VERSION ""

NS_ :

BS_:

BU_: CH DIPF DIPR ETH FC HVI HVS PARTY SDCV VEH VIRT

BO_ 568 UI_driverAssistMapData: 8 CH
 SG_ UI_mapDataChecksum : 56|8@1+ (1,0) [0|255] ""  das
 SG_ UI_mapDataCounter : 52|4@1+ (1,0) [0|15] ""  das
 SG_ UI_scaEnabled : 51|1@1+ (1,0) [0|1] ""  das
 SG_ UI_pmmEnabled : 50|1@1+ (1,0) [0|1] ""  das
 SG_ UI_autosteerRestricted : 49|1@1+ (1,0) [0|1] ""  das
 SG_ UI_acceptBottsDots : 48|1@1+ (1,0) [0|1] ""  das
 SG_ UI_rejectHandsOn : 47|1@1+ (1,0) [0|1] ""  das
 SG_ UI_rejectAutosteer : 46|1@1+ (1,0) [0|1] ""  das
 SG_ UI_rejectRightFreeSpace : 45|1@1+ (1,0) [0|1] ""  das
 SG_ UI_rejectLeftFreeSpace : 44|1@1+ (1,0) [0|1] ""  das
 SG_ UI_rejectNav : 43|1@1+ (1,0) [0|1] ""  das
 SG_ UI_rejectHPP : 42|1@1+ (1,0) [0|1] ""  das
 SG_ UI_rejectRightLane : 41|1@1+ (1,0) [0|1] ""  das
 SG_ UI_rejectLeftLane : 40|1@1+ (1,0) [0|1] ""  das
 SG_ UI_nextBranchRightOffRamp : 39|1@1+ (1,0) [0|1] ""  das
 SG_ UI_nextBranchLeftOffRamp : 38|1@1+ (1,0) [0|1] ""  das
 SG_ UI_controlledAccess : 37|1@1+ (1,0) [0|1] ""  das
 SG_ UI_nextBranchDist : 32|5@1+ (10,0) [0|300] "m"  das
 SG_ UI_perpendicularAutoparkEnabled : 31|1@1+ (1,0) [0|1] ""  das
 SG_ UI_parallelAutoparkEnabled : 30|1@1+ (1,0) [0|1] ""  das
 SG_ UI_navRouteActive : 29|1@1+ (1,0) [0|1] ""  das
 SG_ UI_gpsRoadMatch : 28|1@1+ (1,0) [0|1] ""  das
 SG_ UI_streetCount : 26|2@1+ (1,0) [0|3] ""  das
 SG_ UI_countryCode : 16|10@1+ (1,0) [0|1023] ""  das
 SG_ UI_mapSpeedLimitType : 13|3@1+ (1,0) [0|7] ""  das
 SG_ UI_mapSpeedLimit : 8|5@1+ (1,0) [0|31] ""  das
 SG_ UI_mapSpeedUnits : 7|1@1+ (1,0) [0|1] ""  das
 SG_ UI_inSuperchargerGeofence : 6|1@1+ (1,0) [0|1] ""  das
 SG_ UI_roadClass : 3|3@1+ (1,0) [0|6] ""  das
 SG_ UI_mapSpeedLimitDependency : 0|3@1+ (1,0) [0|7] ""  das

BO_ 945 DAS_telemetryFurniture: 8 CH
 SG_ DAS_TF_isTeslaMain m1 : 60|1@1+ (1,0) [0|1] ""  gtw
 SG_ DAS_TF_isMain m1 : 59|1@1+ (1,0) [0|1] ""  gtw
 SG_ DAS_TF_transmissionStatus m1 : 57|2@1+ (1,0) [0|3] ""  gtw
 SG_ DAS_TF_orientation m1 : 55|2@1+ (1,0) [0|3] ""  gtw
 SG_ DAS_TF_shape m1 : 52|3@1+ (1,0) [0|7] ""  gtw
 SG_ DAS_TF_color m1 : 49|3@1+ (1,0) [0|7] ""  gtw
 SG_ DAS_TF_furnitureType m0 : 42|3@1+ (1,0) [0|7] ""  gtw
 SG_ DAS_TF_ttc m2 : 39|7@1+ (0.1,0) [0|12.7] "s"  gtw
 SG_ DAS_TF_timeOfDay m0 : 39|3@1+ (1,0) [0|7] ""  gtw
 SG_ DAS_TF_height m1 : 37|12@1+ (0.05,0) [0|204.75] "m"  gtw
 SG_ DAS_TF_cipvDist m0 : 30|9@1+ (0.1,0) [0|51.1] "m"  gtw
 SG_ DAS_TF_stopLineDist m2 : 28|11@1+ (0.1,-10) [-10|194.7] "m"  gtw
 SG_ DAS_TF_rlType m0 : 27|3@1+ (1,0) [0|7] ""  gtw
 SG_ DAS_TF_lateralDist m1 : 25|12@1+ (0.1,-204.8) [-204.8|204.7] "m"  gtw
 SG_ DAS_TF_llType m0 : 24|3@1+ (1,0) [0|7] ""  gtw
 SG_ DAS_TF_juncDist m2 : 17|11@1+ (0.2,-20) [-20|389.4] "m"  gtw
 SG_ DAS_TF_juncStatus m2 : 13|4@1+ (1,0) [0|15] ""  gtw
 SG_ DAS_TF_longitudinalDist m1 : 13|12@1+ (0.1,0) [0|409.5] "m"  gtw
 SG_ DAS_TF_distTraveled m0 : 13|11@1+ (0.1,0) [0|204.7] "m"  gtw
 SG_ DAS_TF_furnitureIndex2 m2 : 5|8@1+ (1,0) [0|255] ""  gtw
 SG_ DAS_TF_furnitureIndex1 m1 : 5|8@1+ (1,0) [0|255] ""  gtw
 SG_ DAS_TF_furnitureIndex0 m0 : 5|8@1+ (1,0) [0|255] ""  gtw
 SG_ DAS_TF_multiplexer M : 0|5@1+ (1,0) [0|2] ""  gtw

BO_ 952 UI_tpmsRCPsetting: 8 CH
 SG_ UI_setRCPRear : 24|8@1+ (0.025,0) [0|6.375] "bar"  tpms
 SG_ UI_setRCPFront : 16|8@1+ (0.025,0) [0|6.375] "bar"  tpms

BO_ 1282 RADC_alertMatrix0: 8 CH
 SG_ RADC_a055_blockageInfo_Frame_2 : 55|1@1+ (1,0) [0|1] ""  gtw
 SG_ RADC_a054_blockageInfo_Frame_1 : 54|1@1+ (1,0) [0|1] ""  gtw
 SG_ RADC_a053_emError : 53|1@1+ (1,0) [0|1] ""  gtw
 SG_ RADC_a052_mismatcRadPos : 52|1@1+ (1,0) [0|1] ""  gtw
 SG_ RADC_a051_mismatchEPASType : 51|1@1+ (1,0) [0|1] ""  gtw
 SG_ RADC_a050_mismatchCountry : 50|1@1+ (1,0) [0|1] ""  gtw
 SG_ RADC_a049_mismatchFourWheelDrive : 49|1@1+ (1,0) [0|1] ""  gtw
 SG_ RADC_a048_mismatchAirSuspension : 48|1@1+ (1,0) [0|1] ""  gtw
 SG_ RADC_a047_mismatchChassisType : 47|1@1+ (1,0) [0|1] ""  gtw
 SG_ RADC_a046_wheelSpeedsErr : 46|1@1+ (1,0) [0|1] ""  gtw
 SG_ RADC_a045_vehicleStateErr : 45|1@1+ (1,0) [0|1] ""  gtw
 SG_ RADC_a044_steeringWheelAngleErr : 44|1@1+ (1,0) [0|1] ""  gtw
 SG_ RADC_a043_inertialSignalsErr : 43|1@1+ (1,0) [0|1] ""  gtw
 SG_ RADC_a042_carConfigErr : 42|1@1+ (1,0) [0|1] ""  gtw
 SG_ RADC_a041_vinErr : 41|1@1+ (1,0) [0|1] ""  gtw
 SG_ RADC_a040_wheelSpeedsMIA : 40|1@1+ (1,0) [0|1] ""  gtw
 SG_ RADC_a039_vehicleStateMIA : 39|1@1+ (1,0) [0|1] ""  gtw
 SG_ RADC_a038_steeringWheelAngleMIA : 38|1@1+ (1,0) [0|1] ""  gtw
 SG_ RADC_a037_inertialSignalsMIA : 37|1@1+ (1,0) [0|1] ""  gtw
 SG_ RADC_a036_carConfigMIA : 36|1@1+ (1,0) [0|1] ""  gtw
 SG_ RADC_a035_vinMIA : 35|1@1+ (1,0) [0|1] ""  gtw
 SG_ RADC_a034_vehDynamicsError : 34|1@1+ (1,0) [0|1] ""  gtw
 SG_ RADC_a033_sensorNeverAligned : 33|1@1+ (1,0) [0|1] ""  gtw
 SG_ RADC_a032_sensorBlocked : 32|1@1+ (1,0) [0|1] ""  gtw
 SG_ RADC_a031_sensorMisaligned : 31|1@1+ (1,0) [0|1] ""  gtw
 SG_ RADC_a030_rspError : 30|1@1+ (1,0) [0|1] ""  gtw
 SG_ RADC_a029_rhcError : 29|1@1+ (1,0) [0|1] ""  gtw
 SG_ RADC_a028_rfChipError : 28|1@1+ (1,0) [0|1] ""  gtw
 SG_ RADC_a027_nvmFailure : 27|1@1+ (1,0) [0|1] ""  gtw
 SG_ RADC_a026_underVoltage : 26|1@1+ (1,0) [0|1] ""  gtw
 SG_ RADC_a025_overVoltage : 25|1@1+ (1,0) [0|1] ""  gtw
 SG_ RADC_a024_underTempCrit : 24|1@1+ (1,0) [0|1] ""  gtw
 SG_ RADC_a023_underTemp : 23|1@1+ (1,0) [0|1] ""  gtw
 SG_ RADC_a022_tempImplausible : 22|1@1+ (1,0) [0|1] ""  gtw
 SG_ RADC_a021_overTempCrit : 21|1@1+ (1,0) [0|1] ""  gtw
 SG_ RADC_a020_overTemp : 20|1@1+ (1,0) [0|1] ""  gtw
 SG_ RADC_a019_internalSoftwareFault : 19|1@1+ (1,0) [0|1] ""  gtw
 SG_ RADC_a018_internalHardwareFault : 18|1@1+ (1,0) [0|1] ""  gtw
 SG_ RADC_a017_adcUnderVolt : 17|1@1+ (1,0) [0|1] ""  gtw
 SG_ RADC_a016_adcOverVolt : 16|1@1+ (1,0) [0|1] ""  gtw
 SG_ RADC_a015_fctSenInterference : 15|1@1+ (1,0) [0|1] ""  gtw
 SG_ RADC_a014_fctSelfTestNotDone : 14|1@1+ (1,0) [0|1] ""  gtw
 SG_ RADC_a013_ecuWdgError : 13|1@1+ (1,0) [0|1] ""  gtw
 SG_ RADC_a012_ecuSpiError : 12|1@1+ (1,0) [0|1] ""  gtw
 SG_ RADC_a011_ecuMcemError : 11|1@1+ (1,0) [0|1] ""  gtw
 SG_ RADC_a010_ecuIoHwAbError : 10|1@1+ (1,0) [0|1] ""  gtw
 SG_ RADC_a009_plantModeActive : 9|1@1+ (1,0) [0|1] ""  gtw
 SG_ RADC_a008_ecuHwSwInterlock : 8|1@1+ (1,0) [0|1] ""  gtw
 SG_ RADC_a007_ecuGptCheckError : 7|1@1+ (1,0) [0|1] ""  gtw
 SG_ RADC_a006_ecuFimError : 6|1@1+ (1,0) [0|1] ""  gtw
 SG_ RADC_a005_ecuEcuMError : 5|1@1+ (1,0) [0|1] ""  gtw
 SG_ RADC_a004_ecuCrcHwError : 4|1@1+ (1,0) [0|1] ""  gtw
 SG_ RADC_a003_ecuBistDisabled : 3|1@1+ (1,0) [0|1] ""  gtw
 SG_ RADC_a002_ecuAdcError : 2|1@1+ (1,0) [0|1] ""  gtw
 SG_ RADC_a001_can1BusOff : 1|1@1+ (1,0) [0|1] ""  gtw

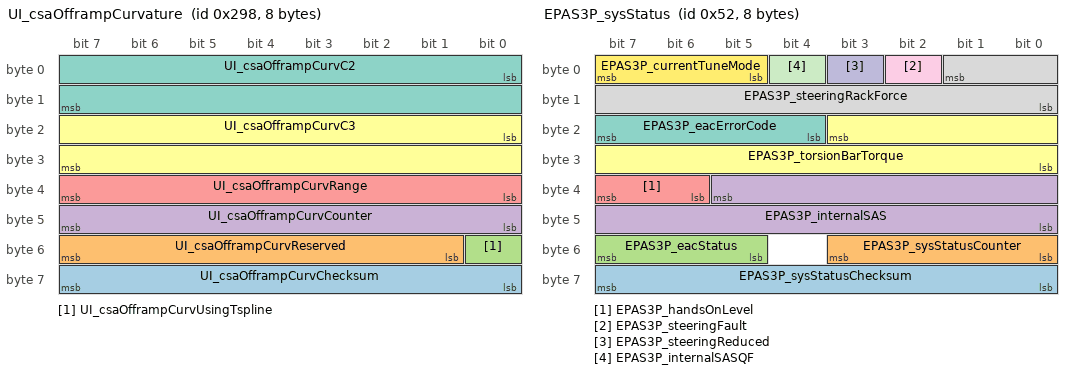
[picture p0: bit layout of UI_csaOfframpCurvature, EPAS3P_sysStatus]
BO_ 664 UI_csaOfframpCurvature: 8 CH
 SG_ UI_csaOfframpCurvChecksum : 56|8@1+ (1,0) [0|255] ""  X
 SG_ UI_csaOfframpCurvReserved : 49|7@1+ (1,0) [0|127] ""  X
 SG_ UI_csaOfframpCurvUsingTspline : 48|1@1+ (1,0) [0|1] ""  das
 SG_ UI_csaOfframpCurvCounter : 40|8@1+ (1,0) [0|255] ""  X
 SG_ UI_csaOfframpCurvRange : 32|8@1+ (2,0) [0|510] "m"  das
 SG_ UI_csaOfframpCurvC3 : 16|16@1- (4e-09,0.0) [-0.000131072|0.000131068] "1/m2"  das
 SG_ UI_csaOfframpCurvC2 : 0|16@1- (1e-06,0.0) [-0.032768|0.032767] "1/m"  das

BO_ 1535 TPMS_bootID: 8 CH
 SG_ TPMS_bootIdData : 0|64@1+ (1,0) [0|18446744073709551615] ""  gtwu

BO_ 1630 PARK_udsResponse: 8 CH
 SG_ PARK_udsResponseData : 0|64@1+ (1,0) [0|18446744073709551615] ""  gtw

BO_ 881 RCM_alertMatrix: 8 CH
 SG_ RCM_a059_buckle1stRowRight m0 : 63|1@1+ (1,0) [0|1] ""  gtw
 SG_ RCM_a058_buckle1stRowLeft m0 : 62|1@1+ (1,0) [0|1] ""  gtw
 SG_ RCM_a118_imuInPlaneAcceleration m1 : 62|1@1+ (1,0) [0|1] ""  gtw
 SG_ RCM_a057_driverOCS m0 : 61|1@1+ (1,0) [0|1] ""  gtw
 SG_ RCM_a117_imuVerticalAcceleration m1 : 61|1@1+ (1,0) [0|1] ""  gtw
 SG_ RCM_a116_imuLateralAcceleration m1 : 60|1@1+ (1,0) [0|1] ""  gtw
 SG_ RCM_a056_passengerFrontOCS m0 : 60|1@1+ (1,0) [0|1] ""  gtw
 SG_ RCM_a115_imuLinearAcceleration m1 : 59|1@1+ (1,0) [0|1] ""  gtw
 SG_ RCM_a055_inertialMeasurement m0 : 59|1@1+ (1,0) [0|1] ""  gtw
 SG_ RCM_a054_pressurePedProRight m0 : 58|1@1+ (1,0) [0|1] ""  gtw
 SG_ RCM_a114_imuRollRate m1 : 58|1@1+ (1,0) [0|1] ""  gtw
 SG_ RCM_a053_pressurePedProLeft m0 : 57|1@1+ (1,0) [0|1] ""  gtw
 SG_ RCM_a113_imuPitchRate m1 : 57|1@1+ (1,0) [0|1] ""  gtw
 SG_ RCM_a112_imuYawRate m1 : 56|1@1+ (1,0) [0|1] ""  gtw
 SG_ RCM_a052_pressureFrontRtDoor m0 : 56|1@1+ (1,0) [0|1] ""  gtw
 SG_ RCM_a111_diagnosticsEnabled m1 : 55|1@1+ (1,0) [0|1] ""  gtw
 SG_ RCM_a051_pressureFrontLftDoor m0 : 55|1@1+ (1,0) [0|1] ""  gtw
 SG_ RCM_a050_upFrontSensorCenter m0 : 54|1@1+ (1,0) [0|1] ""  gtw
 SG_ RCM_a110_factoryMode m1 : 54|1@1+ (1,0) [0|1] ""  gtw
 SG_ RCM_a109_abuseImmunity m1 : 53|1@1+ (1,0) [0|1] ""  gtw
 SG_ RCM_a049_sideAccelCPillarRight m0 : 53|1@1+ (1,0) [0|1] ""  gtw
 SG_ RCM_a108_crashAlgoWakeup m1 : 52|1@1+ (1,0) [0|1] ""  gtw
 SG_ RCM_a048_sideAccelCPillarLeft m0 : 52|1@1+ (1,0) [0|1] ""  gtw
 SG_ RCM_a047_sideAccelBPillarRight m0 : 51|1@1+ (1,0) [0|1] ""  gtw
 SG_ RCM_a107_imuVertAccOffstCompLim m1 : 51|1@1+ (1,0) [0|1] ""  gtw
 SG_ RCM_a106_imuLatAccOffstCompLim m1 : 50|1@1+ (1,0) [0|1] ""  gtw
 SG_ RCM_a046_sideAccelBPillarLeft m0 : 50|1@1+ (1,0) [0|1] ""  gtw
 SG_ RCM_a105_imuLongAccOffstCompLim m1 : 49|1@1+ (1,0) [0|1] ""  gtw
 SG_ RCM_a045_upFrontSensorRight m0 : 49|1@1+ (1,0) [0|1] ""  gtw
 SG_ RCM_a104_imuRollR8OffstCompLim m1 : 48|1@1+ (1,0) [0|1] ""  gtw
 SG_ RCM_a044_upFrontSensorLeft m0 : 48|1@1+ (1,0) [0|1] ""  gtw
 SG_ RCM_a043_ens2Line m0 : 47|1@1+ (1,0) [0|1] ""  gtw
 SG_ RCM_a103_imuPtchR8OffstCompLim m1 : 47|1@1+ (1,0) [0|1] ""  gtw
 SG_ RCM_a102_imuYawR8OffstCompLim m1 : 46|1@1+ (1,0) [0|1] ""  gtw
 SG_ RCM_a042_ens1Line m0 : 46|1@1+ (1,0) [0|1] ""  gtw
 SG_ RCM_a101_idfSystem m1 : 45|1@1+ (1,0) [0|1] ""  gtw
 SG_ RCM_a041_hoodActuatorLeft m0 : 45|1@1+ (1,0) [0|1] ""  gtw
 SG_ RCM_a040_hoodActuatorRight m0 : 44|1@1+ (1,0) [0|1] ""  gtw
 SG_ RCM_a100_comDIsystemStatus m1 : 44|1@1+ (1,0) [0|1] ""  gtw
 SG_ RCM_a099_comDItorque m1 : 43|1@1+ (1,0) [0|1] ""  gtw
 SG_ RCM_a039_unusedB m0 : 43|1@1+ (1,0) [0|1] ""  gtw
 SG_ RCM_a038_unusedA m0 : 42|1@1+ (1,0) [0|1] ""  gtw
 SG_ RCM_a098_comDIchassisControl m1 : 42|1@1+ (1,0) [0|1] ""  gtw
 SG_ RCM_a097_comDIspeed m1 : 41|1@1+ (1,0) [0|1] ""  gtw
 SG_ RCM_a037_curAB2ndRowRight m0 : 41|1@1+ (1,0) [0|1] ""  gtw
 SG_ RCM_a036_curAB2ndRowLeft m0 : 40|1@1+ (1,0) [0|1] ""  gtw
 SG_ RCM_a096_comESPwheelSpeeds m1 : 40|1@1+ (1,0) [0|1] ""  gtw
 SG_ RCM_a035_preten2ndRowRight m0 : 39|1@1+ (1,0) [0|1] ""  gtw
 SG_ RCM_a095_comESPstatus m1 : 39|1@1+ (1,0) [0|1] ""  gtw
 SG_ RCM_a034_preten2ndRowLeft m0 : 38|1@1+ (1,0) [0|1] ""  gtw
 SG_ RCM_a094_comVCRIGHTStatus m1 : 38|1@1+ (1,0) [0|1] ""  gtw
 SG_ RCM_a033_curtainABRight m0 : 37|1@1+ (1,0) [0|1] ""  gtw
 SG_ RCM_a093_comVCLEFTStatus m1 : 37|1@1+ (1,0) [0|1] ""  gtw
 SG_ RCM_a092_comDASISF m1 : 36|1@1+ (1,0) [0|1] ""  gtw
 SG_ RCM_a032_curtainABLeft m0 : 36|1@1+ (1,0) [0|1] ""  gtw
 SG_ RCM_a031_frontCenterAirbag m0 : 35|1@1+ (1,0) [0|1] ""  gtw
 SG_ RCM_a091_comEPAS3PsysStatus m1 : 35|1@1+ (1,0) [0|1] ""  gtw
 SG_ RCM_a030_farSideInboardAirbag m0 : 34|1@1+ (1,0) [0|1] ""  gtw
 SG_ RCM_a090_comPartyBusOff m1 : 34|1@1+ (1,0) [0|1] ""  gtw
 SG_ RCM_a029_driverABActiveVent m0 : 33|1@1+ (1,0) [0|1] ""  gtw
 SG_ RCM_a089_comCHCANPH3 m1 : 33|1@1+ (1,0) [0|1] ""  gtw
 SG_ RCM_a028_sideAB1stRowRight m0 : 32|1@1+ (1,0) [0|1] ""  gtw
 SG_ RCM_a088_comCHCANPH2 m1 : 32|1@1+ (1,0) [0|1] ""  gtw
 SG_ RCM_a027_sideAB1stRowLeft m0 : 31|1@1+ (1,0) [0|1] ""  gtw
 SG_ RCM_a087_comCANSilent m1 : 31|1@1+ (1,0) [0|1] ""  gtw
 SG_ RCM_a086_comVINMIA m1 : 30|1@1+ (1,0) [0|1] ""  gtw
 SG_ RCM_a026_kneeABFrontPassenger m0 : 30|1@1+ (1,0) [0|1] ""  gtw
 SG_ RCM_a025_kneeABDriver m0 : 29|1@1+ (1,0) [0|1] ""  gtw
 SG_ RCM_a085_comGTWCarConfig m1 : 29|1@1+ (1,0) [0|1] ""  gtw
 SG_ RCM_a024_loadLimiterRightSide m0 : 28|1@1+ (1,0) [0|1] ""  gtw
 SG_ RCM_a084_comTPMSStatus m1 : 28|1@1+ (1,0) [0|1] ""  gtw
 SG_ RCM_a023_loadLimiterLeftSide m0 : 27|1@1+ (1,0) [0|1] ""  gtw
 SG_ RCM_a083_comGTWCarState m1 : 27|1@1+ (1,0) [0|1] ""  gtw
 SG_ RCM_a022_pretenLapFrontRight m0 : 26|1@1+ (1,0) [0|1] ""  gtw
 SG_ RCM_a082_comUIodo m1 : 26|1@1+ (1,0) [0|1] ""  gtw
 SG_ RCM_a021_pretenLapFrontLeft m0 : 25|1@1+ (1,0) [0|1] ""  gtw
 SG_ RCM_a081_comVCFRONTLVPwr m1 : 25|1@1+ (1,0) [0|1] ""  gtw
 SG_ RCM_a080_comGTWACS m1 : 24|1@1+ (1,0) [0|1] ""  gtw
 SG_ RCM_a020_pretenShldFrontRight m0 : 24|1@1+ (1,0) [0|1] ""  gtw
 SG_ RCM_a019_pretenShldrFrontLeft m0 : 23|1@1+ (1,0) [0|1] ""  gtw
 SG_ RCM_a079_comOCS1DStatus m1 : 23|1@1+ (1,0) [0|1] ""  gtw
 SG_ RCM_a078_comOCS1PStatus m1 : 22|1@1+ (1,0) [0|1] ""  gtw
 SG_ RCM_a018_passengerActiveVent m0 : 22|1@1+ (1,0) [0|1] ""  gtw
 SG_ RCM_a077_comEPBRStatus m1 : 21|1@1+ (1,0) [0|1] ""  gtw
 SG_ RCM_a017_passABStage2 m0 : 21|1@1+ (1,0) [0|1] ""  gtw
 SG_ RCM_a016_passABStage1 m0 : 20|1@1+ (1,0) [0|1] ""  gtw
 SG_ RCM_a076_comEPBLStatus m1 : 20|1@1+ (1,0) [0|1] ""  gtw
 SG_ RCM_a075_comCHCANPH6 m1 : 19|1@1+ (1,0) [0|1] ""  gtw
 SG_ RCM_a015_driverABStage2 m0 : 19|1@1+ (1,0) [0|1] ""  gtw
 SG_ RCM_a014_driverABStage1 m0 : 18|1@1+ (1,0) [0|1] ""  gtw
 SG_ RCM_a074_comCHCANPH5 m1 : 18|1@1+ (1,0) [0|1] ""  gtw
 SG_ RCM_a073_comCHCANPH4 m1 : 17|1@1+ (1,0) [0|1] ""  gtw
 SG_ RCM_a013_driverOrientation m0 : 17|1@1+ (1,0) [0|1] ""  gtw
 SG_ RCM_a072_comUnused m1 : 16|1@1+ (1,0) [0|1] ""  gtw
 SG_ RCM_a012_vinStorage m0 : 16|1@1+ (1,0) [0|1] ""  gtw
 SG_ RCM_a011_eepromDataLocked m0 : 15|1@1+ (1,0) [0|1] ""  gtw
 SG_ RCM_a071_comCHCANPH9 m1 : 15|1@1+ (1,0) [0|1] ""  gtw
 SG_ RCM_a010_scmDisabled m0 : 14|1@1+ (1,0) [0|1] ""  gtw
 SG_ RCM_a070_comCHCANPH8 m1 : 14|1@1+ (1,0) [0|1] ""  gtw
 SG_ RCM_a069_comCHCANPH7 m1 : 13|1@1+ (1,0) [0|1] ""  gtw
 SG_ RCM_a009_reprogramLimit m0 : 13|1@1+ (1,0) [0|1] ""  gtw
 SG_ RCM_a068_comChassisBusOff m1 : 12|1@1+ (1,0) [0|1] ""  gtw
 SG_ RCM_a008_powerSupplyInternal m0 : 12|1@1+ (1,0) [0|1] ""  gtw
 SG_ RCM_a007_powerSupplyExternal m0 : 11|1@1+ (1,0) [0|1] ""  gtw
 SG_ RCM_a067_comCANInitFailure m1 : 11|1@1+ (1,0) [0|1] ""  gtw
 SG_ RCM_a006_batteryVoltageRange m0 : 10|1@1+ (1,0) [0|1] ""  gtw
 SG_ RCM_a066_seatBackSw2ndRowLeft m1 : 10|1@1+ (1,0) [0|1] ""  gtw
 SG_ RCM_a005_crcError m0 : 9|1@1+ (1,0) [0|1] ""  gtw
 SG_ RCM_a065_driverOrientConfigPin m1 : 9|1@1+ (1,0) [0|1] ""  gtw
 SG_ RCM_a064_hardwareCodingPin1 m1 : 8|1@1+ (1,0) [0|1] ""  gtw
 SG_ RCM_a004_internalFault m0 : 8|1@1+ (1,0) [0|1] ""  gtw
 SG_ RCM_a063_sbsw2ndRowRight m1 : 7|1@1+ (1,0) [0|1] ""  gtw
 SG_ RCM_a003_warningIndicator m0 : 7|1@1+ (1,0) [0|1] ""  gtw
 SG_ RCM_a002_airbagsNotArmed m0 : 6|1@1+ (1,0) [0|1] ""  gtw
 SG_ RCM_a062_alrSwitch m1 : 6|1@1+ (1,0) [0|1] ""  gtw
 SG_ RCM_a061_stpsRight m1 : 5|1@1+ (1,0) [0|1] ""  gtw
 SG_ RCM_a001_nearDeploy m0 : 5|1@1+ (1,0) [0|1] ""  gtw
 SG_ RCM_a000_crashDetected m0 : 4|1@1+ (1,0) [0|1] ""  gtw
 SG_ RCM_a060_stpsLeft m1 : 4|1@1+ (1,0) [0|1] ""  gtw
 SG_ RCM_matrixIndex M : 0|4@1+ (1,0) [0|15] ""  gtw

BO_ 82 EPAS3P_sysStatus: 8 CH
 SG_ EPAS3P_sysStatusChecksum : 63|8@0+ (1,0) [0|255] ""  park
 SG_ EPAS3P_sysStatusCounter : 51|4@0+ (1,0) [0|15] ""  park
 SG_ EPAS3P_eacStatus : 55|3@0+ (1,0) [0|7] ""  park
 SG_ EPAS3P_internalSAS : 37|14@0+ (0.1,-819.2) [-819.2|819] "deg"  park
 SG_ EPAS3P_handsOnLevel : 39|2@0+ (1,0) [0|3] ""  park
 SG_ EPAS3P_torsionBarTorque : 19|12@0+ (0.01,-20.5) [-20.5|20.45] "Nm"  park
 SG_ EPAS3P_eacErrorCode : 23|4@0+ (1,0) [0|15] ""  park
 SG_ EPAS3P_steeringRackForce : 1|10@0+ (50,-25575) [-25575|25575] "N"  park
 SG_ EPAS3P_steeringFault : 2|1@0+ (1,0) [0|1] ""  park
 SG_ EPAS3P_steeringReduced : 3|1@0+ (1,0) [0|1] ""  park
 SG_ EPAS3P_internalSASQF : 4|1@0+ (1,0) [0|1] ""  park
 SG_ EPAS3P_currentTuneMode : 7|3@0+ (1,0) [0|5] ""  park

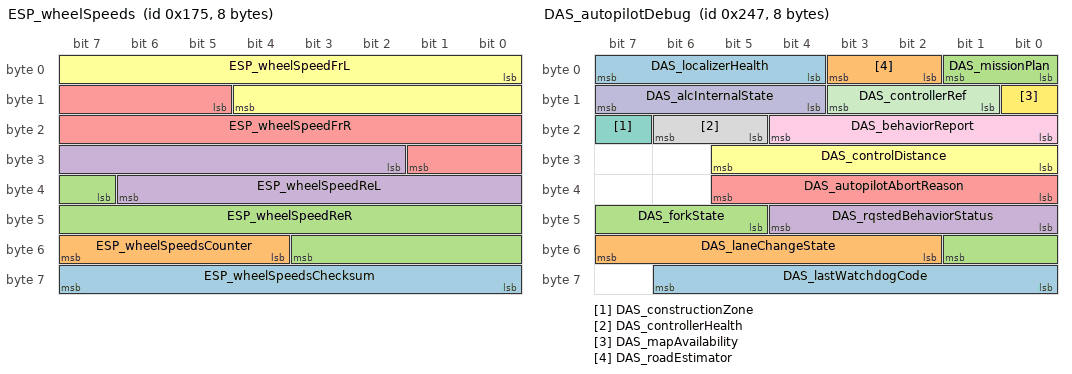
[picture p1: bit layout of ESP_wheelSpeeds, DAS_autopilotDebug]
BO_ 373 ESP_wheelSpeeds: 8 CH
 SG_ ESP_wheelSpeedsChecksum : 56|8@1+ (1,0) [0|255] ""  das
 SG_ ESP_wheelSpeedsCounter : 52|4@1+ (1,0) [0|15] ""  das
 SG_ ESP_wheelSpeedReR : 39|13@1+ (0.04,0) [0|327.64] "km/h"  das
 SG_ ESP_wheelSpeedReL : 26|13@1+ (0.04,0) [0|327.64] "km/h"  das
 SG_ ESP_wheelSpeedFrR : 13|13@1+ (0.04,0) [0|327.64] "km/h"  das
 SG_ ESP_wheelSpeedFrL : 0|13@1+ (0.04,0) [0|327.64] "km/h"  das

BO_ 873 APP_warningMatrix1: 8 CH
 SG_ APP_w106_torsionBarOffset : 41|1@1+ (1,0) [0|1] ""  gtw
 SG_ APP_w105_DEPRECATED : 40|1@1+ (1,0) [0|1] ""  gtw
 SG_ APP_w104_DEPRECATED : 39|1@1+ (1,0) [0|1] ""  gtw
 SG_ APP_w103_robExperimentalAEB : 38|1@1+ (1,0) [0|1] ""  gtw
 SG_ APP_w102_DEPRECATED : 37|1@1+ (1,0) [0|1] ""  gtw
 SG_ APP_w101_DEPRECATED : 36|1@1+ (1,0) [0|1] ""  gtw
 SG_ APP_w100_DEPRECATED : 35|1@1+ (1,0) [0|1] ""  gtw
 SG_ APP_w099_DEPRECATED : 34|1@1+ (1,0) [0|1] ""  gtw
 SG_ APP_w098_DEPRECATED : 33|1@1+ (1,0) [0|1] ""  gtw
 SG_ APP_w097_DEPRECATED : 32|1@1+ (1,0) [0|1] ""  gtw
 SG_ APP_w096_DEPRECATED : 31|1@1+ (1,0) [0|1] ""  gtw
 SG_ APP_w095_DEPRECATED : 30|1@1+ (1,0) [0|1] ""  gtw
 SG_ APP_w094_DEPRECATED : 29|1@1+ (1,0) [0|1] ""  gtw
 SG_ APP_w093_DEPRECATED : 28|1@1+ (1,0) [0|1] ""  gtw
 SG_ APP_w092_DEPRECATED : 27|1@1+ (1,0) [0|1] ""  gtw
 SG_ APP_w091_DEPRECATED : 26|1@1+ (1,0) [0|1] ""  gtw
 SG_ APP_w090_DEPRECATED : 25|1@1+ (1,0) [0|1] ""  gtw
 SG_ APP_w089_DEPRECATED : 24|1@1+ (1,0) [0|1] ""  gtw
 SG_ APP_w088_DEPRECATED : 23|1@1+ (1,0) [0|1] ""  gtw
 SG_ APP_w087_DEPRECATED : 22|1@1+ (1,0) [0|1] ""  gtw
 SG_ APP_w086_robCollision : 21|1@1+ (1,0) [0|1] ""  gtw
 SG_ APP_w085_pmmSteering : 20|1@1+ (1,0) [0|1] ""  gtw
 SG_ APP_w084_pmmIPSO : 19|1@1+ (1,0) [0|1] ""  gtw
 SG_ APP_w083_inPathRADObject : 18|1@1+ (1,0) [0|1] ""  gtw
 SG_ APP_w082_inPathFSviolation : 17|1@1+ (1,0) [0|1] ""  gtw
 SG_ APP_w081_pmmActiveBraking : 16|1@1+ (1,0) [0|1] ""  gtw
 SG_ APP_w080_accFailedActivation : 15|1@1+ (1,0) [0|1] ""  gtw
 SG_ APP_w079_edrAvailable : 14|1@1+ (1,0) [0|1] ""  gtw
 SG_ APP_w078_pmmActive2 : 13|1@1+ (1,0) [0|1] ""  gtw
 SG_ APP_w077_pmmActive : 12|1@1+ (1,0) [0|1] ""  gtw
 SG_ APP_w076_mobilEyeSetC : 11|1@1+ (1,0) [0|1] ""  gtw
 SG_ APP_w075_scMia : 10|1@1+ (1,0) [0|1] ""  gtw
 SG_ APP_w074_inPathStationaryObst : 9|1@1+ (1,0) [0|1] ""  gtw
 SG_ APP_w073_issueEscalatedLDW : 8|1@1+ (1,0) [0|1] ""  gtw
 SG_ APP_w072_selfparkComplete : 7|1@1+ (1,0) [0|1] ""  gtw
 SG_ APP_w071_selfparkStarted : 6|1@1+ (1,0) [0|1] ""  gtw
 SG_ APP_w070_apcIncompleteCal : 5|1@1+ (1,0) [0|1] ""  gtw
 SG_ APP_w069_apcSpaceMasked : 4|1@1+ (1,0) [0|1] ""  gtw
 SG_ APP_w068_vlInconsistency : 3|1@1+ (1,0) [0|1] ""  gtw
 SG_ APP_w067_steeringAlignment : 2|1@1+ (1,0) [0|1] ""  gtw
 SG_ APP_w066_deserializerLockLost : 1|1@1+ (1,0) [0|1] ""  gtw
 SG_ APP_w065_deserializerOvercurrent : 0|1@1+ (1,0) [0|1] ""  gtw

BO_ 744 EPBR_status: 8 CH
 SG_ EPBR_statusChecksum : 56|8@1+ (1,0) [0|255] ""  rcm
 SG_ EPBR_statusCounter : 52|4@1+ (1,0) [0|15] ""  rcm
 SG_ EPBR_blockDrive : 51|1@1+ (1,0) [0|1] ""  X
 SG_ EPBR_bothDisconnected : 50|1@1+ (1,0) [0|1] ""  X
 SG_ EPBR_winchModeAvailable : 49|1@1+ (1,0) [0|1] ""  X
 SG_ EPBR_hornRequest : 48|1@1+ (1,0) [0|1] ""  X
 SG_ EPBR_okToPark : 47|1@1+ (1,0) [0|1] ""  X
 SG_ EPBR_espPowerRequest : 46|1@1+ (1,0) [0|1] ""  X
 SG_ EPBR_winchModeTimer : 32|12@1+ (1,0) [0|4095] ""  X
 SG_ EPBR_brakeDiscWipeRequest : 30|2@1+ (1,0) [0|3] ""  X
 SG_ EPBR_cdpRequest : 27|1@1+ (1,0) [0|1] ""  X
 SG_ EPBR_updateMode : 24|1@1+ (1,0) [0|1] ""  X
 SG_ EPBR_winchModeActive : 23|1@1+ (1,0) [0|1] ""  X
 SG_ EPBR_requestUserConfirmation : 21|1@1+ (1,0) [0|1] ""  X
 SG_ EPBR_uiParkAvailable : 20|1@1+ (1,0) [0|1] ""  X
 SG_ EPBR_brakeHWConfigMismatch : 19|1@1+ (1,0) [0|1] ""  X
 SG_ EPBR_brakeLight : 18|1@1+ (1,0) [0|1] ""  X
 SG_ EPBR_summonEnabled : 17|1@1+ (1,0) [0|1] ""  X
 SG_ EPBR_telltale : 8|3@1+ (1,0) [0|7] ""  X
 SG_ EPBR_systemStatus : 0|4@1+ (1,0) [0|8] ""  park

BO_ 894 PARK_warningMatrix: 8 CH
 SG_ PARK_a060_s12_crossTalk m0 : 63|1@1+ (1,0) [0|1] ""  gtw
 SG_ PARK_a059_s12_blocked m0 : 62|1@1+ (1,0) [0|1] ""  gtw
 SG_ PARK_a058_s12_linCommError m0 : 61|1@1+ (1,0) [0|1] ""  gtw
 SG_ PARK_a057_s12_internalFail m0 : 60|1@1+ (1,0) [0|1] ""  gtw
 SG_ PARK_a056_s12_overTemp m0 : 59|1@1+ (1,0) [0|1] ""  gtw
 SG_ PARK_a055_s11_crossTalk m0 : 58|1@1+ (1,0) [0|1] ""  gtw
 SG_ PARK_a054_s11_blocked m0 : 57|1@1+ (1,0) [0|1] ""  gtw
 SG_ PARK_a053_s11_linCommError m0 : 56|1@1+ (1,0) [0|1] ""  gtw
 SG_ PARK_a052_s11_internalFail m0 : 55|1@1+ (1,0) [0|1] ""  gtw
 SG_ PARK_a051_s11_overTemp m0 : 54|1@1+ (1,0) [0|1] ""  gtw
 SG_ PARK_a050_s10_crossTalk m0 : 53|1@1+ (1,0) [0|1] ""  gtw
 SG_ PARK_a049_s10_blocked m0 : 52|1@1+ (1,0) [0|1] ""  gtw
 SG_ PARK_a048_s10_linCommError m0 : 51|1@1+ (1,0) [0|1] ""  gtw
 SG_ PARK_a047_s10_internalFail m0 : 50|1@1+ (1,0) [0|1] ""  gtw
 SG_ PARK_a046_s10_overTemp m0 : 49|1@1+ (1,0) [0|1] ""  gtw
 SG_ PARK_a045_s9_crossTalk m0 : 48|1@1+ (1,0) [0|1] ""  gtw
 SG_ PARK_a044_s9_blocked m0 : 47|1@1+ (1,0) [0|1] ""  gtw
 SG_ PARK_a043_s9_linCommError m0 : 46|1@1+ (1,0) [0|1] ""  gtw
 SG_ PARK_a042_s9_internalFail m0 : 45|1@1+ (1,0) [0|1] ""  gtw
 SG_ PARK_a041_s9_overTemp m0 : 44|1@1+ (1,0) [0|1] ""  gtw
 SG_ PARK_a040_s8_crossTalk m0 : 43|1@1+ (1,0) [0|1] ""  gtw
 SG_ PARK_a039_s8_blocked m0 : 42|1@1+ (1,0) [0|1] ""  gtw
 SG_ PARK_a038_s8_linCommError m0 : 41|1@1+ (1,0) [0|1] ""  gtw
 SG_ PARK_a037_s8_internalFail m0 : 40|1@1+ (1,0) [0|1] ""  gtw
 SG_ PARK_a036_s8_overTemp m0 : 39|1@1+ (1,0) [0|1] ""  gtw
 SG_ PARK_a035_s7_crossTalk m0 : 38|1@1+ (1,0) [0|1] ""  gtw
 SG_ PARK_a034_s7_blocked m0 : 37|1@1+ (1,0) [0|1] ""  gtw
 SG_ PARK_a033_s7_linCommError m0 : 36|1@1+ (1,0) [0|1] ""  gtw
 SG_ PARK_a032_s7_internalFail m0 : 35|1@1+ (1,0) [0|1] ""  gtw
 SG_ PARK_a031_s7_overTemp m0 : 34|1@1+ (1,0) [0|1] ""  gtw
 SG_ PARK_a030_s6_crossTalk m0 : 33|1@1+ (1,0) [0|1] ""  gtw
 SG_ PARK_a029_s6_blocked m0 : 32|1@1+ (1,0) [0|1] ""  gtw
 SG_ PARK_a028_s6_linCommError m0 : 31|1@1+ (1,0) [0|1] ""  gtw
 SG_ PARK_a027_s6_internalFail m0 : 30|1@1+ (1,0) [0|1] ""  gtw
 SG_ PARK_a086_nvmFault m1 : 29|1@1+ (1,0) [0|1] ""  gtw
 SG_ PARK_a026_s6_overTemp m0 : 29|1@1+ (1,0) [0|1] ""  gtw
 SG_ PARK_a025_s5_crossTalk m0 : 28|1@1+ (1,0) [0|1] ""  gtw
 SG_ PARK_a085_watchdogReset m1 : 28|1@1+ (1,0) [0|1] ""  gtw
 SG_ PARK_a024_s5_blocked m0 : 27|1@1+ (1,0) [0|1] ""  gtw
 SG_ PARK_a084_sccmError m1 : 27|1@1+ (1,0) [0|1] ""  gtw
 SG_ PARK_a023_s5_linCommError m0 : 26|1@1+ (1,0) [0|1] ""  gtw
 SG_ PARK_a083_vcFrontError m1 : 26|1@1+ (1,0) [0|1] ""  gtw
 SG_ PARK_a022_s5_internalFail m0 : 25|1@1+ (1,0) [0|1] ""  gtw
 SG_ PARK_a082_rcmError m1 : 25|1@1+ (1,0) [0|1] ""  gtw
 SG_ PARK_a021_s5_overTemp m0 : 24|1@1+ (1,0) [0|1] ""  gtw
 SG_ PARK_a081_espError m1 : 24|1@1+ (1,0) [0|1] ""  gtw
 SG_ PARK_a080_epbError m1 : 23|1@1+ (1,0) [0|1] ""  gtw
 SG_ PARK_a020_s4_crossTalk m0 : 23|1@1+ (1,0) [0|1] ""  gtw
 SG_ PARK_a019_s4_blocked m0 : 22|1@1+ (1,0) [0|1] ""  gtw
 SG_ PARK_a079_epasError m1 : 22|1@1+ (1,0) [0|1] ""  gtw
 SG_ PARK_a078_diError m1 : 21|1@1+ (1,0) [0|1] ""  gtw
 SG_ PARK_a018_s4_linCommError m0 : 21|1@1+ (1,0) [0|1] ""  gtw
 SG_ PARK_a017_s4_internalFail m0 : 20|1@1+ (1,0) [0|1] ""  gtw
 SG_ PARK_a077_dasError m1 : 20|1@1+ (1,0) [0|1] ""  gtw
 SG_ PARK_a016_s4_overTemp m0 : 19|1@1+ (1,0) [0|1] ""  gtw
 SG_ PARK_a076_vcFrontMia m1 : 19|1@1+ (1,0) [0|1] ""  gtw
 SG_ PARK_a015_s3_crossTalk m0 : 18|1@1+ (1,0) [0|1] ""  gtw
 SG_ PARK_a075_rcmMia m1 : 18|1@1+ (1,0) [0|1] ""  gtw
 SG_ PARK_a014_s3_blocked m0 : 17|1@1+ (1,0) [0|1] ""  gtw
 SG_ PARK_a074_espMia m1 : 17|1@1+ (1,0) [0|1] ""  gtw
 SG_ PARK_a013_s3_linCommError m0 : 16|1@1+ (1,0) [0|1] ""  gtw
 SG_ PARK_a073_epbMia m1 : 16|1@1+ (1,0) [0|1] ""  gtw
 SG_ PARK_a072_epasMia m1 : 15|1@1+ (1,0) [0|1] ""  gtw
 SG_ PARK_a012_s3_internalFail m0 : 15|1@1+ (1,0) [0|1] ""  gtw
 SG_ PARK_a071_diMia m1 : 14|1@1+ (1,0) [0|1] ""  gtw
 SG_ PARK_a011_s3_overTemp m0 : 14|1@1+ (1,0) [0|1] ""  gtw
 SG_ PARK_a070_sccmMia m1 : 13|1@1+ (1,0) [0|1] ""  gtw
 SG_ PARK_a010_s2_crossTalk m0 : 13|1@1+ (1,0) [0|1] ""  gtw
 SG_ PARK_a009_s2_blocked m0 : 12|1@1+ (1,0) [0|1] ""  gtw
 SG_ PARK_a069_dasMia m1 : 12|1@1+ (1,0) [0|1] ""  gtw
 SG_ PARK_a008_s2_linCommError m0 : 11|1@1+ (1,0) [0|1] ""  gtw
 SG_ PARK_a068_hardwareWatchDog m1 : 11|1@1+ (1,0) [0|1] ""  gtw
 SG_ PARK_a007_s2_internalFail m0 : 10|1@1+ (1,0) [0|1] ""  gtw
 SG_ PARK_a067_privateCANBusOff m1 : 10|1@1+ (1,0) [0|1] ""  gtw
 SG_ PARK_a006_s2_overTemp m0 : 9|1@1+ (1,0) [0|1] ""  gtw
 SG_ PARK_a066_calibrationMissing m1 : 9|1@1+ (1,0) [0|1] ""  gtw
 SG_ PARK_a005_s1_crossTalk m0 : 8|1@1+ (1,0) [0|1] ""  gtw
 SG_ PARK_a065_crcFault m1 : 8|1@1+ (1,0) [0|1] ""  gtw
 SG_ PARK_a064_ecuFault m1 : 7|1@1+ (1,0) [0|1] ""  gtw
 SG_ PARK_a004_s1_blocked m0 : 7|1@1+ (1,0) [0|1] ""  gtw
 SG_ PARK_a003_s1_linCommError m0 : 6|1@1+ (1,0) [0|1] ""  gtw
 SG_ PARK_a063_sensorVoltage m1 : 6|1@1+ (1,0) [0|1] ""  gtw
 SG_ PARK_a002_s1_internalFail m0 : 5|1@1+ (1,0) [0|1] ""  gtw
 SG_ PARK_a062_ecuOverVoltage m1 : 5|1@1+ (1,0) [0|1] ""  gtw
 SG_ PARK_a061_ecuUnderVoltage m1 : 4|1@1+ (1,0) [0|1] ""  gtw
 SG_ PARK_a001_s1_overTemp m0 : 4|1@1+ (1,0) [0|1] ""  gtw
 SG_ PARK_matrixIndex M : 0|4@1+ (1,0) [0|15] ""  gtw

BO_ 606 PARK_pscEnvSlot: 8 CH
 SG_ PARK_pscLeftParallelObj2Alpha m0 : 57|7@1+ (2,-128) [-128|127] "deg"  gtw
 SG_ PARK_pscRightParallelObj2Alpha m2 : 57|7@1+ (2,-128) [-128|127] "deg"  gtw
 SG_ PARK_pscLeftCrossObj2Alpha m1 : 57|7@1+ (2,-128) [-128|127] "deg"  gtw
 SG_ PARK_pscRightCrossObj2Alpha m3 : 57|7@1+ (2,-128) [-128|127] "deg"  gtw
 SG_ PARK_pscRightParallelObj2X m2 : 46|11@1+ (2,-2048) [-2048|2046] "cm"  gtw
 SG_ PARK_pscLeftParallelObj2X m0 : 46|11@1+ (2,-2048) [-2048|2046] "cm"  gtw
 SG_ PARK_pscLeftCrossObj2X m1 : 46|11@1+ (2,-2048) [-2048|2046] "cm"  gtw
 SG_ PARK_pscRightCrossObj2X m3 : 46|11@1+ (2,-2048) [-2048|2046] "cm"  gtw
 SG_ PARK_pscLeftCrossObj2Y m1 : 35|11@1+ (2,-2048) [-2048|2046] "cm"  gtw
 SG_ PARK_pscRightParallelObj2Y m2 : 35|11@1+ (2,-2048) [-2048|2046] "cm"  gtw
 SG_ PARK_pscLeftParallelObj2Y m0 : 35|11@1+ (2,-2048) [-2048|2046] "cm"  gtw
 SG_ PARK_pscRightCrossObj2Y m3 : 35|11@1+ (2,-2048) [-2048|2046] "cm"  gtw
 SG_ PARK_pscRightParallelObj1Alpha m2 : 25|7@1+ (2,-128) [-128|127] "deg"  gtw
 SG_ PARK_pscRightCrossObj1Alpha m3 : 25|7@1+ (2,-128) [-128|127] "deg"  gtw
 SG_ PARK_pscLeftCrossObj1Alpha m1 : 25|7@1+ (2,-128) [-128|127] "deg"  gtw
 SG_ PARK_pscLeftParallelObj1Alpha m0 : 25|7@1+ (2,-128) [-128|127] "deg"  gtw
 SG_ PARK_pscRightCrossObj1Y m3 : 14|11@1+ (2,-2048) [-2048|2046] "cm"  gtw
 SG_ PARK_pscRightParallelObj1Y m2 : 14|11@1+ (2,-2048) [-2048|2046] "cm"  gtw
 SG_ PARK_pscLeftParallelObj1Y m0 : 14|11@1+ (2,-2048) [-2048|2046] "cm"  gtw
 SG_ PARK_pscLeftCrossObj1Y m1 : 14|11@1+ (2,-2048) [-2048|2046] "cm"  gtw
 SG_ PARK_pscRightParallelObj1X m2 : 3|11@1+ (2,-2048) [-2048|2046] "cm"  gtw
 SG_ PARK_pscLeftParallelObj1X m0 : 3|11@1+ (2,-2048) [-2048|2046] "cm"  gtw
 SG_ PARK_pscRightCrossObj1X m3 : 3|11@1+ (2,-2048) [-2048|2046] "cm"  gtw
 SG_ PARK_pscLeftCrossObj1X m1 : 3|11@1+ (2,-2048) [-2048|2046] "cm"  gtw
 SG_ PARK_pscEnvSlotType M : 0|2@1+ (1,0) [0|3] ""  gtw

BO_ 1805 DBG_pcsControl: 8 CH
 SG_ DBG_pcs_PHB_pfcOvrEnable m23 : 63|1@1+ (1,0) [0|1] ""  X
 SG_ DBG_pcs_PHA_pfcOvrEnable m13 : 63|1@1+ (1,0) [0|1] ""  X
 SG_ DBG_pcs_PHC_pfcOvrEnable m33 : 63|1@1+ (1,0) [0|1] ""  X
 SG_ DBG_pcs_PHA_pfcEnable m13 : 62|1@1+ (1,0) [0|1] ""  X
 SG_ DBG_pcs_PHC_pfcEnable m33 : 62|1@1+ (1,0) [0|1] ""  X
 SG_ DBG_pcs_PHB_pfcEnable m23 : 62|1@1+ (1,0) [0|1] ""  X
 SG_ DBG_DCDC_fullShortEnable m103 : 56|1@1+ (1,0) [0|1] ""  X
 SG_ DBG_DCDC_Drv_FED_ns m102 : 54|10@1+ (1,0) [10|1024] "ns"  X
 SG_ DBG_pcs_PHC_scr_B_LO m33 : 51|1@1+ (1,0) [0|1] ""  X
 SG_ DBG_pcs_PHB_scr_B_LO m23 : 51|1@1+ (1,0) [0|1] ""  X
 SG_ DBG_pcs_PHA_scr_B_LO m13 : 51|1@1+ (1,0) [0|1] ""  X
 SG_ DBG_pcs_PHA_scr_B_HI m13 : 50|1@1+ (1,0) [0|1] ""  X
 SG_ DBG_pcs_PHB_llcOvrEnable m24 : 50|1@1+ (1,0) [0|1] ""  X
 SG_ DBG_pcs_PHC_scr_B_HI m33 : 50|1@1+ (1,0) [0|1] ""  X
 SG_ DBG_pcs_PHA_llcOvrEnable m14 : 50|1@1+ (1,0) [0|1] ""  X
 SG_ DBG_pcs_PHB_scr_B_HI m23 : 50|1@1+ (1,0) [0|1] ""  X
 SG_ DBG_pcs_PHC_llcOvrEnable m34 : 50|1@1+ (1,0) [0|1] ""  X
 SG_ DBG_pcs_PHB_llcEnable m24 : 49|1@1+ (1,0) [0|1] ""  X
 SG_ DBG_pcs_PHA_llcEnable m14 : 49|1@1+ (1,0) [0|1] ""  X
 SG_ DBG_pcs_PHA_scr_A_LO m13 : 49|1@1+ (1,0) [0|1] ""  X
 SG_ DBG_pcs_PHB_scr_A_LO m23 : 49|1@1+ (1,0) [0|1] ""  X
 SG_ DBG_pcs_PHC_scr_A_LO m33 : 49|1@1+ (1,0) [0|1] ""  X
 SG_ DBG_pcs_PHC_llcEnable m34 : 49|1@1+ (1,0) [0|1] ""  X
 SG_ DBG_pcs_PHB_scr_A_HI m23 : 48|1@1+ (1,0) [0|1] ""  X
 SG_ DBG_pcs_PHA_llcLimitMaxTime m14 : 48|1@1+ (1,0) [0|1] ""  X
 SG_ DBG_pcs_PHC_scr_A_HI m33 : 48|1@1+ (1,0) [0|1] ""  X
 SG_ DBG_pcs_PHB_llcLimitMaxTime m24 : 48|1@1+ (1,0) [0|1] ""  X
 SG_ DBG_pcs_PHA_scr_A_HI m13 : 48|1@1+ (1,0) [0|1] ""  X
 SG_ DBG_pcs_PHC_llcLimitMaxTime m34 : 48|1@1+ (1,0) [0|1] ""  X
 SG_ DBG_pcs_PH_gain_A m6 : 44|10@1+ (0.001,0) [0|0] "-"  X
 SG_ DBG_DCDC_Short_Time_ns m103 : 44|12@1+ (3.90625,0) [0|16000] "ns"  X
 SG_ DBG_DCDC_Drv_RED_ns m102 : 44|10@1+ (1,0) [10|1023] "ns"  X
 SG_ DBG_pcs_PHA_pfcDeadTime m13 : 40|8@1+ (10,0) [0|0] "ns"  X
 SG_ DBG_pcs_PHA_llcMaxTime m14 : 40|8@1+ (1,0) [0|255] "mS"  X
 SG_ DBG_DCDC_tCommTargetOverride m108 : 40|1@1+ (1,0) [0|1] ""  X
 SG_ DBG_pcs_PHC_pfcDeadTime m33 : 40|8@1+ (10,0) [0|0] "ns"  X
 SG_ DBG_pcs_PHB_llcMaxTime m24 : 40|8@1+ (1,0) [0|255] "mS"  X
 SG_ DBG_pcs_PHB_pfcDeadTime m23 : 40|8@1+ (10,0) [0|0] "ns"  X
 SG_ DBG_DCDC_fastCANDebugEn m100 : 40|2@1+ (1,0) [0|3] ""  X
 SG_ DBG_pcs_PHC_llcMaxTime m34 : 40|8@1+ (1,0) [0|255] "mS"  X
 SG_ DBG_DCDC_debugFloat2 m106 : 36|28@1+ (3.725290312e-09,0) [0|1] "-"  X
 SG_ DBG_DCDC_numCyclesToRun m100 : 32|8@1- (1,0) [-1|127] "-"  X
 SG_ DBG_DCDC_Rise_Comp_Thresh_Amps m101 : 32|16@1- (0.0003814697226,0) [-25|0] "A"  X
 SG_ DBG_DCDC_Short_DelayTime_ns m103 : 32|12@1+ (1,0) [0|4095] "ns"  X
 SG_ DBG_DCDC_Zero_Time_ns m102 : 32|12@1+ (3.90625,0) [0|16000] "ns"  X
 SG_ DBG_DCDC_vLoopKi m105 : 28|20@1+ (9.5367431640625e-07,0) [0|1] "A"  X
 SG_ DBG_pcs_PHC_llcForceBridgeBOff m38 : 26|1@1+ (1,0) [0|1] ""  X
 SG_ DBG_pcs_PHA_llcForceBridgeBOff m36 : 26|1@1+ (1,0) [0|1] ""  X
 SG_ DBG_pcs_PHB_llcForceBridgeBOff m37 : 26|1@1+ (1,0) [0|1] ""  X
 SG_ DBG_pcs_phCOvrPhMan m32 : 25|1@1+ (1,0) [0|1] ""  X
 SG_ DBG_pcs_phBOvrPhMan m22 : 25|1@1+ (1,0) [0|1] ""  X
 SG_ DBG_pcs_PHC_llcForceBridgeAOff m38 : 25|1@1+ (1,0) [0|1] ""  X
 SG_ DBG_pcs_phAOvrPhMan m12 : 25|1@1+ (1,0) [0|1] ""  X
 SG_ DBG_pcs_PHB_llcForceBridgeAOff m37 : 25|1@1+ (1,0) [0|1] ""  X
 SG_ DBG_pcs_PHA_llcForceBridgeAOff m36 : 25|1@1+ (1,0) [0|1] ""  X
 SG_ DBG_pcs_PHA_llcPhase m14 : 24|16@1+ (0.002,0) [0|0] "%"  X
 SG_ DBG_DCDC_dumpVloopDataLog m100 : 24|8@1+ (1,0) [0|255] ""  X
 SG_ DBG_pcs_PHB_llcPhase m24 : 24|16@1+ (0.002,0) [0|0] "%"  X
 SG_ DBG_pcs_PH_debugFloat2 m7 : 24|16@1+ (1e-05,0) [0|0.65535] "1"  X
 SG_ DBG_pcs_PHC_llcSysOvrEnable m38 : 24|1@1+ (1,0) [0|1] ""  X
 SG_ DBG_DCDC_tCommTarget_ns m108 : 24|16@1+ (0.15625,0) [0|10240] "ns"  X
 SG_ DBG_pcs_PHC_closedLoopEnable m32 : 24|1@1+ (1,0) [0|1] ""  X
 SG_ DBG_pcs_DCDC_slowDischargeSlewRa m114 : 24|16@1+ (0.1,0) [0|10000] "V/s"  X
 SG_ DBG_pcs_DCDC_prechargeVTarget m111 : 24|16@1- (0.1,0) [-550|550] "V"  X
 SG_ DBG_pcs_PHB_llcSysOvrEnable m37 : 24|1@1+ (1,0) [0|1] ""  X
 SG_ DBG_pcs_PHC_llcPhase m34 : 24|16@1+ (0.002,0) [0|0] "%"  X
 SG_ DBG_pcs_DCDC_pchgResOvrValue m113 : 24|12@1+ (0.1,0) [0|409.5] "kOhm"  X
 SG_ DBG_pcs_PHA_pfcDuty m13 : 24|16@1+ (0.002,0) [0|0] "%"  X
 SG_ DBG_pcs_PHB_closedLoopEnable m22 : 24|1@1+ (1,0) [0|1] ""  X
 SG_ DBG_pcs_PHA_closedLoopEnable m12 : 24|1@1+ (1,0) [0|1] ""  X
 SG_ DBG_pcs_PHB_pfcDuty m23 : 24|16@1+ (0.002,0) [0|0] "%"  X
 SG_ DBG_pcs_PH_gain_B m6 : 24|20@1+ (1e-06,0) [0|0] "-"  X
 SG_ DBG_pcs_PHA_llcSysOvrEnable m36 : 24|1@1+ (1,0) [0|1] ""  X
 SG_ DBG_pcs_PHC_pfcDuty m33 : 24|16@1+ (0.002,0) [0|0] "%"  X
 SG_ DBG_pcs_mfgEolPwmEnTest m111 : 21|1@1+ (1,0) [0|1] ""  X
 SG_ DBG_DCDC_Short_FED_ns m103 : 20|12@1+ (1,0) [10|4095] "ns"  X
 SG_ DBG_pcs_PH_useControlParams m6 : 20|1@1+ (1,0) [0|1] ""  X
 SG_ DBG_DCDC_Drv_DelayTime_ns m102 : 20|12@1+ (1,0) [0|4095] "ns"  X
 SG_ DBG_pcs_chgDebugAuthentication m5 : 17|6@1+ (1,0) [0|60] ""  X
 SG_ DBG_DCDC_subStateFaultTrigger m112 : 16|1@1+ (1,0) [0|1] ""  X
 SG_ DBG_pcs_chgGridConfigOvrEnable m5 : 16|1@1+ (1,0) [0|1] ""  X
 SG_ DBG_DCDC_dumpCLADataLog m100 : 16|8@1+ (1,0) [0|255] ""  X
 SG_ DBG_pcs_PHC_outputCurrentLimit m32 : 16|8@1+ (0.1,0) [0|0] "A"  X
 SG_ DBG_pcs_PH_daccSelect m6 : 16|4@1+ (1,0) [0|10] ""  X
 SG_ DBG_DCDC_uTarget m109 : 16|32@1+ (2.328306437e-10,0) [0|1] "-"  X
 SG_ DBG_pcs_dcdcLvGtDrvOvrEnable m41 : 16|1@1+ (1,0) [0|1] ""  X
 SG_ DBG_pcs_PHC_scrPosOn m8 : 16|1@1+ (1,0) [0|1] ""  X
 SG_ DBG_pcs_PHB_outputCurrentLimit m22 : 16|8@1+ (0.1,0) [0|0] "A"  X
 SG_ DBG_DCDC_Fall_Comp_Thresh_Amps m101 : 16|16@1+ (0.0003814697226,0) [0|25] "A"  X
 SG_ DBG_pcs_PHA_outputCurrentLimit m12 : 16|8@1+ (0.1,0) [0|0] "A"  X
 SG_ DBG_DCDC_subStateFaultRepeat m112 : 15|1@1+ (1,0) [0|1] ""  X
 SG_ DBG_pcs_dcdcLvGtDrvEnable m41 : 15|1@1+ (1,0) [0|1] ""  X
 SG_ DBG_pcs_PHC_scrNegOn m8 : 15|1@1+ (1,0) [0|1] ""  X
 SG_ DBG_pcs_PHB_scrPosOn m8 : 14|1@1+ (1,0) [0|1] ""  X
 SG_ DBG_pcs_scrRefEpwmEnable m41 : 14|1@1+ (1,0) [0|1] ""  X
 SG_ DBG_pcs_PHB_scrNegOn m8 : 13|1@1+ (1,0) [0|1] ""  X
 SG_ DBG_DCDC_subStateFaultType m112 : 13|2@1+ (1,0) [0|3] ""  X
 SG_ DBG_pcs_scrRefEpwmOvrEnable m41 : 13|1@1+ (1,0) [0|1] ""  X
 SG_ DBG_pcs_PH_dacaSelect m6 : 12|4@1+ (1,0) [0|10] ""  X
 SG_ DBG_pcs_PHB_tempSysOvrValue m37 : 12|12@1- (0.1,0) [-204.8|204.7] "C"  X
 SG_ DBG_pcs_5VL1Enable m41 : 12|1@1+ (1,0) [0|1] ""  X
 SG_ DBG_pcs_analogMuxInhibitInv m150 : 12|1@1+ (1,0) [0|1] ""  X
 SG_ DBG_pcs_PHC_tempSysOvrValue m38 : 12|12@1- (0.1,0) [-204.8|204.7] "C"  X
 SG_ DBG_pcs_PHA_scrPosOn m8 : 12|1@1+ (1,0) [0|1] ""  X
 SG_ DBG_pcs_PHA_tempSysOvrValue m36 : 12|12@1- (0.1,0) [-204.8|204.7] "C"  X
 SG_ DBG_pcs_chgGridConfigToOvr m5 : 12|4@1+ (1,0) [0|8] ""  X
 SG_ DBG_pcs_PHB_tempSysOvrEnable m37 : 11|1@1+ (1,0) [0|1] ""  X
 SG_ DBG_pcs_DCDC_12VSupportVTarget m111 : 11|10@1+ (0.01,9) [9|16] "V"  X
 SG_ DBG_pcs_chgDlogDumpRequest m5 : 11|1@1+ (1,0) [0|1] ""  X
 SG_ DBG_pcs_PHA_scrNegOn m8 : 11|1@1+ (1,0) [0|1] ""  X
 SG_ DBG_pcs_PHA_tempSysOvrEnable m36 : 11|1@1+ (1,0) [0|1] ""  X
 SG_ DBG_pcs_analogMuxSelC m150 : 11|1@1+ (1,0) [0|1] ""  X
 SG_ DBG_pcs_phCLogicPwrEnable m41 : 11|1@1+ (1,0) [0|1] ""  X
 SG_ DBG_pcs_PHC_tempSysOvrEnable m38 : 11|1@1+ (1,0) [0|1] ""  X
 SG_ DBG_pcs_analogMuxSelB m150 : 10|1@1+ (1,0) [0|1] ""  X
 SG_ DBG_pcs_PHC_clearFaults m5 : 10|1@1+ (1,0) [0|1] ""  X
 SG_ DBG_pcs_PH_daccPhaseSelect m6 : 10|2@1+ (1,0) [0|3] ""  X
 SG_ DBG_pcs_phBLogicPwrEnable m41 : 10|1@1+ (1,0) [0|1] ""  X
 SG_ DBG_pcs_PHC_pfcForceLowOff m38 : 10|1@1+ (1,0) [0|1] ""  X
 SG_ DBG_pcs_PHB_pfcForceLowOff m37 : 10|1@1+ (1,0) [0|1] ""  X
 SG_ DBG_pcs_PHA_pfcForceLowOff m36 : 10|1@1+ (1,0) [0|1] ""  X
 SG_ DBG_pcs_PHC_dcCirculationEnable m8 : 10|1@1+ (1,0) [0|1] ""  X
 SG_ DBG_pcs_DCDC_pchgCapOvrValue m113 : 9|12@1+ (0.1,0) [0|409.5] "uF"  X
 SG_ DBG_pcs_phALogicPwrEnable m41 : 9|1@1+ (1,0) [0|1] ""  X
 SG_ DBG_pcs_PHB_clearFaults m5 : 9|1@1+ (1,0) [0|1] ""  X
 SG_ DBG_pcs_PHA_pfcForceHighOff m36 : 9|1@1+ (1,0) [0|1] ""  X
 SG_ DBG_pcs_DCDC_tempSysOvrValue m110 : 9|12@1- (0.1,0) [-204.8|204.7] "C"  X
 SG_ DBG_pcs_envOverrideValue m39 : 9|3@1+ (1,0) [0|5] ""  X
 SG_ DBG_pcs_analogMuxSelA m150 : 9|1@1+ (1,0) [0|1] ""  X
 SG_ DBG_pcs_DCDC_dcdcMode m111 : 9|2@1+ (1,0) [0|3] ""  X
 SG_ DBG_pcs_PHB_pfcForceHighOff m37 : 9|1@1+ (1,0) [0|1] ""  X
 SG_ DBG_pcs_PHB_dcCirculationEnable m8 : 9|1@1+ (1,0) [0|1] ""  X
 SG_ DBG_pcs_PH_intBusV m9 : 9|9@1+ (1,0) [0|511] "V"  X
 SG_ DBG_pcs_PHC_pfcForceHighOff m38 : 9|1@1+ (1,0) [0|1] ""  X
 SG_ DBG_DCDC_debugFloat1 m106 : 8|28@1+ (3.725290312e-09,0) [0|1] "-"  X
 SG_ DBG_pcs_PHB_pfcFreq m23 : 8|16@1+ (0.005,0) [0|0] "kHz"  X
 SG_ DBG_DCDC_subStateFaultTarget m112 : 8|5@1+ (1,0) [0|17] ""  X
 SG_ DBG_DCDC_uTargetOverride m109 : 8|1@1+ (1,0) [0|1] ""  X
 SG_ DBG_pcs_PH_debugFloat1 m7 : 8|16@1+ (1e-05,0) [0|0.65535] "1"  X
 SG_ DBG_pcs_DCDC_slowDischargeTarget m114 : 8|16@1+ (0.1,0) [0|500] "V"  X
 SG_ DBG_pcs_PH_dacaPhaseSelect m6 : 8|2@1+ (1,0) [0|3] ""  X
 SG_ DBG_pcs_PHB_inputCurrentLimit m22 : 8|8@1+ (0.1,0) [0|0] "A"  X
 SG_ DBG_pcs_PHC_pfcSysOvrEnable m38 : 8|1@1+ (1,0) [0|1] ""  X
 SG_ DBG_pcs_DCDC_systemCmdOvrEnable m111 : 8|1@1+ (1,0) [0|1] ""  X
 SG_ DBG_pcs_PHC_pfcFreq m33 : 8|16@1+ (0.005,0) [0|0] "kHz"  X
 SG_ DBG_DCDC_Short_RED_ns m103 : 8|12@1+ (1,0) [10|4095] "ns"  X
 SG_ DBG_pcs_PH_intBusVOvrEnable m9 : 8|1@1+ (1,0) [0|1] ""  X
 SG_ DBG_pcs_PHA_inputCurrentLimit m12 : 8|8@1+ (0.1,0) [0|0] "A"  X
 SG_ DBG_pcs_PHB_pfcSysOvrEnable m37 : 8|1@1+ (1,0) [0|1] ""  X
 SG_ DBG_pcs_PHB_llcFreq m24 : 8|16@1+ (0.005,0) [0|0] "kHz"  X
 SG_ DBG_pcs_envOverrideEnable m39 : 8|1@1+ (1,0) [0|1] ""  X
 SG_ DBG_pcs_DCDC_tempSysOvrEnable m110 : 8|1@1+ (1,0) [0|1] ""  X
 SG_ DBG_pcs_analogMuxOvrEnable m150 : 8|1@1+ (1,0) [0|1] ""  X
 SG_ DBG_DCDC_debugEnable m100 : 8|1@1+ (1,0) [0|1] ""  X
 SG_ DBG_DCDC_Drv_Time_ns m102 : 8|12@1+ (3.90625,0) [0|16000] "ns"  X
 SG_ DBG_pcs_PHA_pfcSysOvrEnable m36 : 8|1@1+ (1,0) [0|1] ""  X
 SG_ DBG_pcs_PHA_dcCirculationEnable m8 : 8|1@1+ (1,0) [0|1] ""  X
 SG_ DBG_DCDC_vTankTarget m108 : 8|16@1+ (0.015625,0) [0|1024] "V"  X
 SG_ DBG_pcs_PHC_llcFreq m34 : 8|16@1+ (0.005,0) [0|0] "kHz"  X
 SG_ DBG_DCDC_vLoopKp m105 : 8|20@1+ (9.5367431640625e-07,0) [0|1] "A"  X
 SG_ DBG_pcs_PHA_pfcFreq m13 : 8|16@1+ (0.005,0) [0|0] "kHz"  X
 SG_ DBG_DCDC_debugCompThreshEn m101 : 8|1@1+ (1,0) [0|1] ""  X
 SG_ DBG_DCDC_debugUint32 m107 : 8|32@1+ (1,0) [0|4294967295] "-"  X
 SG_ DBG_pcs_PHA_clearFaults m5 : 8|1@1+ (1,0) [0|1] ""  X
 SG_ DBG_pcs_PHC_inputCurrentLimit m32 : 8|8@1+ (0.1,0) [0|0] "A"  X
 SG_ DBG_pcs_chgLogicPwrOvrEnable m41 : 8|1@1+ (1,0) [0|1] ""  X
 SG_ DBG_DCDC_Snubber_Pulse_ns m104 : 8|12@1+ (3.90625,0) [0|16000] "ns"  X
 SG_ DBG_pcs_PHA_llcFreq m14 : 8|16@1+ (0.005,0) [0|0] "kHz"  X
 SG_ DBG_pcs_DCDC_pchgImpOvrEnable m113 : 8|1@1+ (1,0) [0|1] ""  X
 SG_ DBG_pcsControlSel M : 0|8@1+ (1,0) [5|150] ""  X

BO_ 1365 RADC_alertLog: 8 CH
 SG_ RADC_a032_block_ucTimeoutBlkConf m32 : 56|8@1+ (1,0) [0|255] ""  gtw
 SG_ RADC_a029_rhcFdcErrType m29 : 56|8@1+ (1,0) [0|2] ""  gtw
 SG_ RADC_a043_msgId m43 : 52|12@1+ (1,0) [0|4095] ""  gtw
 SG_ RADC_a046_msgId m46 : 52|12@1+ (1,0) [0|4095] ""  gtw
 SG_ RADC_a041_msgId m41 : 52|12@1+ (1,0) [0|4095] ""  gtw
 SG_ RADC_a044_msgId m44 : 52|12@1+ (1,0) [0|4095] ""  gtw
 SG_ RADC_a045_msgId m45 : 52|12@1+ (1,0) [0|4095] ""  gtw
 SG_ RADC_a042_msgId m42 : 52|12@1+ (1,0) [0|4095] ""  gtw
 SG_ RADC_a029_rhcSp1ErrType m29 : 48|8@1+ (1,0) [0|0] ""  gtw
 SG_ RADC_a055_block_usFullBlkTimer m55 : 48|16@1+ (1,0) [0|65535] "s"  gtw
 SG_ RADC_a054_block_RoadbeamTimeCnt m54 : 48|16@1+ (1,0) [0|65535] "s"  gtw
 SG_ RADC_a032_block_ucEstiRangeProb m32 : 48|8@1+ (1,0) [0|255] ""  gtw
 SG_ RADC_a055_bblock_ucTimeoutBlkPro m55 : 40|8@1+ (1,0) [0|255] ""  gtw
 SG_ RADC_a054_block_ucOverallConf m54 : 40|8@1+ (1,0) [0|255] ""  gtw
 SG_ RADC_a029_rhcVcoPowerErrType m29 : 40|8@1+ (1,0) [0|1] ""  gtw
 SG_ RADC_a032_block_ucEstiRangeConf m32 : 40|8@1+ (1,0) [0|255] ""  gtw
 SG_ RADC_a042_carConfigErrRx m42 : 36|16@1+ (1,0) [0|65535] ""  gtw
 SG_ RADC_a044_stwAngleErrRx m44 : 36|16@1+ (1,0) [0|65535] ""  gtw
 SG_ RADC_a043_inertialSignalsErrRx m43 : 36|16@1+ (1,0) [0|65535] ""  gtw
 SG_ RADC_a041_vinErrRx m41 : 36|16@1+ (1,0) [0|65535] ""  gtw
 SG_ RADC_a046_wheelSpeedsErrRx m46 : 36|16@1+ (1,0) [0|65535] ""  gtw
 SG_ RADC_a045_vehicleStateErrRx m45 : 36|16@1+ (1,0) [0|65535] ""  gtw
 SG_ RADC_a029_rhcRxErrType m29 : 32|8@1+ (1,0) [0|7] ""  gtw
 SG_ RADC_a050_countryRx m50 : 32|16@1+ (1,0) [0|65535] ""  gtw
 SG_ RADC_a032_block_ucEstiRange m32 : 32|8@1+ (1,0) [0|255] "m"  gtw
 SG_ RADC_a053_emError_RSPClusterList m53 : 32|1@1+ (1,0) [0|1] ""  gtw
 SG_ RADC_a055_block_ucTimeoutTimeCnt m55 : 32|8@1+ (1,0) [0|255] "s"  gtw
 SG_ RADC_a054_block_ucOverallProb m54 : 32|8@1+ (1,0) [0|255] ""  gtw
 SG_ RADC_a053_emError_PreClusterList m53 : 31|1@1+ (1,0) [0|1] ""  gtw
 SG_ RADC_a032_block_SPMSelfTestState m32 : 30|2@1+ (1,0) [0|3] ""  gtw
 SG_ RADC_a053_emError_AxisLoadDistr m53 : 30|1@1+ (1,0) [0|1] ""  gtw
 SG_ RADC_a053_emError_CentGravHeight m53 : 29|1@1+ (1,0) [0|1] ""  gtw
 SG_ RADC_a053_emError_VehicleWeight m53 : 28|1@1+ (1,0) [0|1] ""  gtw
 SG_ RADC_a032_block_dummy m32 : 27|3@1+ (1,0) [0|7] ""  gtw
 SG_ RADC_a053_emError_TrackWidthRe m53 : 27|1@1+ (1,0) [0|1] ""  gtw
 SG_ RADC_a053_emError_TrackWidthFr m53 : 26|1@1+ (1,0) [0|1] ""  gtw
 SG_ RADC_a053_emError_WheelbaseStat m53 : 25|1@1+ (1,0) [0|1] ""  gtw
 SG_ RADC_a053_emError_LongPosToCoG m53 : 24|1@1+ (1,0) [0|1] ""  gtw
 SG_ RADC_a019_internalSWFaultCoreID m19 : 24|4@1+ (1,0) [0|2] ""  gtw
 SG_ RADC_a054_block_ucObjLossConf m54 : 24|8@1+ (1,0) [0|255] ""  gtw
 SG_ RADC_a047_chassisTypeRx m47 : 24|8@1+ (1,0) [0|7] ""  gtw
 SG_ RADC_a051_epasTypeRx m51 : 24|8@1+ (1,0) [0|7] ""  gtw
 SG_ RADC_a032_block_SPMBlockageState m32 : 24|3@1+ (1,0) [0|4] ""  gtw
 SG_ RADC_a031_vertMisalignAngle m31 : 24|12@1+ (0.0001220703125,-0.25) [-0.25|0.24988] "rad"  gtw
 SG_ RADC_a016_adcVoltage m16 : 24|6@1+ (0.1,0) [0|6.3] "v"  gtw
 SG_ RADC_a049_fourWheelDriveRx m49 : 24|8@1+ (1,0) [0|3] ""  gtw
 SG_ RADC_a052_radarPositionRx m52 : 24|8@1+ (1,0) [0|7] ""  gtw
 SG_ RADC_a017_adcVoltage m17 : 24|6@1+ (0.1,0) [0|6.3] "v"  gtw
 SG_ RADC_a048_airSuspensionRx m48 : 24|8@1+ (1,0) [0|7] ""  gtw
 SG_ RADC_a029_rhcRxLongTermErrType m29 : 24|8@1+ (1,0) [0|6] ""  gtw
 SG_ RADC_a053_emError_MountLongPos m53 : 23|1@1+ (1,0) [0|1] ""  gtw
 SG_ RADC_a053_emError_MountVertPos m53 : 22|1@1+ (1,0) [0|1] ""  gtw
 SG_ RADC_a053_emError_EGOSpeedCorrSt m53 : 21|1@1+ (1,0) [0|1] ""  gtw
 SG_ RADC_a041_vinErrExp m41 : 20|16@1+ (1,0) [0|65535] ""  gtw
 SG_ RADC_a053_emError_EGOSpeedState m53 : 20|1@1+ (1,0) [0|1] ""  gtw
 SG_ RADC_a046_wheelSpeedsErrExp m46 : 20|16@1+ (1,0) [0|65535] ""  gtw
 SG_ RADC_a043_inertialSignalsErrExp m43 : 20|16@1+ (1,0) [0|65535] ""  gtw
 SG_ RADC_a042_carConfigErrExp m42 : 20|16@1+ (1,0) [0|65535] ""  gtw
 SG_ RADC_a045_vehicleStateErrExp m45 : 20|16@1+ (1,0) [0|65535] ""  gtw
 SG_ RADC_a044_stwAngleErrExp m44 : 20|16@1+ (1,0) [0|65535] ""  gtw
 SG_ RADC_a053_emError_EGOCurveState m53 : 19|1@1+ (1,0) [0|1] ""  gtw
 SG_ RADC_a053_emError_EGOMotionState m53 : 18|1@1+ (1,0) [0|1] ""  gtw
 SG_ RADC_a053_emError_EGOAccelState m53 : 17|1@1+ (1,0) [0|1] ""  gtw
 SG_ RADC_a029_rhcChirpMonErrType m29 : 16|8@1+ (1,0) [0|2] ""  gtw
 SG_ RADC_a032_blockageType m32 : 16|8@1+ (1,0) [0|4] ""  gtw
 SG_ RADC_a047_chassisTypeExp m47 : 16|8@1+ (1,0) [0|7] ""  gtw
 SG_ RADC_a051_epasTypeExp m51 : 16|8@1+ (1,0) [0|7] ""  gtw
 SG_ RADC_a025_ecuVoltage m25 : 16|8@1+ (0.1,0) [0|25.5] "v"  gtw
 SG_ RADC_a039_msgId m39 : 16|12@1+ (1,0) [0|4095] ""  gtw
 SG_ RADC_a026_ecuVoltage m26 : 16|8@1+ (0.1,0) [0|25.5] "v"  gtw
 SG_ RADC_a020_ecuTemp m20 : 16|16@1+ (0.1,-44) [-44|6509.5] "deg"  gtw
 SG_ RADC_a040_msgId m40 : 16|12@1+ (1,0) [0|4095] ""  gtw
 SG_ RADC_a050_countryExp m50 : 16|16@1+ (1,0) [0|65535] ""  gtw
 SG_ RADC_a046_wheelSpeedsErrType m46 : 16|4@1+ (1,0) [0|5] ""  gtw
 SG_ RADC_a038_msgId m38 : 16|12@1+ (1,0) [0|4095] ""  gtw
 SG_ RADC_a052_radarPositionExp m52 : 16|8@1+ (1,0) [0|7] ""  gtw
 SG_ RADC_a030_rspErrType m30 : 16|8@1+ (1,0) [0|1] ""  gtw
 SG_ RADC_a031_horizMisalignAngle m31 : 16|8@1+ (0.001953125,-0.25) [-0.25|0.24805] "rad"  gtw
 SG_ RADC_a008_interLockErrType m8 : 16|8@1+ (1,0) [0|1] ""  gtw
 SG_ RADC_a035_msgId m35 : 16|12@1+ (1,0) [0|4095] ""  gtw
 SG_ RADC_a034_vehDynamicsErrorType m34 : 16|8@1+ (1,0) [0|7] ""  gtw
 SG_ RADC_a054_block_ucObjLossProb m54 : 16|8@1+ (1,0) [0|255] ""  gtw
 SG_ RADC_a049_fourWheelDriveExp m49 : 16|8@1+ (1,0) [0|3] ""  gtw
 SG_ RADC_a042_carConfigErrType m42 : 16|4@1+ (1,0) [0|5] ""  gtw
 SG_ RADC_a044_stwAngleErrType m44 : 16|4@1+ (1,0) [0|5] ""  gtw
 SG_ RADC_a045_vehicleStateErrType m45 : 16|4@1+ (1,0) [0|5] ""  gtw
 SG_ RADC_a028_rfComRegCheckFail m28 : 16|8@1+ (1,0) [0|4] ""  gtw
 SG_ RADC_a048_airSuspensionExp m48 : 16|8@1+ (1,0) [0|7] ""  gtw
 SG_ RADC_a016_adcOverVoltType m16 : 16|8@1+ (1,0) [0|7] ""  gtw
 SG_ RADC_a023_ecuTemp m23 : 16|16@1+ (0.1,-44) [-44|6509.5] "deg"  gtw
 SG_ RADC_a055_block_usTimeoutWayCnt m55 : 16|16@1+ (1,0) [0|65535] "m"  gtw
 SG_ RADC_a053_emError_LatYawRate m53 : 16|1@1+ (1,0) [0|1] ""  gtw
 SG_ RADC_a027_nvmFailureType m27 : 16|8@1+ (1,0) [0|2] ""  gtw
 SG_ RADC_a037_msgId m37 : 16|12@1+ (1,0) [0|4095] ""  gtw
 SG_ RADC_a011_ecuMcemErrType m11 : 16|8@1+ (1,0) [0|10] ""  gtw
 SG_ RADC_a013_ecuWdgErrType m13 : 16|8@1+ (1,0) [0|3] ""  gtw
 SG_ RADC_a043_inertialSignalsErrType m43 : 16|4@1+ (1,0) [0|5] ""  gtw
 SG_ RADC_a002_ecuAdcErrType m2 : 16|8@1+ (1,0) [0|1] ""  gtw
 SG_ RADC_a019_internalSWFaultType m19 : 16|8@1+ (1,0) [0|110] ""  gtw
 SG_ RADC_a041_vinErrType m41 : 16|4@1+ (1,0) [0|5] ""  gtw
 SG_ RADC_a017_adcUnderVoltType m17 : 16|8@1+ (1,0) [0|7] ""  gtw
 SG_ RADC_a036_msgId m36 : 16|12@1+ (1,0) [0|4095] ""  gtw
 SG_ RADC_alertState : 15|1@1+ (1,0) [0|1] ""  gtw
 SG_ RADC_alertID M : 0|6@1+ (1,0) [0|55] ""  gtw

BO_ 583 DAS_autopilotDebug: 8 CH
 SG_ DAS_lastWatchdogCode : 56|7@1+ (1,0) [0|72] ""  gtw
 SG_ DAS_laneChangeState : 50|6@1+ (1,0) [0|63] ""  gtw
 SG_ DAS_forkState : 45|5@1+ (1,0) [0|24] ""  gtw
 SG_ DAS_rqstedBehaviorStatus : 40|5@1+ (1,0) [0|22] ""  gtw
 SG_ DAS_autopilotAbortReason : 32|6@1+ (1,0) [0|63] ""  gtw
 SG_ DAS_controlDistance : 24|6@1+ (2,0) [0|126] "m"  gtw
 SG_ DAS_constructionZone : 23|1@1+ (1,0) [0|1] ""  gtw
 SG_ DAS_controllerHealth : 21|2@1+ (1,0) [0|3] ""  gtw
 SG_ DAS_behaviorReport : 16|5@1+ (1,0) [1|29] ""  gtw
 SG_ DAS_alcInternalState : 12|4@1+ (1,0) [0|11] ""  gtw
 SG_ DAS_controllerRef : 9|3@1+ (1,0) [0|6] ""  gtw
 SG_ DAS_mapAvailability : 8|1@1+ (1,0) [0|1] ""  gtw
 SG_ DAS_localizerHealth : 4|4@1+ (1,0) [0|8] ""  gtw
 SG_ DAS_roadEstimator : 2|2@1+ (1,0) [0|3] ""  gtw
 SG_ DAS_missionPlan : 0|2@1+ (1,0) [0|3] ""  gtw

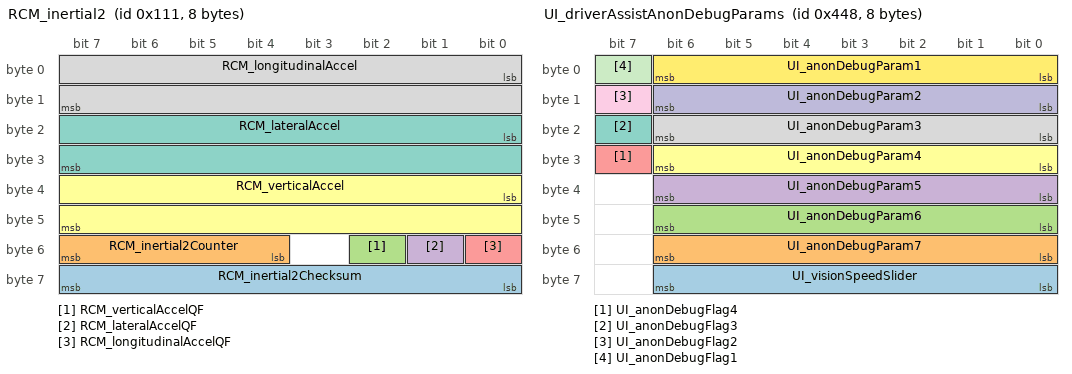
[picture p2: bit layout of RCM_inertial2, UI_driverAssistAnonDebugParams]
BO_ 273 RCM_inertial2: 8 CH
 SG_ RCM_inertial2Checksum : 56|8@1+ (1,0) [0|255] ""  epas3s
 SG_ RCM_inertial2Counter : 52|4@1+ (1,0) [0|15] ""  epas3s
 SG_ RCM_verticalAccelQF : 50|1@1+ (1,0) [0|1] ""  gtw
 SG_ RCM_lateralAccelQF : 49|1@1+ (1,0) [0|1] ""  epas3s
 SG_ RCM_longitudinalAccelQF : 48|1@1+ (1,0) [0|1] ""  epas3s
 SG_ RCM_verticalAccel : 32|16@1- (0.00125,0.0) [-40.9575|40.9575] "m/s^2"  gtw
 SG_ RCM_lateralAccel : 16|16@1- (0.00125,0.0) [-40.9575|40.9575] "m/s^2"  das
 SG_ RCM_longitudinalAccel : 0|16@1- (0.00125,0.0) [-40.9575|40.9575] "m/s^2"  das

BO_ 1096 UI_driverAssistAnonDebugParams: 8 CH
 SG_ UI_visionSpeedSlider : 56|7@1+ (1,0) [0|127] ""  das
 SG_ UI_anonDebugParam7 : 48|7@1+ (1,0) [0|127] ""  das
 SG_ UI_anonDebugParam6 : 40|7@1+ (1,0) [0|127] ""  das
 SG_ UI_anonDebugParam5 : 32|7@1+ (1,0) [0|127] ""  das
 SG_ UI_anonDebugFlag4 : 31|1@1+ (1,0) [0|1] ""  das
 SG_ UI_anonDebugParam4 : 24|7@1+ (1,0) [0|127] ""  das
 SG_ UI_anonDebugFlag3 : 23|1@1+ (1,0) [0|1] ""  das
 SG_ UI_anonDebugParam3 : 16|7@1+ (1,0) [0|127] ""  das
 SG_ UI_anonDebugFlag2 : 15|1@1+ (1,0) [0|1] ""  das
 SG_ UI_anonDebugParam2 : 8|7@1+ (1,0) [0|127] ""  das
 SG_ UI_anonDebugFlag1 : 7|1@1+ (1,0) [0|1] ""  das
 SG_ UI_anonDebugParam1 : 0|7@1+ (1,0) [0|127] ""  das

BO_ 1297 RCM_alertLog: 8 CH
 SG_ RCM_a011_eventAccelPedalPos m11 : 56|8@1+ (0.4,0) [0|100] "%"  gtw
 SG_ RCM_a077_eventAccelPedalPos m77 : 56|8@1+ (0.4,0) [0|100] "%"  gtw
 SG_ RCM_a008_eventAccelPedalPos m8 : 56|8@1+ (0.4,0) [0|100] "%"  gtw
 SG_ RCM_a109_eventAccelPedalPos m109 : 56|8@1+ (0.4,0) [0|100] "%"  gtw
 SG_ RCM_a033_eventAccelPedalPos m33 : 56|8@1+ (0.4,0) [0|100] "%"  gtw
 SG_ RCM_a080_eventAccelPedalPos m80 : 56|8@1+ (0.4,0) [0|100] "%"  gtw
 SG_ RCM_a099_eventAccelPedalPos m99 : 56|8@1+ (0.4,0) [0|100] "%"  gtw
 SG_ RCM_a055_eventAccelPedalPos m55 : 56|8@1+ (0.4,0) [0|100] "%"  gtw
 SG_ RCM_a110_eventAccelPedalPos m110 : 56|8@1+ (0.4,0) [0|100] "%"  gtw
 SG_ RCM_a070_eventAccelPedalPos m70 : 56|8@1+ (0.4,0) [0|100] "%"  gtw
 SG_ RCM_a034_eventAccelPedalPos m34 : 56|8@1+ (0.4,0) [0|100] "%"  gtw
 SG_ RCM_a117_eventAccelPedalPos m117 : 56|8@1+ (0.4,0) [0|100] "%"  gtw
 SG_ RCM_a052_eventAccelPedalPos m52 : 56|8@1+ (0.4,0) [0|100] "%"  gtw
 SG_ RCM_a087_eventAccelPedalPos m87 : 56|8@1+ (0.4,0) [0|100] "%"  gtw
 SG_ RCM_a069_eventAccelPedalPos m69 : 56|8@1+ (0.4,0) [0|100] "%"  gtw
 SG_ RCM_a016_eventAccelPedalPos m16 : 56|8@1+ (0.4,0) [0|100] "%"  gtw
 SG_ RCM_a020_eventAccelPedalPos m20 : 56|8@1+ (0.4,0) [0|100] "%"  gtw
 SG_ RCM_a103_eventAccelPedalPos m103 : 56|8@1+ (0.4,0) [0|100] "%"  gtw
 SG_ RCM_a093_eventAccelPedalPos m93 : 56|8@1+ (0.4,0) [0|100] "%"  gtw
 SG_ RCM_a002_eventAccelPedalPos m2 : 56|8@1+ (0.4,0) [0|100] "%"  gtw
 SG_ RCM_a039_eventAccelPedalPos m39 : 56|8@1+ (0.4,0) [0|100] "%"  gtw
 SG_ RCM_a046_eventAccelPedalPos m46 : 56|8@1+ (0.4,0) [0|100] "%"  gtw
 SG_ RCM_a064_eventAccelPedalPos m64 : 56|8@1+ (0.4,0) [0|100] "%"  gtw
 SG_ RCM_a018_eventAccelPedalPos m18 : 56|8@1+ (0.4,0) [0|100] "%"  gtw
 SG_ RCM_a100_eventAccelPedalPos m100 : 56|8@1+ (0.4,0) [0|100] "%"  gtw
 SG_ RCM_a023_eventAccelPedalPos m23 : 56|8@1+ (0.4,0) [0|100] "%"  gtw
 SG_ RCM_a045_eventAccelPedalPos m45 : 56|8@1+ (0.4,0) [0|100] "%"  gtw
 SG_ RCM_a001_eventAccelPedalPos m1 : 56|8@1+ (0.4,0) [0|100] "%"  gtw
 SG_ RCM_a090_eventAccelPedalPos m90 : 56|8@1+ (0.4,0) [0|100] "%"  gtw
 SG_ RCM_a067_eventAccelPedalPos m67 : 56|8@1+ (0.4,0) [0|100] "%"  gtw
 SG_ RCM_a089_eventAccelPedalPos m89 : 56|8@1+ (0.4,0) [0|100] "%"  gtw
 SG_ RCM_a105_eventAccelPedalPos m105 : 56|8@1+ (0.4,0) [0|100] "%"  gtw
 SG_ RCM_a026_eventAccelPedalPos m26 : 56|8@1+ (0.4,0) [0|100] "%"  gtw
 SG_ RCM_a059_eventAccelPedalPos m59 : 56|8@1+ (0.4,0) [0|100] "%"  gtw
 SG_ RCM_a004_eventAccelPedalPos m4 : 56|8@1+ (0.4,0) [0|100] "%"  gtw
 SG_ RCM_a062_eventAccelPedalPos m62 : 56|8@1+ (0.4,0) [0|100] "%"  gtw
 SG_ RCM_a040_eventAccelPedalPos m40 : 56|8@1+ (0.4,0) [0|100] "%"  gtw
 SG_ RCM_a095_eventAccelPedalPos m95 : 56|8@1+ (0.4,0) [0|100] "%"  gtw
 SG_ RCM_a012_eventAccelPedalPos m12 : 56|8@1+ (0.4,0) [0|100] "%"  gtw
 SG_ RCM_a074_eventAccelPedalPos m74 : 56|8@1+ (0.4,0) [0|100] "%"  gtw
 SG_ RCM_a029_eventAccelPedalPos m29 : 56|8@1+ (0.4,0) [0|100] "%"  gtw
 SG_ RCM_a083_eventAccelPedalPos m83 : 56|8@1+ (0.4,0) [0|100] "%"  gtw
 SG_ RCM_a030_eventAccelPedalPos m30 : 56|8@1+ (0.4,0) [0|100] "%"  gtw
 SG_ RCM_a113_eventAccelPedalPos m113 : 56|8@1+ (0.4,0) [0|100] "%"  gtw
 SG_ RCM_a056_eventAccelPedalPos m56 : 56|8@1+ (0.4,0) [0|100] "%"  gtw
 SG_ RCM_a116_eventAccelPedalPos m116 : 56|8@1+ (0.4,0) [0|100] "%"  gtw
 SG_ RCM_a053_eventAccelPedalPos m53 : 56|8@1+ (0.4,0) [0|100] "%"  gtw
 SG_ RCM_a071_eventAccelPedalPos m71 : 56|8@1+ (0.4,0) [0|100] "%"  gtw
 SG_ RCM_a035_eventAccelPedalPos m35 : 56|8@1+ (0.4,0) [0|100] "%"  gtw
 SG_ RCM_a068_eventAccelPedalPos m68 : 56|8@1+ (0.4,0) [0|100] "%"  gtw
 SG_ RCM_a086_eventAccelPedalPos m86 : 56|8@1+ (0.4,0) [0|100] "%"  gtw
 SG_ RCM_a017_eventAccelPedalPos m17 : 56|8@1+ (0.4,0) [0|100] "%"  gtw
 SG_ RCM_a085_eventAccelPedalPos m85 : 56|8@1+ (0.4,0) [0|100] "%"  gtw
 SG_ RCM_a014_eventAccelPedalPos m14 : 56|8@1+ (0.4,0) [0|100] "%"  gtw
 SG_ RCM_a036_eventAccelPedalPos m36 : 56|8@1+ (0.4,0) [0|100] "%"  gtw
 SG_ RCM_a049_eventAccelPedalPos m49 : 56|8@1+ (0.4,0) [0|100] "%"  gtw
 SG_ RCM_a050_eventAccelPedalPos m50 : 56|8@1+ (0.4,0) [0|100] "%"  gtw
 SG_ RCM_a115_eventAccelPedalPos m115 : 56|8@1+ (0.4,0) [0|100] "%"  gtw
 SG_ RCM_a072_eventAccelPedalPos m72 : 56|8@1+ (0.4,0) [0|100] "%"  gtw
 SG_ RCM_a066_eventAccelPedalPos m66 : 56|8@1+ (0.4,0) [0|100] "%"  gtw
 SG_ RCM_a088_eventAccelPedalPos m88 : 56|8@1+ (0.4,0) [0|100] "%"  gtw
 SG_ RCM_a022_eventAccelPedalPos m22 : 56|8@1+ (0.4,0) [0|100] "%"  gtw
 SG_ RCM_a101_eventAccelPedalPos m101 : 56|8@1+ (0.4,0) [0|100] "%"  gtw
 SG_ RCM_a044_eventAccelPedalPos m44 : 56|8@1+ (0.4,0) [0|100] "%"  gtw
 SG_ RCM_a118_eventAccelPedalPos m118 : 56|8@1+ (0.4,0) [0|100] "%"  gtw
 SG_ RCM_a000_eventAccelPedalPos m0 : 56|8@1+ (0.4,0) [0|100] "%"  gtw
 SG_ RCM_a019_eventAccelPedalPos m19 : 56|8@1+ (0.4,0) [0|100] "%"  gtw
 SG_ RCM_a091_eventAccelPedalPos m91 : 56|8@1+ (0.4,0) [0|100] "%"  gtw
 SG_ RCM_a061_eventAccelPedalPos m61 : 56|8@1+ (0.4,0) [0|100] "%"  gtw
 SG_ RCM_a007_eventAccelPedalPos m7 : 56|8@1+ (0.4,0) [0|100] "%"  gtw
 SG_ RCM_a078_eventAccelPedalPos m78 : 56|8@1+ (0.4,0) [0|100] "%"  gtw
 SG_ RCM_a043_eventAccelPedalPos m43 : 56|8@1+ (0.4,0) [0|100] "%"  gtw
 SG_ RCM_a106_eventAccelPedalPos m106 : 56|8@1+ (0.4,0) [0|100] "%"  gtw
 SG_ RCM_a025_eventAccelPedalPos m25 : 56|8@1+ (0.4,0) [0|100] "%"  gtw
 SG_ RCM_a096_eventAccelPedalPos m96 : 56|8@1+ (0.4,0) [0|100] "%"  gtw
 SG_ RCM_a075_eventAccelPedalPos m75 : 56|8@1+ (0.4,0) [0|100] "%"  gtw
 SG_ RCM_a082_eventAccelPedalPos m82 : 56|8@1+ (0.4,0) [0|100] "%"  gtw
 SG_ RCM_a112_eventAccelPedalPos m112 : 56|8@1+ (0.4,0) [0|100] "%"  gtw
 SG_ RCM_a057_eventAccelPedalPos m57 : 56|8@1+ (0.4,0) [0|100] "%"  gtw
 SG_ RCM_a013_eventAccelPedalPos m13 : 56|8@1+ (0.4,0) [0|100] "%"  gtw
 SG_ RCM_a031_eventAccelPedalPos m31 : 56|8@1+ (0.4,0) [0|100] "%"  gtw
 SG_ RCM_a028_eventAccelPedalPos m28 : 56|8@1+ (0.4,0) [0|100] "%"  gtw
 SG_ RCM_a098_eventAccelPedalPos m98 : 56|8@1+ (0.4,0) [0|100] "%"  gtw
 SG_ RCM_a111_eventAccelPedalPos m111 : 56|8@1+ (0.4,0) [0|100] "%"  gtw
 SG_ RCM_a054_eventAccelPedalPos m54 : 56|8@1+ (0.4,0) [0|100] "%"  gtw
 SG_ RCM_a076_eventAccelPedalPos m76 : 56|8@1+ (0.4,0) [0|100] "%"  gtw
 SG_ RCM_a009_eventAccelPedalPos m9 : 56|8@1+ (0.4,0) [0|100] "%"  gtw
 SG_ RCM_a010_eventAccelPedalPos m10 : 56|8@1+ (0.4,0) [0|100] "%"  gtw
 SG_ RCM_a032_eventAccelPedalPos m32 : 56|8@1+ (0.4,0) [0|100] "%"  gtw
 SG_ RCM_a081_eventAccelPedalPos m81 : 56|8@1+ (0.4,0) [0|100] "%"  gtw
 SG_ RCM_a108_eventAccelPedalPos m108 : 56|8@1+ (0.4,0) [0|100] "%"  gtw
 SG_ RCM_a037_eventAccelPedalPos m37 : 56|8@1+ (0.4,0) [0|100] "%"  gtw
 SG_ RCM_a051_eventAccelPedalPos m51 : 56|8@1+ (0.4,0) [0|100] "%"  gtw
 SG_ RCM_a114_eventAccelPedalPos m114 : 56|8@1+ (0.4,0) [0|100] "%"  gtw
 SG_ RCM_a048_eventAccelPedalPos m48 : 56|8@1+ (0.4,0) [0|100] "%"  gtw
 SG_ RCM_a073_eventAccelPedalPos m73 : 56|8@1+ (0.4,0) [0|100] "%"  gtw
 SG_ RCM_a084_eventAccelPedalPos m84 : 56|8@1+ (0.4,0) [0|100] "%"  gtw
 SG_ RCM_a015_eventAccelPedalPos m15 : 56|8@1+ (0.4,0) [0|100] "%"  gtw
 SG_ RCM_a047_eventAccelPedalPos m47 : 56|8@1+ (0.4,0) [0|100] "%"  gtw
 SG_ RCM_a065_eventAccelPedalPos m65 : 56|8@1+ (0.4,0) [0|100] "%"  gtw
 SG_ RCM_a003_eventAccelPedalPos m3 : 56|8@1+ (0.4,0) [0|100] "%"  gtw
 SG_ RCM_a021_eventAccelPedalPos m21 : 56|8@1+ (0.4,0) [0|100] "%"  gtw
 SG_ RCM_a102_eventAccelPedalPos m102 : 56|8@1+ (0.4,0) [0|100] "%"  gtw
 SG_ RCM_a092_eventAccelPedalPos m92 : 56|8@1+ (0.4,0) [0|100] "%"  gtw
 SG_ RCM_a038_eventAccelPedalPos m38 : 56|8@1+ (0.4,0) [0|100] "%"  gtw
 SG_ RCM_a042_eventAccelPedalPos m42 : 56|8@1+ (0.4,0) [0|100] "%"  gtw
 SG_ RCM_a060_eventAccelPedalPos m60 : 56|8@1+ (0.4,0) [0|100] "%"  gtw
 SG_ RCM_a079_eventAccelPedalPos m79 : 56|8@1+ (0.4,0) [0|100] "%"  gtw
 SG_ RCM_a006_eventAccelPedalPos m6 : 56|8@1+ (0.4,0) [0|100] "%"  gtw
 SG_ RCM_a097_eventAccelPedalPos m97 : 56|8@1+ (0.4,0) [0|100] "%"  gtw
 SG_ RCM_a024_eventAccelPedalPos m24 : 56|8@1+ (0.4,0) [0|100] "%"  gtw
 SG_ RCM_a107_eventAccelPedalPos m107 : 56|8@1+ (0.4,0) [0|100] "%"  gtw
 SG_ RCM_a094_eventAccelPedalPos m94 : 56|8@1+ (0.4,0) [0|100] "%"  gtw
 SG_ RCM_a063_eventAccelPedalPos m63 : 56|8@1+ (0.4,0) [0|100] "%"  gtw
 SG_ RCM_a027_eventAccelPedalPos m27 : 56|8@1+ (0.4,0) [0|100] "%"  gtw
 SG_ RCM_a104_eventAccelPedalPos m104 : 56|8@1+ (0.4,0) [0|100] "%"  gtw
 SG_ RCM_a005_eventAccelPedalPos m5 : 56|8@1+ (0.4,0) [0|100] "%"  gtw
 SG_ RCM_a041_eventAccelPedalPos m41 : 56|8@1+ (0.4,0) [0|100] "%"  gtw
 SG_ RCM_a058_eventAccelPedalPos m58 : 56|8@1+ (0.4,0) [0|100] "%"  gtw
 SG_ RCM_a094_eventDriverBrakeApply m94 : 46|2@1+ (1,0) [0|3] ""  gtw
 SG_ RCM_a058_eventDriverBrakeApply m58 : 46|2@1+ (1,0) [0|3] ""  gtw
 SG_ RCM_a104_eventDriverBrakeApply m104 : 46|2@1+ (1,0) [0|3] ""  gtw
 SG_ RCM_a027_eventDriverBrakeApply m27 : 46|2@1+ (1,0) [0|3] ""  gtw
 SG_ RCM_a041_eventDriverBrakeApply m41 : 46|2@1+ (1,0) [0|3] ""  gtw
 SG_ RCM_a005_eventDriverBrakeApply m5 : 46|2@1+ (1,0) [0|3] ""  gtw
 SG_ RCM_a063_eventDriverBrakeApply m63 : 46|2@1+ (1,0) [0|3] ""  gtw
 SG_ RCM_a013_eventDriverBrakeApply m13 : 46|2@1+ (1,0) [0|3] ""  gtw
 SG_ RCM_a031_eventDriverBrakeApply m31 : 46|2@1+ (1,0) [0|3] ""  gtw
 SG_ RCM_a057_eventDriverBrakeApply m57 : 46|2@1+ (1,0) [0|3] ""  gtw
 SG_ RCM_a112_eventDriverBrakeApply m112 : 46|2@1+ (1,0) [0|3] ""  gtw
 SG_ RCM_a082_eventDriverBrakeApply m82 : 46|2@1+ (1,0) [0|3] ""  gtw
 SG_ RCM_a028_eventDriverBrakeApply m28 : 46|2@1+ (1,0) [0|3] ""  gtw
 SG_ RCM_a075_eventDriverBrakeApply m75 : 46|2@1+ (1,0) [0|3] ""  gtw
 SG_ RCM_a117_eventDriverBrakeApply m117 : 46|2@1+ (1,0) [0|3] ""  gtw
 SG_ RCM_a052_eventDriverBrakeApply m52 : 46|2@1+ (1,0) [0|3] ""  gtw
 SG_ RCM_a087_eventDriverBrakeApply m87 : 46|2@1+ (1,0) [0|3] ""  gtw
 SG_ RCM_a034_eventDriverBrakeApply m34 : 46|2@1+ (1,0) [0|3] ""  gtw
 SG_ RCM_a070_eventDriverBrakeApply m70 : 46|2@1+ (1,0) [0|3] ""  gtw
 SG_ RCM_a069_eventDriverBrakeApply m69 : 46|2@1+ (1,0) [0|3] ""  gtw
 SG_ RCM_a016_eventDriverBrakeApply m16 : 46|2@1+ (1,0) [0|3] ""  gtw
 SG_ RCM_a040_eventDriverBrakeApply m40 : 46|2@1+ (1,0) [0|3] ""  gtw
 SG_ RCM_a105_eventDriverBrakeApply m105 : 46|2@1+ (1,0) [0|3] ""  gtw
 SG_ RCM_a026_eventDriverBrakeApply m26 : 46|2@1+ (1,0) [0|3] ""  gtw
 SG_ RCM_a062_eventDriverBrakeApply m62 : 46|2@1+ (1,0) [0|3] ""  gtw
 SG_ RCM_a004_eventDriverBrakeApply m4 : 46|2@1+ (1,0) [0|3] ""  gtw
 SG_ RCM_a059_eventDriverBrakeApply m59 : 46|2@1+ (1,0) [0|3] ""  gtw
 SG_ RCM_a095_eventDriverBrakeApply m95 : 46|2@1+ (1,0) [0|3] ""  gtw
 SG_ RCM_a081_eventDriverBrakeApply m81 : 46|2@1+ (1,0) [0|3] ""  gtw
 SG_ RCM_a032_eventDriverBrakeApply m32 : 46|2@1+ (1,0) [0|3] ""  gtw
 SG_ RCM_a054_eventDriverBrakeApply m54 : 46|2@1+ (1,0) [0|3] ""  gtw
 SG_ RCM_a111_eventDriverBrakeApply m111 : 46|2@1+ (1,0) [0|3] ""  gtw
 SG_ RCM_a076_eventDriverBrakeApply m76 : 46|2@1+ (1,0) [0|3] ""  gtw
 SG_ RCM_a009_eventDriverBrakeApply m9 : 46|2@1+ (1,0) [0|3] ""  gtw
 SG_ RCM_a108_eventDriverBrakeApply m108 : 46|2@1+ (1,0) [0|3] ""  gtw
 SG_ RCM_a010_eventDriverBrakeApply m10 : 46|2@1+ (1,0) [0|3] ""  gtw
 SG_ RCM_a098_eventDriverBrakeApply m98 : 46|2@1+ (1,0) [0|3] ""  gtw
 SG_ RCM_a035_eventDriverBrakeApply m35 : 46|2@1+ (1,0) [0|3] ""  gtw
 SG_ RCM_a068_eventDriverBrakeApply m68 : 46|2@1+ (1,0) [0|3] ""  gtw
 SG_ RCM_a071_eventDriverBrakeApply m71 : 46|2@1+ (1,0) [0|3] ""  gtw
 SG_ RCM_a017_eventDriverBrakeApply m17 : 46|2@1+ (1,0) [0|3] ""  gtw
 SG_ RCM_a116_eventDriverBrakeApply m116 : 46|2@1+ (1,0) [0|3] ""  gtw
 SG_ RCM_a053_eventDriverBrakeApply m53 : 46|2@1+ (1,0) [0|3] ""  gtw
 SG_ RCM_a086_eventDriverBrakeApply m86 : 46|2@1+ (1,0) [0|3] ""  gtw
 SG_ RCM_a102_eventDriverBrakeApply m102 : 46|2@1+ (1,0) [0|3] ""  gtw
 SG_ RCM_a021_eventDriverBrakeApply m21 : 46|2@1+ (1,0) [0|3] ""  gtw
 SG_ RCM_a092_eventDriverBrakeApply m92 : 46|2@1+ (1,0) [0|3] ""  gtw
 SG_ RCM_a003_eventDriverBrakeApply m3 : 46|2@1+ (1,0) [0|3] ""  gtw
 SG_ RCM_a047_eventDriverBrakeApply m47 : 46|2@1+ (1,0) [0|3] ""  gtw
 SG_ RCM_a038_eventDriverBrakeApply m38 : 46|2@1+ (1,0) [0|3] ""  gtw
 SG_ RCM_a065_eventDriverBrakeApply m65 : 46|2@1+ (1,0) [0|3] ""  gtw
 SG_ RCM_a110_eventDriverBrakeApply m110 : 46|2@1+ (1,0) [0|3] ""  gtw
 SG_ RCM_a055_eventDriverBrakeApply m55 : 46|2@1+ (1,0) [0|3] ""  gtw
 SG_ RCM_a077_eventDriverBrakeApply m77 : 46|2@1+ (1,0) [0|3] ""  gtw
 SG_ RCM_a008_eventDriverBrakeApply m8 : 46|2@1+ (1,0) [0|3] ""  gtw
 SG_ RCM_a033_eventDriverBrakeApply m33 : 46|2@1+ (1,0) [0|3] ""  gtw
 SG_ RCM_a109_eventDriverBrakeApply m109 : 46|2@1+ (1,0) [0|3] ""  gtw
 SG_ RCM_a080_eventDriverBrakeApply m80 : 46|2@1+ (1,0) [0|3] ""  gtw
 SG_ RCM_a011_eventDriverBrakeApply m11 : 46|2@1+ (1,0) [0|3] ""  gtw
 SG_ RCM_a099_eventDriverBrakeApply m99 : 46|2@1+ (1,0) [0|3] ""  gtw
 SG_ RCM_a085_eventDriverBrakeApply m85 : 46|2@1+ (1,0) [0|3] ""  gtw
 SG_ RCM_a072_eventDriverBrakeApply m72 : 46|2@1+ (1,0) [0|3] ""  gtw
 SG_ RCM_a049_eventDriverBrakeApply m49 : 46|2@1+ (1,0) [0|3] ""  gtw
 SG_ RCM_a014_eventDriverBrakeApply m14 : 46|2@1+ (1,0) [0|3] ""  gtw
 SG_ RCM_a036_eventDriverBrakeApply m36 : 46|2@1+ (1,0) [0|3] ""  gtw
 SG_ RCM_a115_eventDriverBrakeApply m115 : 46|2@1+ (1,0) [0|3] ""  gtw
 SG_ RCM_a050_eventDriverBrakeApply m50 : 46|2@1+ (1,0) [0|3] ""  gtw
 SG_ RCM_a064_eventDriverBrakeApply m64 : 46|2@1+ (1,0) [0|3] ""  gtw
 SG_ RCM_a093_eventDriverBrakeApply m93 : 46|2@1+ (1,0) [0|3] ""  gtw
 SG_ RCM_a002_eventDriverBrakeApply m2 : 46|2@1+ (1,0) [0|3] ""  gtw
 SG_ RCM_a046_eventDriverBrakeApply m46 : 46|2@1+ (1,0) [0|3] ""  gtw
 SG_ RCM_a039_eventDriverBrakeApply m39 : 46|2@1+ (1,0) [0|3] ""  gtw
 SG_ RCM_a103_eventDriverBrakeApply m103 : 46|2@1+ (1,0) [0|3] ""  gtw
 SG_ RCM_a020_eventDriverBrakeApply m20 : 46|2@1+ (1,0) [0|3] ""  gtw
 SG_ RCM_a043_eventDriverBrakeApply m43 : 46|2@1+ (1,0) [0|3] ""  gtw
 SG_ RCM_a106_eventDriverBrakeApply m106 : 46|2@1+ (1,0) [0|3] ""  gtw
 SG_ RCM_a025_eventDriverBrakeApply m25 : 46|2@1+ (1,0) [0|3] ""  gtw
 SG_ RCM_a061_eventDriverBrakeApply m61 : 46|2@1+ (1,0) [0|3] ""  gtw
 SG_ RCM_a007_eventDriverBrakeApply m7 : 46|2@1+ (1,0) [0|3] ""  gtw
 SG_ RCM_a078_eventDriverBrakeApply m78 : 46|2@1+ (1,0) [0|3] ""  gtw
 SG_ RCM_a096_eventDriverBrakeApply m96 : 46|2@1+ (1,0) [0|3] ""  gtw
 SG_ RCM_a015_eventDriverBrakeApply m15 : 46|2@1+ (1,0) [0|3] ""  gtw
 SG_ RCM_a048_eventDriverBrakeApply m48 : 46|2@1+ (1,0) [0|3] ""  gtw
 SG_ RCM_a084_eventDriverBrakeApply m84 : 46|2@1+ (1,0) [0|3] ""  gtw
 SG_ RCM_a037_eventDriverBrakeApply m37 : 46|2@1+ (1,0) [0|3] ""  gtw
 SG_ RCM_a114_eventDriverBrakeApply m114 : 46|2@1+ (1,0) [0|3] ""  gtw
 SG_ RCM_a051_eventDriverBrakeApply m51 : 46|2@1+ (1,0) [0|3] ""  gtw
 SG_ RCM_a073_eventDriverBrakeApply m73 : 46|2@1+ (1,0) [0|3] ""  gtw
 SG_ RCM_a001_eventDriverBrakeApply m1 : 46|2@1+ (1,0) [0|3] ""  gtw
 SG_ RCM_a100_eventDriverBrakeApply m100 : 46|2@1+ (1,0) [0|3] ""  gtw
 SG_ RCM_a023_eventDriverBrakeApply m23 : 46|2@1+ (1,0) [0|3] ""  gtw
 SG_ RCM_a045_eventDriverBrakeApply m45 : 46|2@1+ (1,0) [0|3] ""  gtw
 SG_ RCM_a067_eventDriverBrakeApply m67 : 46|2@1+ (1,0) [0|3] ""  gtw
 SG_ RCM_a018_eventDriverBrakeApply m18 : 46|2@1+ (1,0) [0|3] ""  gtw
 SG_ RCM_a089_eventDriverBrakeApply m89 : 46|2@1+ (1,0) [0|3] ""  gtw
 SG_ RCM_a090_eventDriverBrakeApply m90 : 46|2@1+ (1,0) [0|3] ""  gtw
 SG_ RCM_a107_eventDriverBrakeApply m107 : 46|2@1+ (1,0) [0|3] ""  gtw
 SG_ RCM_a024_eventDriverBrakeApply m24 : 46|2@1+ (1,0) [0|3] ""  gtw
 SG_ RCM_a042_eventDriverBrakeApply m42 : 46|2@1+ (1,0) [0|3] ""  gtw
 SG_ RCM_a006_eventDriverBrakeApply m6 : 46|2@1+ (1,0) [0|3] ""  gtw
 SG_ RCM_a079_eventDriverBrakeApply m79 : 46|2@1+ (1,0) [0|3] ""  gtw
 SG_ RCM_a060_eventDriverBrakeApply m60 : 46|2@1+ (1,0) [0|3] ""  gtw
 SG_ RCM_a097_eventDriverBrakeApply m97 : 46|2@1+ (1,0) [0|3] ""  gtw
 SG_ RCM_a074_eventDriverBrakeApply m74 : 46|2@1+ (1,0) [0|3] ""  gtw
 SG_ RCM_a012_eventDriverBrakeApply m12 : 46|2@1+ (1,0) [0|3] ""  gtw
 SG_ RCM_a030_eventDriverBrakeApply m30 : 46|2@1+ (1,0) [0|3] ""  gtw
 SG_ RCM_a056_eventDriverBrakeApply m56 : 46|2@1+ (1,0) [0|3] ""  gtw
 SG_ RCM_a113_eventDriverBrakeApply m113 : 46|2@1+ (1,0) [0|3] ""  gtw
 SG_ RCM_a083_eventDriverBrakeApply m83 : 46|2@1+ (1,0) [0|3] ""  gtw
 SG_ RCM_a029_eventDriverBrakeApply m29 : 46|2@1+ (1,0) [0|3] ""  gtw
 SG_ RCM_a101_eventDriverBrakeApply m101 : 46|2@1+ (1,0) [0|3] ""  gtw
 SG_ RCM_a022_eventDriverBrakeApply m22 : 46|2@1+ (1,0) [0|3] ""  gtw
 SG_ RCM_a019_eventDriverBrakeApply m19 : 46|2@1+ (1,0) [0|3] ""  gtw
 SG_ RCM_a088_eventDriverBrakeApply m88 : 46|2@1+ (1,0) [0|3] ""  gtw
 SG_ RCM_a091_eventDriverBrakeApply m91 : 46|2@1+ (1,0) [0|3] ""  gtw
 SG_ RCM_a066_eventDriverBrakeApply m66 : 46|2@1+ (1,0) [0|3] ""  gtw
 SG_ RCM_a000_eventDriverBrakeApply m0 : 46|2@1+ (1,0) [0|3] ""  gtw
 SG_ RCM_a044_eventDriverBrakeApply m44 : 46|2@1+ (1,0) [0|3] ""  gtw
 SG_ RCM_a118_eventDriverBrakeApply m118 : 46|2@1+ (1,0) [0|3] ""  gtw
 SG_ RCM_a059_eventSteeringAngle m59 : 45|14@0+ (0.1,-819.2) [-819.2|819] "deg"  gtw
 SG_ RCM_a026_eventSteeringAngle m26 : 45|14@0+ (0.1,-819.2) [-819.2|819] "deg"  gtw
 SG_ RCM_a105_eventSteeringAngle m105 : 45|14@0+ (0.1,-819.2) [-819.2|819] "deg"  gtw
 SG_ RCM_a040_eventSteeringAngle m40 : 45|14@0+ (0.1,-819.2) [-819.2|819] "deg"  gtw
 SG_ RCM_a062_eventSteeringAngle m62 : 45|14@0+ (0.1,-819.2) [-819.2|819] "deg"  gtw
 SG_ RCM_a095_eventSteeringAngle m95 : 45|14@0+ (0.1,-819.2) [-819.2|819] "deg"  gtw
 SG_ RCM_a004_eventSteeringAngle m4 : 45|14@0+ (0.1,-819.2) [-819.2|819] "deg"  gtw
 SG_ RCM_a047_eventSteeringAngle m47 : 45|14@0+ (0.1,-819.2) [-819.2|819] "deg"  gtw
 SG_ RCM_a092_eventSteeringAngle m92 : 45|14@0+ (0.1,-819.2) [-819.2|819] "deg"  gtw
 SG_ RCM_a065_eventSteeringAngle m65 : 45|14@0+ (0.1,-819.2) [-819.2|819] "deg"  gtw
 SG_ RCM_a003_eventSteeringAngle m3 : 45|14@0+ (0.1,-819.2) [-819.2|819] "deg"  gtw
 SG_ RCM_a102_eventSteeringAngle m102 : 45|14@0+ (0.1,-819.2) [-819.2|819] "deg"  gtw
 SG_ RCM_a021_eventSteeringAngle m21 : 45|14@0+ (0.1,-819.2) [-819.2|819] "deg"  gtw
 SG_ RCM_a038_eventSteeringAngle m38 : 45|14@0+ (0.1,-819.2) [-819.2|819] "deg"  gtw
 SG_ RCM_a017_eventSteeringAngle m17 : 45|14@0+ (0.1,-819.2) [-819.2|819] "deg"  gtw
 SG_ RCM_a086_eventSteeringAngle m86 : 45|14@0+ (0.1,-819.2) [-819.2|819] "deg"  gtw
 SG_ RCM_a116_eventSteeringAngle m116 : 45|14@0+ (0.1,-819.2) [-819.2|819] "deg"  gtw
 SG_ RCM_a053_eventSteeringAngle m53 : 45|14@0+ (0.1,-819.2) [-819.2|819] "deg"  gtw
 SG_ RCM_a035_eventSteeringAngle m35 : 45|14@0+ (0.1,-819.2) [-819.2|819] "deg"  gtw
 SG_ RCM_a068_eventSteeringAngle m68 : 45|14@0+ (0.1,-819.2) [-819.2|819] "deg"  gtw
 SG_ RCM_a071_eventSteeringAngle m71 : 45|14@0+ (0.1,-819.2) [-819.2|819] "deg"  gtw
 SG_ RCM_a050_eventSteeringAngle m50 : 45|14@0+ (0.1,-819.2) [-819.2|819] "deg"  gtw
 SG_ RCM_a115_eventSteeringAngle m115 : 45|14@0+ (0.1,-819.2) [-819.2|819] "deg"  gtw
 SG_ RCM_a036_eventSteeringAngle m36 : 45|14@0+ (0.1,-819.2) [-819.2|819] "deg"  gtw
 SG_ RCM_a072_eventSteeringAngle m72 : 45|14@0+ (0.1,-819.2) [-819.2|819] "deg"  gtw
 SG_ RCM_a014_eventSteeringAngle m14 : 45|14@0+ (0.1,-819.2) [-819.2|819] "deg"  gtw
 SG_ RCM_a049_eventSteeringAngle m49 : 45|14@0+ (0.1,-819.2) [-819.2|819] "deg"  gtw
 SG_ RCM_a085_eventSteeringAngle m85 : 45|14@0+ (0.1,-819.2) [-819.2|819] "deg"  gtw
 SG_ RCM_a080_eventSteeringAngle m80 : 45|14@0+ (0.1,-819.2) [-819.2|819] "deg"  gtw
 SG_ RCM_a011_eventSteeringAngle m11 : 45|14@0+ (0.1,-819.2) [-819.2|819] "deg"  gtw
 SG_ RCM_a033_eventSteeringAngle m33 : 45|14@0+ (0.1,-819.2) [-819.2|819] "deg"  gtw
 SG_ RCM_a109_eventSteeringAngle m109 : 45|14@0+ (0.1,-819.2) [-819.2|819] "deg"  gtw
 SG_ RCM_a099_eventSteeringAngle m99 : 45|14@0+ (0.1,-819.2) [-819.2|819] "deg"  gtw
 SG_ RCM_a055_eventSteeringAngle m55 : 45|14@0+ (0.1,-819.2) [-819.2|819] "deg"  gtw
 SG_ RCM_a110_eventSteeringAngle m110 : 45|14@0+ (0.1,-819.2) [-819.2|819] "deg"  gtw
 SG_ RCM_a008_eventSteeringAngle m8 : 45|14@0+ (0.1,-819.2) [-819.2|819] "deg"  gtw
 SG_ RCM_a077_eventSteeringAngle m77 : 45|14@0+ (0.1,-819.2) [-819.2|819] "deg"  gtw
 SG_ RCM_a061_eventSteeringAngle m61 : 45|14@0+ (0.1,-819.2) [-819.2|819] "deg"  gtw
 SG_ RCM_a078_eventSteeringAngle m78 : 45|14@0+ (0.1,-819.2) [-819.2|819] "deg"  gtw
 SG_ RCM_a007_eventSteeringAngle m7 : 45|14@0+ (0.1,-819.2) [-819.2|819] "deg"  gtw
 SG_ RCM_a043_eventSteeringAngle m43 : 45|14@0+ (0.1,-819.2) [-819.2|819] "deg"  gtw
 SG_ RCM_a096_eventSteeringAngle m96 : 45|14@0+ (0.1,-819.2) [-819.2|819] "deg"  gtw
 SG_ RCM_a025_eventSteeringAngle m25 : 45|14@0+ (0.1,-819.2) [-819.2|819] "deg"  gtw
 SG_ RCM_a106_eventSteeringAngle m106 : 45|14@0+ (0.1,-819.2) [-819.2|819] "deg"  gtw
 SG_ RCM_a020_eventSteeringAngle m20 : 45|14@0+ (0.1,-819.2) [-819.2|819] "deg"  gtw
 SG_ RCM_a103_eventSteeringAngle m103 : 45|14@0+ (0.1,-819.2) [-819.2|819] "deg"  gtw
 SG_ RCM_a039_eventSteeringAngle m39 : 45|14@0+ (0.1,-819.2) [-819.2|819] "deg"  gtw
 SG_ RCM_a046_eventSteeringAngle m46 : 45|14@0+ (0.1,-819.2) [-819.2|819] "deg"  gtw
 SG_ RCM_a093_eventSteeringAngle m93 : 45|14@0+ (0.1,-819.2) [-819.2|819] "deg"  gtw
 SG_ RCM_a064_eventSteeringAngle m64 : 45|14@0+ (0.1,-819.2) [-819.2|819] "deg"  gtw
 SG_ RCM_a002_eventSteeringAngle m2 : 45|14@0+ (0.1,-819.2) [-819.2|819] "deg"  gtw
 SG_ RCM_a067_eventSteeringAngle m67 : 45|14@0+ (0.1,-819.2) [-819.2|819] "deg"  gtw
 SG_ RCM_a018_eventSteeringAngle m18 : 45|14@0+ (0.1,-819.2) [-819.2|819] "deg"  gtw
 SG_ RCM_a001_eventSteeringAngle m1 : 45|14@0+ (0.1,-819.2) [-819.2|819] "deg"  gtw
 SG_ RCM_a100_eventSteeringAngle m100 : 45|14@0+ (0.1,-819.2) [-819.2|819] "deg"  gtw
 SG_ RCM_a023_eventSteeringAngle m23 : 45|14@0+ (0.1,-819.2) [-819.2|819] "deg"  gtw
 SG_ RCM_a045_eventSteeringAngle m45 : 45|14@0+ (0.1,-819.2) [-819.2|819] "deg"  gtw
 SG_ RCM_a089_eventSteeringAngle m89 : 45|14@0+ (0.1,-819.2) [-819.2|819] "deg"  gtw
 SG_ RCM_a090_eventSteeringAngle m90 : 45|14@0+ (0.1,-819.2) [-819.2|819] "deg"  gtw
 SG_ RCM_a015_eventSteeringAngle m15 : 45|14@0+ (0.1,-819.2) [-819.2|819] "deg"  gtw
 SG_ RCM_a037_eventSteeringAngle m37 : 45|14@0+ (0.1,-819.2) [-819.2|819] "deg"  gtw
 SG_ RCM_a051_eventSteeringAngle m51 : 45|14@0+ (0.1,-819.2) [-819.2|819] "deg"  gtw
 SG_ RCM_a114_eventSteeringAngle m114 : 45|14@0+ (0.1,-819.2) [-819.2|819] "deg"  gtw
 SG_ RCM_a073_eventSteeringAngle m73 : 45|14@0+ (0.1,-819.2) [-819.2|819] "deg"  gtw
 SG_ RCM_a048_eventSteeringAngle m48 : 45|14@0+ (0.1,-819.2) [-819.2|819] "deg"  gtw
 SG_ RCM_a084_eventSteeringAngle m84 : 45|14@0+ (0.1,-819.2) [-819.2|819] "deg"  gtw
 SG_ RCM_a083_eventSteeringAngle m83 : 45|14@0+ (0.1,-819.2) [-819.2|819] "deg"  gtw
 SG_ RCM_a012_eventSteeringAngle m12 : 45|14@0+ (0.1,-819.2) [-819.2|819] "deg"  gtw
 SG_ RCM_a056_eventSteeringAngle m56 : 45|14@0+ (0.1,-819.2) [-819.2|819] "deg"  gtw
 SG_ RCM_a113_eventSteeringAngle m113 : 45|14@0+ (0.1,-819.2) [-819.2|819] "deg"  gtw
 SG_ RCM_a029_eventSteeringAngle m29 : 45|14@0+ (0.1,-819.2) [-819.2|819] "deg"  gtw
 SG_ RCM_a030_eventSteeringAngle m30 : 45|14@0+ (0.1,-819.2) [-819.2|819] "deg"  gtw
 SG_ RCM_a074_eventSteeringAngle m74 : 45|14@0+ (0.1,-819.2) [-819.2|819] "deg"  gtw
 SG_ RCM_a107_eventSteeringAngle m107 : 45|14@0+ (0.1,-819.2) [-819.2|819] "deg"  gtw
 SG_ RCM_a024_eventSteeringAngle m24 : 45|14@0+ (0.1,-819.2) [-819.2|819] "deg"  gtw
 SG_ RCM_a060_eventSteeringAngle m60 : 45|14@0+ (0.1,-819.2) [-819.2|819] "deg"  gtw
 SG_ RCM_a079_eventSteeringAngle m79 : 45|14@0+ (0.1,-819.2) [-819.2|819] "deg"  gtw
 SG_ RCM_a006_eventSteeringAngle m6 : 45|14@0+ (0.1,-819.2) [-819.2|819] "deg"  gtw
 SG_ RCM_a042_eventSteeringAngle m42 : 45|14@0+ (0.1,-819.2) [-819.2|819] "deg"  gtw
 SG_ RCM_a097_eventSteeringAngle m97 : 45|14@0+ (0.1,-819.2) [-819.2|819] "deg"  gtw
 SG_ RCM_a041_eventSteeringAngle m41 : 45|14@0+ (0.1,-819.2) [-819.2|819] "deg"  gtw
 SG_ RCM_a094_eventSteeringAngle m94 : 45|14@0+ (0.1,-819.2) [-819.2|819] "deg"  gtw
 SG_ RCM_a058_eventSteeringAngle m58 : 45|14@0+ (0.1,-819.2) [-819.2|819] "deg"  gtw
 SG_ RCM_a005_eventSteeringAngle m5 : 45|14@0+ (0.1,-819.2) [-819.2|819] "deg"  gtw
 SG_ RCM_a027_eventSteeringAngle m27 : 45|14@0+ (0.1,-819.2) [-819.2|819] "deg"  gtw
 SG_ RCM_a104_eventSteeringAngle m104 : 45|14@0+ (0.1,-819.2) [-819.2|819] "deg"  gtw
 SG_ RCM_a063_eventSteeringAngle m63 : 45|14@0+ (0.1,-819.2) [-819.2|819] "deg"  gtw
 SG_ RCM_a022_eventSteeringAngle m22 : 45|14@0+ (0.1,-819.2) [-819.2|819] "deg"  gtw
 SG_ RCM_a101_eventSteeringAngle m101 : 45|14@0+ (0.1,-819.2) [-819.2|819] "deg"  gtw
 SG_ RCM_a118_eventSteeringAngle m118 : 45|14@0+ (0.1,-819.2) [-819.2|819] "deg"  gtw
 SG_ RCM_a000_eventSteeringAngle m0 : 45|14@0+ (0.1,-819.2) [-819.2|819] "deg"  gtw
 SG_ RCM_a044_eventSteeringAngle m44 : 45|14@0+ (0.1,-819.2) [-819.2|819] "deg"  gtw
 SG_ RCM_a066_eventSteeringAngle m66 : 45|14@0+ (0.1,-819.2) [-819.2|819] "deg"  gtw
 SG_ RCM_a088_eventSteeringAngle m88 : 45|14@0+ (0.1,-819.2) [-819.2|819] "deg"  gtw
 SG_ RCM_a019_eventSteeringAngle m19 : 45|14@0+ (0.1,-819.2) [-819.2|819] "deg"  gtw
 SG_ RCM_a091_eventSteeringAngle m91 : 45|14@0+ (0.1,-819.2) [-819.2|819] "deg"  gtw
 SG_ RCM_a087_eventSteeringAngle m87 : 45|14@0+ (0.1,-819.2) [-819.2|819] "deg"  gtw
 SG_ RCM_a034_eventSteeringAngle m34 : 45|14@0+ (0.1,-819.2) [-819.2|819] "deg"  gtw
 SG_ RCM_a052_eventSteeringAngle m52 : 45|14@0+ (0.1,-819.2) [-819.2|819] "deg"  gtw
 SG_ RCM_a117_eventSteeringAngle m117 : 45|14@0+ (0.1,-819.2) [-819.2|819] "deg"  gtw
 SG_ RCM_a069_eventSteeringAngle m69 : 45|14@0+ (0.1,-819.2) [-819.2|819] "deg"  gtw
 SG_ RCM_a016_eventSteeringAngle m16 : 45|14@0+ (0.1,-819.2) [-819.2|819] "deg"  gtw
 SG_ RCM_a070_eventSteeringAngle m70 : 45|14@0+ (0.1,-819.2) [-819.2|819] "deg"  gtw
 SG_ RCM_a075_eventSteeringAngle m75 : 45|14@0+ (0.1,-819.2) [-819.2|819] "deg"  gtw
 SG_ RCM_a013_eventSteeringAngle m13 : 45|14@0+ (0.1,-819.2) [-819.2|819] "deg"  gtw
 SG_ RCM_a112_eventSteeringAngle m112 : 45|14@0+ (0.1,-819.2) [-819.2|819] "deg"  gtw
 SG_ RCM_a057_eventSteeringAngle m57 : 45|14@0+ (0.1,-819.2) [-819.2|819] "deg"  gtw
 SG_ RCM_a082_eventSteeringAngle m82 : 45|14@0+ (0.1,-819.2) [-819.2|819] "deg"  gtw
 SG_ RCM_a028_eventSteeringAngle m28 : 45|14@0+ (0.1,-819.2) [-819.2|819] "deg"  gtw
 SG_ RCM_a031_eventSteeringAngle m31 : 45|14@0+ (0.1,-819.2) [-819.2|819] "deg"  gtw
 SG_ RCM_a010_eventSteeringAngle m10 : 45|14@0+ (0.1,-819.2) [-819.2|819] "deg"  gtw
 SG_ RCM_a054_eventSteeringAngle m54 : 45|14@0+ (0.1,-819.2) [-819.2|819] "deg"  gtw
 SG_ RCM_a111_eventSteeringAngle m111 : 45|14@0+ (0.1,-819.2) [-819.2|819] "deg"  gtw
 SG_ RCM_a081_eventSteeringAngle m81 : 45|14@0+ (0.1,-819.2) [-819.2|819] "deg"  gtw
 SG_ RCM_a108_eventSteeringAngle m108 : 45|14@0+ (0.1,-819.2) [-819.2|819] "deg"  gtw
 SG_ RCM_a032_eventSteeringAngle m32 : 45|14@0+ (0.1,-819.2) [-819.2|819] "deg"  gtw
 SG_ RCM_a098_eventSteeringAngle m98 : 45|14@0+ (0.1,-819.2) [-819.2|819] "deg"  gtw
 SG_ RCM_a076_eventSteeringAngle m76 : 45|14@0+ (0.1,-819.2) [-819.2|819] "deg"  gtw
 SG_ RCM_a009_eventSteeringAngle m9 : 45|14@0+ (0.1,-819.2) [-819.2|819] "deg"  gtw
 SG_ RCM_a007_eventVehicleSpeed m7 : 28|12@1+ (0.08,-40) [-40|285] "kph"  gtw
 SG_ RCM_a078_eventVehicleSpeed m78 : 28|12@1+ (0.08,-40) [-40|285] "kph"  gtw
 SG_ RCM_a061_eventVehicleSpeed m61 : 28|12@1+ (0.08,-40) [-40|285] "kph"  gtw
 SG_ RCM_a106_eventVehicleSpeed m106 : 28|12@1+ (0.08,-40) [-40|285] "kph"  gtw
 SG_ RCM_a025_eventVehicleSpeed m25 : 28|12@1+ (0.08,-40) [-40|285] "kph"  gtw
 SG_ RCM_a096_eventVehicleSpeed m96 : 28|12@1+ (0.08,-40) [-40|285] "kph"  gtw
 SG_ RCM_a043_eventVehicleSpeed m43 : 28|12@1+ (0.08,-40) [-40|285] "kph"  gtw
 SG_ RCM_a033_eventVehicleSpeed m33 : 28|12@1+ (0.08,-40) [-40|285] "kph"  gtw
 SG_ RCM_a080_eventVehicleSpeed m80 : 28|12@1+ (0.08,-40) [-40|285] "kph"  gtw
 SG_ RCM_a077_eventVehicleSpeed m77 : 28|12@1+ (0.08,-40) [-40|285] "kph"  gtw
 SG_ RCM_a008_eventVehicleSpeed m8 : 28|12@1+ (0.08,-40) [-40|285] "kph"  gtw
 SG_ RCM_a109_eventVehicleSpeed m109 : 28|12@1+ (0.08,-40) [-40|285] "kph"  gtw
 SG_ RCM_a099_eventVehicleSpeed m99 : 28|12@1+ (0.08,-40) [-40|285] "kph"  gtw
 SG_ RCM_a055_eventVehicleSpeed m55 : 28|12@1+ (0.08,-40) [-40|285] "kph"  gtw
 SG_ RCM_a110_eventVehicleSpeed m110 : 28|12@1+ (0.08,-40) [-40|285] "kph"  gtw
 SG_ RCM_a011_eventVehicleSpeed m11 : 28|12@1+ (0.08,-40) [-40|285] "kph"  gtw
 SG_ RCM_a036_eventVehicleSpeed m36 : 28|12@1+ (0.08,-40) [-40|285] "kph"  gtw
 SG_ RCM_a115_eventVehicleSpeed m115 : 28|12@1+ (0.08,-40) [-40|285] "kph"  gtw
 SG_ RCM_a050_eventVehicleSpeed m50 : 28|12@1+ (0.08,-40) [-40|285] "kph"  gtw
 SG_ RCM_a085_eventVehicleSpeed m85 : 28|12@1+ (0.08,-40) [-40|285] "kph"  gtw
 SG_ RCM_a014_eventVehicleSpeed m14 : 28|12@1+ (0.08,-40) [-40|285] "kph"  gtw
 SG_ RCM_a049_eventVehicleSpeed m49 : 28|12@1+ (0.08,-40) [-40|285] "kph"  gtw
 SG_ RCM_a072_eventVehicleSpeed m72 : 28|12@1+ (0.08,-40) [-40|285] "kph"  gtw
 SG_ RCM_a107_eventVehicleSpeed m107 : 28|12@1+ (0.08,-40) [-40|285] "kph"  gtw
 SG_ RCM_a024_eventVehicleSpeed m24 : 28|12@1+ (0.08,-40) [-40|285] "kph"  gtw
 SG_ RCM_a060_eventVehicleSpeed m60 : 28|12@1+ (0.08,-40) [-40|285] "kph"  gtw
 SG_ RCM_a079_eventVehicleSpeed m79 : 28|12@1+ (0.08,-40) [-40|285] "kph"  gtw
 SG_ RCM_a006_eventVehicleSpeed m6 : 28|12@1+ (0.08,-40) [-40|285] "kph"  gtw
 SG_ RCM_a097_eventVehicleSpeed m97 : 28|12@1+ (0.08,-40) [-40|285] "kph"  gtw
 SG_ RCM_a042_eventVehicleSpeed m42 : 28|12@1+ (0.08,-40) [-40|285] "kph"  gtw
 SG_ RCM_a074_eventVehicleSpeed m74 : 28|12@1+ (0.08,-40) [-40|285] "kph"  gtw
 SG_ RCM_a012_eventVehicleSpeed m12 : 28|12@1+ (0.08,-40) [-40|285] "kph"  gtw
 SG_ RCM_a030_eventVehicleSpeed m30 : 28|12@1+ (0.08,-40) [-40|285] "kph"  gtw
 SG_ RCM_a113_eventVehicleSpeed m113 : 28|12@1+ (0.08,-40) [-40|285] "kph"  gtw
 SG_ RCM_a056_eventVehicleSpeed m56 : 28|12@1+ (0.08,-40) [-40|285] "kph"  gtw
 SG_ RCM_a083_eventVehicleSpeed m83 : 28|12@1+ (0.08,-40) [-40|285] "kph"  gtw
 SG_ RCM_a029_eventVehicleSpeed m29 : 28|12@1+ (0.08,-40) [-40|285] "kph"  gtw
 SG_ RCM_a084_eventVehicleSpeed m84 : 28|12@1+ (0.08,-40) [-40|285] "kph"  gtw
 SG_ RCM_a073_eventVehicleSpeed m73 : 28|12@1+ (0.08,-40) [-40|285] "kph"  gtw
 SG_ RCM_a114_eventVehicleSpeed m114 : 28|12@1+ (0.08,-40) [-40|285] "kph"  gtw
 SG_ RCM_a051_eventVehicleSpeed m51 : 28|12@1+ (0.08,-40) [-40|285] "kph"  gtw
 SG_ RCM_a015_eventVehicleSpeed m15 : 28|12@1+ (0.08,-40) [-40|285] "kph"  gtw
 SG_ RCM_a048_eventVehicleSpeed m48 : 28|12@1+ (0.08,-40) [-40|285] "kph"  gtw
 SG_ RCM_a037_eventVehicleSpeed m37 : 28|12@1+ (0.08,-40) [-40|285] "kph"  gtw
 SG_ RCM_a090_eventVehicleSpeed m90 : 28|12@1+ (0.08,-40) [-40|285] "kph"  gtw
 SG_ RCM_a089_eventVehicleSpeed m89 : 28|12@1+ (0.08,-40) [-40|285] "kph"  gtw
 SG_ RCM_a018_eventVehicleSpeed m18 : 28|12@1+ (0.08,-40) [-40|285] "kph"  gtw
 SG_ RCM_a045_eventVehicleSpeed m45 : 28|12@1+ (0.08,-40) [-40|285] "kph"  gtw
 SG_ RCM_a001_eventVehicleSpeed m1 : 28|12@1+ (0.08,-40) [-40|285] "kph"  gtw
 SG_ RCM_a067_eventVehicleSpeed m67 : 28|12@1+ (0.08,-40) [-40|285] "kph"  gtw
 SG_ RCM_a023_eventVehicleSpeed m23 : 28|12@1+ (0.08,-40) [-40|285] "kph"  gtw
 SG_ RCM_a100_eventVehicleSpeed m100 : 28|12@1+ (0.08,-40) [-40|285] "kph"  gtw
 SG_ RCM_a112_eventVehicleSpeed m112 : 28|12@1+ (0.08,-40) [-40|285] "kph"  gtw
 SG_ RCM_a057_eventVehicleSpeed m57 : 28|12@1+ (0.08,-40) [-40|285] "kph"  gtw
 SG_ RCM_a082_eventVehicleSpeed m82 : 28|12@1+ (0.08,-40) [-40|285] "kph"  gtw
 SG_ RCM_a028_eventVehicleSpeed m28 : 28|12@1+ (0.08,-40) [-40|285] "kph"  gtw
 SG_ RCM_a075_eventVehicleSpeed m75 : 28|12@1+ (0.08,-40) [-40|285] "kph"  gtw
 SG_ RCM_a013_eventVehicleSpeed m13 : 28|12@1+ (0.08,-40) [-40|285] "kph"  gtw
 SG_ RCM_a031_eventVehicleSpeed m31 : 28|12@1+ (0.08,-40) [-40|285] "kph"  gtw
 SG_ RCM_a016_eventVehicleSpeed m16 : 28|12@1+ (0.08,-40) [-40|285] "kph"  gtw
 SG_ RCM_a069_eventVehicleSpeed m69 : 28|12@1+ (0.08,-40) [-40|285] "kph"  gtw
 SG_ RCM_a087_eventVehicleSpeed m87 : 28|12@1+ (0.08,-40) [-40|285] "kph"  gtw
 SG_ RCM_a052_eventVehicleSpeed m52 : 28|12@1+ (0.08,-40) [-40|285] "kph"  gtw
 SG_ RCM_a117_eventVehicleSpeed m117 : 28|12@1+ (0.08,-40) [-40|285] "kph"  gtw
 SG_ RCM_a070_eventVehicleSpeed m70 : 28|12@1+ (0.08,-40) [-40|285] "kph"  gtw
 SG_ RCM_a034_eventVehicleSpeed m34 : 28|12@1+ (0.08,-40) [-40|285] "kph"  gtw
 SG_ RCM_a019_eventVehicleSpeed m19 : 28|12@1+ (0.08,-40) [-40|285] "kph"  gtw
 SG_ RCM_a091_eventVehicleSpeed m91 : 28|12@1+ (0.08,-40) [-40|285] "kph"  gtw
 SG_ RCM_a066_eventVehicleSpeed m66 : 28|12@1+ (0.08,-40) [-40|285] "kph"  gtw
 SG_ RCM_a088_eventVehicleSpeed m88 : 28|12@1+ (0.08,-40) [-40|285] "kph"  gtw
 SG_ RCM_a101_eventVehicleSpeed m101 : 28|12@1+ (0.08,-40) [-40|285] "kph"  gtw
 SG_ RCM_a022_eventVehicleSpeed m22 : 28|12@1+ (0.08,-40) [-40|285] "kph"  gtw
 SG_ RCM_a044_eventVehicleSpeed m44 : 28|12@1+ (0.08,-40) [-40|285] "kph"  gtw
 SG_ RCM_a118_eventVehicleSpeed m118 : 28|12@1+ (0.08,-40) [-40|285] "kph"  gtw
 SG_ RCM_a000_eventVehicleSpeed m0 : 28|12@1+ (0.08,-40) [-40|285] "kph"  gtw
 SG_ RCM_a094_eventVehicleSpeed m94 : 28|12@1+ (0.08,-40) [-40|285] "kph"  gtw
 SG_ RCM_a041_eventVehicleSpeed m41 : 28|12@1+ (0.08,-40) [-40|285] "kph"  gtw
 SG_ RCM_a063_eventVehicleSpeed m63 : 28|12@1+ (0.08,-40) [-40|285] "kph"  gtw
 SG_ RCM_a005_eventVehicleSpeed m5 : 28|12@1+ (0.08,-40) [-40|285] "kph"  gtw
 SG_ RCM_a104_eventVehicleSpeed m104 : 28|12@1+ (0.08,-40) [-40|285] "kph"  gtw
 SG_ RCM_a027_eventVehicleSpeed m27 : 28|12@1+ (0.08,-40) [-40|285] "kph"  gtw
 SG_ RCM_a058_eventVehicleSpeed m58 : 28|12@1+ (0.08,-40) [-40|285] "kph"  gtw
 SG_ RCM_a086_eventVehicleSpeed m86 : 28|12@1+ (0.08,-40) [-40|285] "kph"  gtw
 SG_ RCM_a071_eventVehicleSpeed m71 : 28|12@1+ (0.08,-40) [-40|285] "kph"  gtw
 SG_ RCM_a017_eventVehicleSpeed m17 : 28|12@1+ (0.08,-40) [-40|285] "kph"  gtw
 SG_ RCM_a035_eventVehicleSpeed m35 : 28|12@1+ (0.08,-40) [-40|285] "kph"  gtw
 SG_ RCM_a068_eventVehicleSpeed m68 : 28|12@1+ (0.08,-40) [-40|285] "kph"  gtw
 SG_ RCM_a116_eventVehicleSpeed m116 : 28|12@1+ (0.08,-40) [-40|285] "kph"  gtw
 SG_ RCM_a053_eventVehicleSpeed m53 : 28|12@1+ (0.08,-40) [-40|285] "kph"  gtw
 SG_ RCM_a102_eventVehicleSpeed m102 : 28|12@1+ (0.08,-40) [-40|285] "kph"  gtw
 SG_ RCM_a021_eventVehicleSpeed m21 : 28|12@1+ (0.08,-40) [-40|285] "kph"  gtw
 SG_ RCM_a047_eventVehicleSpeed m47 : 28|12@1+ (0.08,-40) [-40|285] "kph"  gtw
 SG_ RCM_a003_eventVehicleSpeed m3 : 28|12@1+ (0.08,-40) [-40|285] "kph"  gtw
 SG_ RCM_a038_eventVehicleSpeed m38 : 28|12@1+ (0.08,-40) [-40|285] "kph"  gtw
 SG_ RCM_a092_eventVehicleSpeed m92 : 28|12@1+ (0.08,-40) [-40|285] "kph"  gtw
 SG_ RCM_a065_eventVehicleSpeed m65 : 28|12@1+ (0.08,-40) [-40|285] "kph"  gtw
 SG_ RCM_a095_eventVehicleSpeed m95 : 28|12@1+ (0.08,-40) [-40|285] "kph"  gtw
 SG_ RCM_a062_eventVehicleSpeed m62 : 28|12@1+ (0.08,-40) [-40|285] "kph"  gtw
 SG_ RCM_a105_eventVehicleSpeed m105 : 28|12@1+ (0.08,-40) [-40|285] "kph"  gtw
 SG_ RCM_a026_eventVehicleSpeed m26 : 28|12@1+ (0.08,-40) [-40|285] "kph"  gtw
 SG_ RCM_a040_eventVehicleSpeed m40 : 28|12@1+ (0.08,-40) [-40|285] "kph"  gtw
 SG_ RCM_a059_eventVehicleSpeed m59 : 28|12@1+ (0.08,-40) [-40|285] "kph"  gtw
 SG_ RCM_a004_eventVehicleSpeed m4 : 28|12@1+ (0.08,-40) [-40|285] "kph"  gtw
 SG_ RCM_a098_eventVehicleSpeed m98 : 28|12@1+ (0.08,-40) [-40|285] "kph"  gtw
 SG_ RCM_a111_eventVehicleSpeed m111 : 28|12@1+ (0.08,-40) [-40|285] "kph"  gtw
 SG_ RCM_a054_eventVehicleSpeed m54 : 28|12@1+ (0.08,-40) [-40|285] "kph"  gtw
 SG_ RCM_a081_eventVehicleSpeed m81 : 28|12@1+ (0.08,-40) [-40|285] "kph"  gtw
 SG_ RCM_a009_eventVehicleSpeed m9 : 28|12@1+ (0.08,-40) [-40|285] "kph"  gtw
 SG_ RCM_a076_eventVehicleSpeed m76 : 28|12@1+ (0.08,-40) [-40|285] "kph"  gtw
 SG_ RCM_a108_eventVehicleSpeed m108 : 28|12@1+ (0.08,-40) [-40|285] "kph"  gtw
 SG_ RCM_a032_eventVehicleSpeed m32 : 28|12@1+ (0.08,-40) [-40|285] "kph"  gtw
 SG_ RCM_a010_eventVehicleSpeed m10 : 28|12@1+ (0.08,-40) [-40|285] "kph"  gtw
 SG_ RCM_a046_eventVehicleSpeed m46 : 28|12@1+ (0.08,-40) [-40|285] "kph"  gtw
 SG_ RCM_a103_eventVehicleSpeed m103 : 28|12@1+ (0.08,-40) [-40|285] "kph"  gtw
 SG_ RCM_a020_eventVehicleSpeed m20 : 28|12@1+ (0.08,-40) [-40|285] "kph"  gtw
 SG_ RCM_a039_eventVehicleSpeed m39 : 28|12@1+ (0.08,-40) [-40|285] "kph"  gtw
 SG_ RCM_a064_eventVehicleSpeed m64 : 28|12@1+ (0.08,-40) [-40|285] "kph"  gtw
 SG_ RCM_a002_eventVehicleSpeed m2 : 28|12@1+ (0.08,-40) [-40|285] "kph"  gtw
 SG_ RCM_a093_eventVehicleSpeed m93 : 28|12@1+ (0.08,-40) [-40|285] "kph"  gtw
 SG_ RCM_a072_eventFrontRightSeatbelt m72 : 27|1@1+ (1,0) [0|1] ""  gtw
 SG_ RCM_a014_eventFrontRightSeatbelt m14 : 27|1@1+ (1,0) [0|1] ""  gtw
 SG_ RCM_a049_eventFrontRightSeatbelt m49 : 27|1@1+ (1,0) [0|1] ""  gtw
 SG_ RCM_a115_eventFrontRightSeatbelt m115 : 27|1@1+ (1,0) [0|1] ""  gtw
 SG_ RCM_a050_eventFrontRightSeatbelt m50 : 27|1@1+ (1,0) [0|1] ""  gtw
 SG_ RCM_a085_eventFrontRightSeatbelt m85 : 27|1@1+ (1,0) [0|1] ""  gtw
 SG_ RCM_a036_eventFrontRightSeatbelt m36 : 27|1@1+ (1,0) [0|1] ""  gtw
 SG_ RCM_a064_eventFrontRightSeatbelt m64 : 27|1@1+ (1,0) [0|1] ""  gtw
 SG_ RCM_a046_eventFrontRightSeatbelt m46 : 27|1@1+ (1,0) [0|1] ""  gtw
 SG_ RCM_a103_eventFrontRightSeatbelt m103 : 27|1@1+ (1,0) [0|1] ""  gtw
 SG_ RCM_a020_eventFrontRightSeatbelt m20 : 27|1@1+ (1,0) [0|1] ""  gtw
 SG_ RCM_a039_eventFrontRightSeatbelt m39 : 27|1@1+ (1,0) [0|1] ""  gtw
 SG_ RCM_a002_eventFrontRightSeatbelt m2 : 27|1@1+ (1,0) [0|1] ""  gtw
 SG_ RCM_a093_eventFrontRightSeatbelt m93 : 27|1@1+ (1,0) [0|1] ""  gtw
 SG_ RCM_a106_eventFrontRightSeatbelt m106 : 27|1@1+ (1,0) [0|1] ""  gtw
 SG_ RCM_a025_eventFrontRightSeatbelt m25 : 27|1@1+ (1,0) [0|1] ""  gtw
 SG_ RCM_a061_eventFrontRightSeatbelt m61 : 27|1@1+ (1,0) [0|1] ""  gtw
 SG_ RCM_a096_eventFrontRightSeatbelt m96 : 27|1@1+ (1,0) [0|1] ""  gtw
 SG_ RCM_a078_eventFrontRightSeatbelt m78 : 27|1@1+ (1,0) [0|1] ""  gtw
 SG_ RCM_a007_eventFrontRightSeatbelt m7 : 27|1@1+ (1,0) [0|1] ""  gtw
 SG_ RCM_a043_eventFrontRightSeatbelt m43 : 27|1@1+ (1,0) [0|1] ""  gtw
 SG_ RCM_a073_eventFrontRightSeatbelt m73 : 27|1@1+ (1,0) [0|1] ""  gtw
 SG_ RCM_a015_eventFrontRightSeatbelt m15 : 27|1@1+ (1,0) [0|1] ""  gtw
 SG_ RCM_a048_eventFrontRightSeatbelt m48 : 27|1@1+ (1,0) [0|1] ""  gtw
 SG_ RCM_a114_eventFrontRightSeatbelt m114 : 27|1@1+ (1,0) [0|1] ""  gtw
 SG_ RCM_a051_eventFrontRightSeatbelt m51 : 27|1@1+ (1,0) [0|1] ""  gtw
 SG_ RCM_a084_eventFrontRightSeatbelt m84 : 27|1@1+ (1,0) [0|1] ""  gtw
 SG_ RCM_a037_eventFrontRightSeatbelt m37 : 27|1@1+ (1,0) [0|1] ""  gtw
 SG_ RCM_a067_eventFrontRightSeatbelt m67 : 27|1@1+ (1,0) [0|1] ""  gtw
 SG_ RCM_a089_eventFrontRightSeatbelt m89 : 27|1@1+ (1,0) [0|1] ""  gtw
 SG_ RCM_a100_eventFrontRightSeatbelt m100 : 27|1@1+ (1,0) [0|1] ""  gtw
 SG_ RCM_a023_eventFrontRightSeatbelt m23 : 27|1@1+ (1,0) [0|1] ""  gtw
 SG_ RCM_a090_eventFrontRightSeatbelt m90 : 27|1@1+ (1,0) [0|1] ""  gtw
 SG_ RCM_a001_eventFrontRightSeatbelt m1 : 27|1@1+ (1,0) [0|1] ""  gtw
 SG_ RCM_a018_eventFrontRightSeatbelt m18 : 27|1@1+ (1,0) [0|1] ""  gtw
 SG_ RCM_a045_eventFrontRightSeatbelt m45 : 27|1@1+ (1,0) [0|1] ""  gtw
 SG_ RCM_a107_eventFrontRightSeatbelt m107 : 27|1@1+ (1,0) [0|1] ""  gtw
 SG_ RCM_a024_eventFrontRightSeatbelt m24 : 27|1@1+ (1,0) [0|1] ""  gtw
 SG_ RCM_a097_eventFrontRightSeatbelt m97 : 27|1@1+ (1,0) [0|1] ""  gtw
 SG_ RCM_a060_eventFrontRightSeatbelt m60 : 27|1@1+ (1,0) [0|1] ""  gtw
 SG_ RCM_a006_eventFrontRightSeatbelt m6 : 27|1@1+ (1,0) [0|1] ""  gtw
 SG_ RCM_a079_eventFrontRightSeatbelt m79 : 27|1@1+ (1,0) [0|1] ""  gtw
 SG_ RCM_a042_eventFrontRightSeatbelt m42 : 27|1@1+ (1,0) [0|1] ""  gtw
 SG_ RCM_a113_eventFrontRightSeatbelt m113 : 27|1@1+ (1,0) [0|1] ""  gtw
 SG_ RCM_a056_eventFrontRightSeatbelt m56 : 27|1@1+ (1,0) [0|1] ""  gtw
 SG_ RCM_a074_eventFrontRightSeatbelt m74 : 27|1@1+ (1,0) [0|1] ""  gtw
 SG_ RCM_a029_eventFrontRightSeatbelt m29 : 27|1@1+ (1,0) [0|1] ""  gtw
 SG_ RCM_a012_eventFrontRightSeatbelt m12 : 27|1@1+ (1,0) [0|1] ""  gtw
 SG_ RCM_a083_eventFrontRightSeatbelt m83 : 27|1@1+ (1,0) [0|1] ""  gtw
 SG_ RCM_a030_eventFrontRightSeatbelt m30 : 27|1@1+ (1,0) [0|1] ""  gtw
 SG_ RCM_a066_eventFrontRightSeatbelt m66 : 27|1@1+ (1,0) [0|1] ""  gtw
 SG_ RCM_a019_eventFrontRightSeatbelt m19 : 27|1@1+ (1,0) [0|1] ""  gtw
 SG_ RCM_a091_eventFrontRightSeatbelt m91 : 27|1@1+ (1,0) [0|1] ""  gtw
 SG_ RCM_a118_eventFrontRightSeatbelt m118 : 27|1@1+ (1,0) [0|1] ""  gtw
 SG_ RCM_a044_eventFrontRightSeatbelt m44 : 27|1@1+ (1,0) [0|1] ""  gtw
 SG_ RCM_a088_eventFrontRightSeatbelt m88 : 27|1@1+ (1,0) [0|1] ""  gtw
 SG_ RCM_a000_eventFrontRightSeatbelt m0 : 27|1@1+ (1,0) [0|1] ""  gtw
 SG_ RCM_a101_eventFrontRightSeatbelt m101 : 27|1@1+ (1,0) [0|1] ""  gtw
 SG_ RCM_a022_eventFrontRightSeatbelt m22 : 27|1@1+ (1,0) [0|1] ""  gtw
 SG_ RCM_a094_eventFrontRightSeatbelt m94 : 27|1@1+ (1,0) [0|1] ""  gtw
 SG_ RCM_a041_eventFrontRightSeatbelt m41 : 27|1@1+ (1,0) [0|1] ""  gtw
 SG_ RCM_a027_eventFrontRightSeatbelt m27 : 27|1@1+ (1,0) [0|1] ""  gtw
 SG_ RCM_a104_eventFrontRightSeatbelt m104 : 27|1@1+ (1,0) [0|1] ""  gtw
 SG_ RCM_a063_eventFrontRightSeatbelt m63 : 27|1@1+ (1,0) [0|1] ""  gtw
 SG_ RCM_a005_eventFrontRightSeatbelt m5 : 27|1@1+ (1,0) [0|1] ""  gtw
 SG_ RCM_a058_eventFrontRightSeatbelt m58 : 27|1@1+ (1,0) [0|1] ""  gtw
 SG_ RCM_a028_eventFrontRightSeatbelt m28 : 27|1@1+ (1,0) [0|1] ""  gtw
 SG_ RCM_a082_eventFrontRightSeatbelt m82 : 27|1@1+ (1,0) [0|1] ""  gtw
 SG_ RCM_a013_eventFrontRightSeatbelt m13 : 27|1@1+ (1,0) [0|1] ""  gtw
 SG_ RCM_a031_eventFrontRightSeatbelt m31 : 27|1@1+ (1,0) [0|1] ""  gtw
 SG_ RCM_a112_eventFrontRightSeatbelt m112 : 27|1@1+ (1,0) [0|1] ""  gtw
 SG_ RCM_a057_eventFrontRightSeatbelt m57 : 27|1@1+ (1,0) [0|1] ""  gtw
 SG_ RCM_a075_eventFrontRightSeatbelt m75 : 27|1@1+ (1,0) [0|1] ""  gtw
 SG_ RCM_a087_eventFrontRightSeatbelt m87 : 27|1@1+ (1,0) [0|1] ""  gtw
 SG_ RCM_a016_eventFrontRightSeatbelt m16 : 27|1@1+ (1,0) [0|1] ""  gtw
 SG_ RCM_a117_eventFrontRightSeatbelt m117 : 27|1@1+ (1,0) [0|1] ""  gtw
 SG_ RCM_a052_eventFrontRightSeatbelt m52 : 27|1@1+ (1,0) [0|1] ""  gtw
 SG_ RCM_a070_eventFrontRightSeatbelt m70 : 27|1@1+ (1,0) [0|1] ""  gtw
 SG_ RCM_a034_eventFrontRightSeatbelt m34 : 27|1@1+ (1,0) [0|1] ""  gtw
 SG_ RCM_a069_eventFrontRightSeatbelt m69 : 27|1@1+ (1,0) [0|1] ""  gtw
 SG_ RCM_a004_eventFrontRightSeatbelt m4 : 27|1@1+ (1,0) [0|1] ""  gtw
 SG_ RCM_a040_eventFrontRightSeatbelt m40 : 27|1@1+ (1,0) [0|1] ""  gtw
 SG_ RCM_a062_eventFrontRightSeatbelt m62 : 27|1@1+ (1,0) [0|1] ""  gtw
 SG_ RCM_a059_eventFrontRightSeatbelt m59 : 27|1@1+ (1,0) [0|1] ""  gtw
 SG_ RCM_a105_eventFrontRightSeatbelt m105 : 27|1@1+ (1,0) [0|1] ""  gtw
 SG_ RCM_a026_eventFrontRightSeatbelt m26 : 27|1@1+ (1,0) [0|1] ""  gtw
 SG_ RCM_a095_eventFrontRightSeatbelt m95 : 27|1@1+ (1,0) [0|1] ""  gtw
 SG_ RCM_a081_eventFrontRightSeatbelt m81 : 27|1@1+ (1,0) [0|1] ""  gtw
 SG_ RCM_a098_eventFrontRightSeatbelt m98 : 27|1@1+ (1,0) [0|1] ""  gtw
 SG_ RCM_a076_eventFrontRightSeatbelt m76 : 27|1@1+ (1,0) [0|1] ""  gtw
 SG_ RCM_a009_eventFrontRightSeatbelt m9 : 27|1@1+ (1,0) [0|1] ""  gtw
 SG_ RCM_a111_eventFrontRightSeatbelt m111 : 27|1@1+ (1,0) [0|1] ""  gtw
 SG_ RCM_a054_eventFrontRightSeatbelt m54 : 27|1@1+ (1,0) [0|1] ""  gtw
 SG_ RCM_a108_eventFrontRightSeatbelt m108 : 27|1@1+ (1,0) [0|1] ""  gtw
 SG_ RCM_a032_eventFrontRightSeatbelt m32 : 27|1@1+ (1,0) [0|1] ""  gtw
 SG_ RCM_a010_eventFrontRightSeatbelt m10 : 27|1@1+ (1,0) [0|1] ""  gtw
 SG_ RCM_a068_eventFrontRightSeatbelt m68 : 27|1@1+ (1,0) [0|1] ""  gtw
 SG_ RCM_a086_eventFrontRightSeatbelt m86 : 27|1@1+ (1,0) [0|1] ""  gtw
 SG_ RCM_a116_eventFrontRightSeatbelt m116 : 27|1@1+ (1,0) [0|1] ""  gtw
 SG_ RCM_a053_eventFrontRightSeatbelt m53 : 27|1@1+ (1,0) [0|1] ""  gtw
 SG_ RCM_a071_eventFrontRightSeatbelt m71 : 27|1@1+ (1,0) [0|1] ""  gtw
 SG_ RCM_a017_eventFrontRightSeatbelt m17 : 27|1@1+ (1,0) [0|1] ""  gtw
 SG_ RCM_a035_eventFrontRightSeatbelt m35 : 27|1@1+ (1,0) [0|1] ""  gtw
 SG_ RCM_a092_eventFrontRightSeatbelt m92 : 27|1@1+ (1,0) [0|1] ""  gtw
 SG_ RCM_a047_eventFrontRightSeatbelt m47 : 27|1@1+ (1,0) [0|1] ""  gtw
 SG_ RCM_a065_eventFrontRightSeatbelt m65 : 27|1@1+ (1,0) [0|1] ""  gtw
 SG_ RCM_a038_eventFrontRightSeatbelt m38 : 27|1@1+ (1,0) [0|1] ""  gtw
 SG_ RCM_a003_eventFrontRightSeatbelt m3 : 27|1@1+ (1,0) [0|1] ""  gtw
 SG_ RCM_a102_eventFrontRightSeatbelt m102 : 27|1@1+ (1,0) [0|1] ""  gtw
 SG_ RCM_a021_eventFrontRightSeatbelt m21 : 27|1@1+ (1,0) [0|1] ""  gtw
 SG_ RCM_a110_eventFrontRightSeatbelt m110 : 27|1@1+ (1,0) [0|1] ""  gtw
 SG_ RCM_a055_eventFrontRightSeatbelt m55 : 27|1@1+ (1,0) [0|1] ""  gtw
 SG_ RCM_a033_eventFrontRightSeatbelt m33 : 27|1@1+ (1,0) [0|1] ""  gtw
 SG_ RCM_a080_eventFrontRightSeatbelt m80 : 27|1@1+ (1,0) [0|1] ""  gtw
 SG_ RCM_a109_eventFrontRightSeatbelt m109 : 27|1@1+ (1,0) [0|1] ""  gtw
 SG_ RCM_a099_eventFrontRightSeatbelt m99 : 27|1@1+ (1,0) [0|1] ""  gtw
 SG_ RCM_a008_eventFrontRightSeatbelt m8 : 27|1@1+ (1,0) [0|1] ""  gtw
 SG_ RCM_a077_eventFrontRightSeatbelt m77 : 27|1@1+ (1,0) [0|1] ""  gtw
 SG_ RCM_a011_eventFrontRightSeatbelt m11 : 27|1@1+ (1,0) [0|1] ""  gtw
 SG_ RCM_a071_eventFrontLeftSeatbelt m71 : 26|1@1+ (1,0) [0|1] ""  gtw
 SG_ RCM_a053_eventFrontLeftSeatbelt m53 : 26|1@1+ (1,0) [0|1] ""  gtw
 SG_ RCM_a116_eventFrontLeftSeatbelt m116 : 26|1@1+ (1,0) [0|1] ""  gtw
 SG_ RCM_a086_eventFrontLeftSeatbelt m86 : 26|1@1+ (1,0) [0|1] ""  gtw
 SG_ RCM_a068_eventFrontLeftSeatbelt m68 : 26|1@1+ (1,0) [0|1] ""  gtw
 SG_ RCM_a035_eventFrontLeftSeatbelt m35 : 26|1@1+ (1,0) [0|1] ""  gtw
 SG_ RCM_a017_eventFrontLeftSeatbelt m17 : 26|1@1+ (1,0) [0|1] ""  gtw
 SG_ RCM_a010_eventFrontLeftSeatbelt m10 : 26|1@1+ (1,0) [0|1] ""  gtw
 SG_ RCM_a081_eventFrontLeftSeatbelt m81 : 26|1@1+ (1,0) [0|1] ""  gtw
 SG_ RCM_a108_eventFrontLeftSeatbelt m108 : 26|1@1+ (1,0) [0|1] ""  gtw
 SG_ RCM_a098_eventFrontLeftSeatbelt m98 : 26|1@1+ (1,0) [0|1] ""  gtw
 SG_ RCM_a076_eventFrontLeftSeatbelt m76 : 26|1@1+ (1,0) [0|1] ""  gtw
 SG_ RCM_a009_eventFrontLeftSeatbelt m9 : 26|1@1+ (1,0) [0|1] ""  gtw
 SG_ RCM_a111_eventFrontLeftSeatbelt m111 : 26|1@1+ (1,0) [0|1] ""  gtw
 SG_ RCM_a054_eventFrontLeftSeatbelt m54 : 26|1@1+ (1,0) [0|1] ""  gtw
 SG_ RCM_a032_eventFrontLeftSeatbelt m32 : 26|1@1+ (1,0) [0|1] ""  gtw
 SG_ RCM_a095_eventFrontLeftSeatbelt m95 : 26|1@1+ (1,0) [0|1] ""  gtw
 SG_ RCM_a026_eventFrontLeftSeatbelt m26 : 26|1@1+ (1,0) [0|1] ""  gtw
 SG_ RCM_a105_eventFrontLeftSeatbelt m105 : 26|1@1+ (1,0) [0|1] ""  gtw
 SG_ RCM_a004_eventFrontLeftSeatbelt m4 : 26|1@1+ (1,0) [0|1] ""  gtw
 SG_ RCM_a059_eventFrontLeftSeatbelt m59 : 26|1@1+ (1,0) [0|1] ""  gtw
 SG_ RCM_a062_eventFrontLeftSeatbelt m62 : 26|1@1+ (1,0) [0|1] ""  gtw
 SG_ RCM_a040_eventFrontLeftSeatbelt m40 : 26|1@1+ (1,0) [0|1] ""  gtw
 SG_ RCM_a096_eventFrontLeftSeatbelt m96 : 26|1@1+ (1,0) [0|1] ""  gtw
 SG_ RCM_a061_eventFrontLeftSeatbelt m61 : 26|1@1+ (1,0) [0|1] ""  gtw
 SG_ RCM_a043_eventFrontLeftSeatbelt m43 : 26|1@1+ (1,0) [0|1] ""  gtw
 SG_ RCM_a106_eventFrontLeftSeatbelt m106 : 26|1@1+ (1,0) [0|1] ""  gtw
 SG_ RCM_a025_eventFrontLeftSeatbelt m25 : 26|1@1+ (1,0) [0|1] ""  gtw
 SG_ RCM_a007_eventFrontLeftSeatbelt m7 : 26|1@1+ (1,0) [0|1] ""  gtw
 SG_ RCM_a078_eventFrontLeftSeatbelt m78 : 26|1@1+ (1,0) [0|1] ""  gtw
 SG_ RCM_a046_eventFrontLeftSeatbelt m46 : 26|1@1+ (1,0) [0|1] ""  gtw
 SG_ RCM_a002_eventFrontLeftSeatbelt m2 : 26|1@1+ (1,0) [0|1] ""  gtw
 SG_ RCM_a093_eventFrontLeftSeatbelt m93 : 26|1@1+ (1,0) [0|1] ""  gtw
 SG_ RCM_a064_eventFrontLeftSeatbelt m64 : 26|1@1+ (1,0) [0|1] ""  gtw
 SG_ RCM_a020_eventFrontLeftSeatbelt m20 : 26|1@1+ (1,0) [0|1] ""  gtw
 SG_ RCM_a103_eventFrontLeftSeatbelt m103 : 26|1@1+ (1,0) [0|1] ""  gtw
 SG_ RCM_a039_eventFrontLeftSeatbelt m39 : 26|1@1+ (1,0) [0|1] ""  gtw
 SG_ RCM_a036_eventFrontLeftSeatbelt m36 : 26|1@1+ (1,0) [0|1] ""  gtw
 SG_ RCM_a085_eventFrontLeftSeatbelt m85 : 26|1@1+ (1,0) [0|1] ""  gtw
 SG_ RCM_a049_eventFrontLeftSeatbelt m49 : 26|1@1+ (1,0) [0|1] ""  gtw
 SG_ RCM_a050_eventFrontLeftSeatbelt m50 : 26|1@1+ (1,0) [0|1] ""  gtw
 SG_ RCM_a115_eventFrontLeftSeatbelt m115 : 26|1@1+ (1,0) [0|1] ""  gtw
 SG_ RCM_a014_eventFrontLeftSeatbelt m14 : 26|1@1+ (1,0) [0|1] ""  gtw
 SG_ RCM_a072_eventFrontLeftSeatbelt m72 : 26|1@1+ (1,0) [0|1] ""  gtw
 SG_ RCM_a077_eventFrontLeftSeatbelt m77 : 26|1@1+ (1,0) [0|1] ""  gtw
 SG_ RCM_a008_eventFrontLeftSeatbelt m8 : 26|1@1+ (1,0) [0|1] ""  gtw
 SG_ RCM_a110_eventFrontLeftSeatbelt m110 : 26|1@1+ (1,0) [0|1] ""  gtw
 SG_ RCM_a055_eventFrontLeftSeatbelt m55 : 26|1@1+ (1,0) [0|1] ""  gtw
 SG_ RCM_a033_eventFrontLeftSeatbelt m33 : 26|1@1+ (1,0) [0|1] ""  gtw
 SG_ RCM_a011_eventFrontLeftSeatbelt m11 : 26|1@1+ (1,0) [0|1] ""  gtw
 SG_ RCM_a080_eventFrontLeftSeatbelt m80 : 26|1@1+ (1,0) [0|1] ""  gtw
 SG_ RCM_a109_eventFrontLeftSeatbelt m109 : 26|1@1+ (1,0) [0|1] ""  gtw
 SG_ RCM_a099_eventFrontLeftSeatbelt m99 : 26|1@1+ (1,0) [0|1] ""  gtw
 SG_ RCM_a030_eventFrontLeftSeatbelt m30 : 26|1@1+ (1,0) [0|1] ""  gtw
 SG_ RCM_a083_eventFrontLeftSeatbelt m83 : 26|1@1+ (1,0) [0|1] ""  gtw
 SG_ RCM_a056_eventFrontLeftSeatbelt m56 : 26|1@1+ (1,0) [0|1] ""  gtw
 SG_ RCM_a113_eventFrontLeftSeatbelt m113 : 26|1@1+ (1,0) [0|1] ""  gtw
 SG_ RCM_a012_eventFrontLeftSeatbelt m12 : 26|1@1+ (1,0) [0|1] ""  gtw
 SG_ RCM_a029_eventFrontLeftSeatbelt m29 : 26|1@1+ (1,0) [0|1] ""  gtw
 SG_ RCM_a074_eventFrontLeftSeatbelt m74 : 26|1@1+ (1,0) [0|1] ""  gtw
 SG_ RCM_a060_eventFrontLeftSeatbelt m60 : 26|1@1+ (1,0) [0|1] ""  gtw
 SG_ RCM_a024_eventFrontLeftSeatbelt m24 : 26|1@1+ (1,0) [0|1] ""  gtw
 SG_ RCM_a107_eventFrontLeftSeatbelt m107 : 26|1@1+ (1,0) [0|1] ""  gtw
 SG_ RCM_a042_eventFrontLeftSeatbelt m42 : 26|1@1+ (1,0) [0|1] ""  gtw
 SG_ RCM_a006_eventFrontLeftSeatbelt m6 : 26|1@1+ (1,0) [0|1] ""  gtw
 SG_ RCM_a079_eventFrontLeftSeatbelt m79 : 26|1@1+ (1,0) [0|1] ""  gtw
 SG_ RCM_a097_eventFrontLeftSeatbelt m97 : 26|1@1+ (1,0) [0|1] ""  gtw
 SG_ RCM_a018_eventFrontLeftSeatbelt m18 : 26|1@1+ (1,0) [0|1] ""  gtw
 SG_ RCM_a067_eventFrontLeftSeatbelt m67 : 26|1@1+ (1,0) [0|1] ""  gtw
 SG_ RCM_a045_eventFrontLeftSeatbelt m45 : 26|1@1+ (1,0) [0|1] ""  gtw
 SG_ RCM_a023_eventFrontLeftSeatbelt m23 : 26|1@1+ (1,0) [0|1] ""  gtw
 SG_ RCM_a100_eventFrontLeftSeatbelt m100 : 26|1@1+ (1,0) [0|1] ""  gtw
 SG_ RCM_a001_eventFrontLeftSeatbelt m1 : 26|1@1+ (1,0) [0|1] ""  gtw
 SG_ RCM_a090_eventFrontLeftSeatbelt m90 : 26|1@1+ (1,0) [0|1] ""  gtw
 SG_ RCM_a089_eventFrontLeftSeatbelt m89 : 26|1@1+ (1,0) [0|1] ""  gtw
 SG_ RCM_a037_eventFrontLeftSeatbelt m37 : 26|1@1+ (1,0) [0|1] ""  gtw
 SG_ RCM_a015_eventFrontLeftSeatbelt m15 : 26|1@1+ (1,0) [0|1] ""  gtw
 SG_ RCM_a084_eventFrontLeftSeatbelt m84 : 26|1@1+ (1,0) [0|1] ""  gtw
 SG_ RCM_a048_eventFrontLeftSeatbelt m48 : 26|1@1+ (1,0) [0|1] ""  gtw
 SG_ RCM_a073_eventFrontLeftSeatbelt m73 : 26|1@1+ (1,0) [0|1] ""  gtw
 SG_ RCM_a051_eventFrontLeftSeatbelt m51 : 26|1@1+ (1,0) [0|1] ""  gtw
 SG_ RCM_a114_eventFrontLeftSeatbelt m114 : 26|1@1+ (1,0) [0|1] ""  gtw
 SG_ RCM_a070_eventFrontLeftSeatbelt m70 : 26|1@1+ (1,0) [0|1] ""  gtw
 SG_ RCM_a052_eventFrontLeftSeatbelt m52 : 26|1@1+ (1,0) [0|1] ""  gtw
 SG_ RCM_a117_eventFrontLeftSeatbelt m117 : 26|1@1+ (1,0) [0|1] ""  gtw
 SG_ RCM_a034_eventFrontLeftSeatbelt m34 : 26|1@1+ (1,0) [0|1] ""  gtw
 SG_ RCM_a016_eventFrontLeftSeatbelt m16 : 26|1@1+ (1,0) [0|1] ""  gtw
 SG_ RCM_a087_eventFrontLeftSeatbelt m87 : 26|1@1+ (1,0) [0|1] ""  gtw
 SG_ RCM_a069_eventFrontLeftSeatbelt m69 : 26|1@1+ (1,0) [0|1] ""  gtw
 SG_ RCM_a031_eventFrontLeftSeatbelt m31 : 26|1@1+ (1,0) [0|1] ""  gtw
 SG_ RCM_a013_eventFrontLeftSeatbelt m13 : 26|1@1+ (1,0) [0|1] ""  gtw
 SG_ RCM_a028_eventFrontLeftSeatbelt m28 : 26|1@1+ (1,0) [0|1] ""  gtw
 SG_ RCM_a075_eventFrontLeftSeatbelt m75 : 26|1@1+ (1,0) [0|1] ""  gtw
 SG_ RCM_a057_eventFrontLeftSeatbelt m57 : 26|1@1+ (1,0) [0|1] ""  gtw
 SG_ RCM_a112_eventFrontLeftSeatbelt m112 : 26|1@1+ (1,0) [0|1] ""  gtw
 SG_ RCM_a082_eventFrontLeftSeatbelt m82 : 26|1@1+ (1,0) [0|1] ""  gtw
 SG_ RCM_a041_eventFrontLeftSeatbelt m41 : 26|1@1+ (1,0) [0|1] ""  gtw
 SG_ RCM_a005_eventFrontLeftSeatbelt m5 : 26|1@1+ (1,0) [0|1] ""  gtw
 SG_ RCM_a058_eventFrontLeftSeatbelt m58 : 26|1@1+ (1,0) [0|1] ""  gtw
 SG_ RCM_a094_eventFrontLeftSeatbelt m94 : 26|1@1+ (1,0) [0|1] ""  gtw
 SG_ RCM_a063_eventFrontLeftSeatbelt m63 : 26|1@1+ (1,0) [0|1] ""  gtw
 SG_ RCM_a027_eventFrontLeftSeatbelt m27 : 26|1@1+ (1,0) [0|1] ""  gtw
 SG_ RCM_a104_eventFrontLeftSeatbelt m104 : 26|1@1+ (1,0) [0|1] ""  gtw
 SG_ RCM_a088_eventFrontLeftSeatbelt m88 : 26|1@1+ (1,0) [0|1] ""  gtw
 SG_ RCM_a066_eventFrontLeftSeatbelt m66 : 26|1@1+ (1,0) [0|1] ""  gtw
 SG_ RCM_a044_eventFrontLeftSeatbelt m44 : 26|1@1+ (1,0) [0|1] ""  gtw
 SG_ RCM_a091_eventFrontLeftSeatbelt m91 : 26|1@1+ (1,0) [0|1] ""  gtw
 SG_ RCM_a019_eventFrontLeftSeatbelt m19 : 26|1@1+ (1,0) [0|1] ""  gtw
 SG_ RCM_a022_eventFrontLeftSeatbelt m22 : 26|1@1+ (1,0) [0|1] ""  gtw
 SG_ RCM_a101_eventFrontLeftSeatbelt m101 : 26|1@1+ (1,0) [0|1] ""  gtw
 SG_ RCM_a000_eventFrontLeftSeatbelt m0 : 26|1@1+ (1,0) [0|1] ""  gtw
 SG_ RCM_a118_eventFrontLeftSeatbelt m118 : 26|1@1+ (1,0) [0|1] ""  gtw
 SG_ RCM_a047_eventFrontLeftSeatbelt m47 : 26|1@1+ (1,0) [0|1] ""  gtw
 SG_ RCM_a003_eventFrontLeftSeatbelt m3 : 26|1@1+ (1,0) [0|1] ""  gtw
 SG_ RCM_a092_eventFrontLeftSeatbelt m92 : 26|1@1+ (1,0) [0|1] ""  gtw
 SG_ RCM_a065_eventFrontLeftSeatbelt m65 : 26|1@1+ (1,0) [0|1] ""  gtw
 SG_ RCM_a021_eventFrontLeftSeatbelt m21 : 26|1@1+ (1,0) [0|1] ""  gtw
 SG_ RCM_a102_eventFrontLeftSeatbelt m102 : 26|1@1+ (1,0) [0|1] ""  gtw
 SG_ RCM_a038_eventFrontLeftSeatbelt m38 : 26|1@1+ (1,0) [0|1] ""  gtw
 SG_ RCM_a072_eventIDFsignal m72 : 25|1@1+ (1,0) [0|1] ""  gtw
 SG_ RCM_a036_eventIDFsignal m36 : 25|1@1+ (1,0) [0|1] ""  gtw
 SG_ RCM_a085_eventIDFsignal m85 : 25|1@1+ (1,0) [0|1] ""  gtw
 SG_ RCM_a049_eventIDFsignal m49 : 25|1@1+ (1,0) [0|1] ""  gtw
 SG_ RCM_a050_eventIDFsignal m50 : 25|1@1+ (1,0) [0|1] ""  gtw
 SG_ RCM_a115_eventIDFsignal m115 : 25|1@1+ (1,0) [0|1] ""  gtw
 SG_ RCM_a014_eventIDFsignal m14 : 25|1@1+ (1,0) [0|1] ""  gtw
 SG_ RCM_a075_eventIDFsignal m75 : 25|1@1+ (1,0) [0|1] ""  gtw
 SG_ RCM_a013_eventIDFsignal m13 : 25|1@1+ (1,0) [0|1] ""  gtw
 SG_ RCM_a031_eventIDFsignal m31 : 25|1@1+ (1,0) [0|1] ""  gtw
 SG_ RCM_a082_eventIDFsignal m82 : 25|1@1+ (1,0) [0|1] ""  gtw
 SG_ RCM_a028_eventIDFsignal m28 : 25|1@1+ (1,0) [0|1] ""  gtw
 SG_ RCM_a057_eventIDFsignal m57 : 25|1@1+ (1,0) [0|1] ""  gtw
 SG_ RCM_a112_eventIDFsignal m112 : 25|1@1+ (1,0) [0|1] ""  gtw
 SG_ RCM_a061_eventIDFsignal m61 : 25|1@1+ (1,0) [0|1] ""  gtw
 SG_ RCM_a043_eventIDFsignal m43 : 25|1@1+ (1,0) [0|1] ""  gtw
 SG_ RCM_a078_eventIDFsignal m78 : 25|1@1+ (1,0) [0|1] ""  gtw
 SG_ RCM_a007_eventIDFsignal m7 : 25|1@1+ (1,0) [0|1] ""  gtw
 SG_ RCM_a096_eventIDFsignal m96 : 25|1@1+ (1,0) [0|1] ""  gtw
 SG_ RCM_a025_eventIDFsignal m25 : 25|1@1+ (1,0) [0|1] ""  gtw
 SG_ RCM_a106_eventIDFsignal m106 : 25|1@1+ (1,0) [0|1] ""  gtw
 SG_ RCM_a004_eventIDFsignal m4 : 25|1@1+ (1,0) [0|1] ""  gtw
 SG_ RCM_a059_eventIDFsignal m59 : 25|1@1+ (1,0) [0|1] ""  gtw
 SG_ RCM_a040_eventIDFsignal m40 : 25|1@1+ (1,0) [0|1] ""  gtw
 SG_ RCM_a062_eventIDFsignal m62 : 25|1@1+ (1,0) [0|1] ""  gtw
 SG_ RCM_a105_eventIDFsignal m105 : 25|1@1+ (1,0) [0|1] ""  gtw
 SG_ RCM_a026_eventIDFsignal m26 : 25|1@1+ (1,0) [0|1] ""  gtw
 SG_ RCM_a095_eventIDFsignal m95 : 25|1@1+ (1,0) [0|1] ""  gtw
 SG_ RCM_a018_eventIDFsignal m18 : 25|1@1+ (1,0) [0|1] ""  gtw
 SG_ RCM_a045_eventIDFsignal m45 : 25|1@1+ (1,0) [0|1] ""  gtw
 SG_ RCM_a067_eventIDFsignal m67 : 25|1@1+ (1,0) [0|1] ""  gtw
 SG_ RCM_alertID M : 0|10@1+ (1,0) [0|118] ""  gtw

BA_DEF_ SG_  "SystemSignalLongSymbol" STRING ;
BA_DEF_DEF_  "SystemSignalLongSymbol" "";
BA_ "SystemSignalLongSymbol" SG_ 1805 DBG_pcs_DCDC_slowDischargeSlewRa "DBG_pcs_DCDC_slowDischargeSlewRate";
BA_ "SystemSignalLongSymbol" SG_ 1805 DBG_pcs_DCDC_slowDischargeTarget "DBG_pcs_DCDC_slowDischargeTargetVoltage";
BA_ "SystemSignalLongSymbol" SG_ 1365 RADC_a055_bblock_ucTimeoutBlkPro "RADC_a055_bblock_ucTimeoutBlkProb";
VAL_ 568 UI_nextBranchDist 31 "SNA" ;
VAL_ 568 UI_countryCode 1023 "SNA" 0 "UNKNOWN" ;
VAL_ 568 UI_mapSpeedLimitType 2 "ADVISORY" 7 "UNKNOWN_SNA" 4 "BUMPS" 3 "DEPENDENT" 1 "REGULAR" ;
VAL_ 568 UI_mapSpeedLimit 25 "LESS_OR_EQ_120" 31 "SNA" 7 "LESS_OR_EQ_30" 23 "LESS_OR_EQ_110" 30 "UNLIMITED" 1 "LESS_OR_EQ_5" 18 "LESS_OR_EQ_85" 27 "LESS_OR_EQ_140" 11 "LESS_OR_EQ_50" 16 "LESS_OR_EQ_75" 0 "UNKNOWN" 6 "LESS_OR_EQ_25" 22 "LESS_OR_EQ_105" 4 "LESS_OR_EQ_15" 21 "LESS_OR_EQ_100" 3 "LESS_OR_EQ_10" 13 "LESS_OR_EQ_60" 14 "LESS_OR_EQ_65" 12 "LESS_OR_EQ_55" 17 "LESS_OR_EQ_80" 24 "LESS_OR_EQ_115" 26 "LESS_OR_EQ_130" 5 "LESS_OR_EQ_20" 2 "LESS_OR_EQ_7" 29 "LESS_OR_EQ_160" 15 "LESS_OR_EQ_70" 20 "LESS_OR_EQ_95" 28 "LESS_OR_EQ_150" 9 "LESS_OR_EQ_40" 10 "LESS_OR_EQ_45" 19 "LESS_OR_EQ_90" 8 "LESS_OR_EQ_35" ;
VAL_ 568 UI_mapSpeedUnits 0 "MPH" 1 "KPH" ;
VAL_ 568 UI_roadClass 1 "CLASS_1_MAJOR" 6 "CLASS_6_MINOR" 0 "UNKNOWN_INVALID_SNA" 5 "CLASS_5" 3 "CLASS_3" 4 "CLASS_4" 2 "CLASS_2" ;
VAL_ 568 UI_mapSpeedLimitDependency 2 "RAIN" 7 "SNA" 0 "NONE" 5 "SEASON" 4 "TIME" 1 "SCHOOL" 3 "SNOW" 6 "LANE" ;
VAL_ 945 DAS_TF_multiplexer 2 "Mux2" 0 "Mux0" 1 "Mux1" ;
VAL_ 881 RCM_matrixIndex 1 "RCM_AlertMatrix1" 0 "RCM_AlertMatrix0" ;
VAL_ 82 EPAS3P_eacStatus 7 "SNA" 2 "EAC_ACTIVE" 4 "LANE_KEEP_ASSIST" 3 "EAC_FAULT" 1 "EAC_AVAILABLE" 5 "EMERGENCY_LANE_KEEP" 0 "EAC_INHIBITED" ;
VAL_ 82 EPAS3P_handsOnLevel 1 "LEVEL_1" 0 "LEVEL_0" 3 "LEVEL_3" 2 "LEVEL_2" ;
VAL_ 82 EPAS3P_torsionBarTorque 4095 "SNA" 4094 "UNDEFINABLE_DATA" ;
VAL_ 82 EPAS3P_eacErrorCode 15 "SNA" 11 "EAC_ERROR_HIGH_TORSION_SAFETY" 4 "EAC_ERROR_TMP_FAULT" 2 "EAC_ERROR_MAX_SPEED" 7 "EAC_ERROR_HIGH_ANGLE_RATE_REQ" 0 "EAC_ERROR_IDLE" 10 "EAC_ERROR_HIGH_MMOT_SAFETY" 6 "EAC_ERROR_HIGH_ANGLE_REQ" 8 "EAC_ERROR_HIGH_ANGLE_SAFETY" 5 "EAR_ERROR_MAX_STEER_DELTA" 13 "EAC_ERROR_PINION_VEL_DIFF" 1 "EAC_ERROR_MIN_SPEED" 14 "EAC_EXTERNAL_MONITOR_INHIBIT" 12 "EAC_ERROR_LOW_ASSIST" 9 "EAC_ERROR_HIGH_ANGLE_RATE_SAFETY" 3 "EAC_ERROR_HANDS_ON" ;
VAL_ 82 EPAS3P_steeringRackForce 1023 "SNA" 1022 "NOT_IN_SPEC" ;
VAL_ 82 EPAS3P_steeringFault 0 "NO_FAULT" 1 "FAULT" ;
VAL_ 82 EPAS3P_steeringReduced 0 "NORMAL_ASSIST" 1 "REDUCED_ASSIST" ;
VAL_ 82 EPAS3P_internalSASQF 1 "IN_SPEC" 0 "UNDEFINABLE_ACCURACY" ;
VAL_ 82 EPAS3P_currentTuneMode 3 "STEERING_TUNE_RWD_COMFORT" 1 "STEERING_TUNE_DM_STANDARD" 5 "STEERING_TUNE_RWD_SPORT" 0 "STEERING_TUNE_DM_COMFORT" 4 "STEERING_TUNE_RWD_STANDARD" 2 "STEERING_TUNE_DM_SPORT" ;
VAL_ 373 ESP_wheelSpeedReR 8191 "SNA" ;
VAL_ 373 ESP_wheelSpeedReL 8191 "SNA" ;
VAL_ 373 ESP_wheelSpeedFrR 8191 "SNA" ;
VAL_ 373 ESP_wheelSpeedFrL 8191 "SNA" ;
VAL_ 744 EPBR_brakeDiscWipeRequest 1 "EPB_BRAKEDISCWIPE_REQUEST_LIGHT" 3 "EPB_BRAKEDISCWIPE_REQUEST_SNA" 0 "EPB_BRAKEDISCWIPE_REQUEST_NONE" 2 "EPB_BRAKEDISCWIPE_REQUEST_STRONG" ;
VAL_ 744 EPBR_cdpRequest 0 "EPB_CDP_NOT_REQUESTED" 1 "EPB_CDP_REQUESTED" ;
VAL_ 744 EPBR_telltale 0 "EPB_TELLTALE_LAMP_OFF" 2 "EPB_TELLTALE_LAMP_AMBER_ON" 3 "EPB_TELLTALE_LAMP_RED_FLASH" 1 "EPB_TELLTALE_LAMP_RED_ON" 7 "EPB_TELLTALE_SNA" ;
VAL_ 744 EPBR_systemStatus 0 "EPB_VEHICLE_STATUS_UNKNOWN" 2 "EPB_VEHICLE_STATUS_PARKED" 6 "EPB_VEHICLE_STATUS_FAULT" 3 "EPB_VEHICLE_STATUS_DYNAMIC" 1 "EPB_VEHICLE_STATUS_RELEASED" 4 "EPB_VEHICLE_STATUS_PARKING" 5 "EPB_VEHICLE_STATUS_RELEASING" 8 "EPB_VEHICLE_STATUS_MISMATCH" 7 "EPB_VEHICLE_STATUS_FAULT_SECURE" ;
VAL_ 894 PARK_matrixIndex 0 "PARK_AlertMatrix0" 1 "PARK_AlertMatrix1" ;
VAL_ 606 PARK_pscLeftParallelObj2Alpha 127 "SNA" 126 "NO_SPACE" ;
VAL_ 606 PARK_pscRightParallelObj2Alpha 127 "SNA" 126 "NO_SPACE" ;
VAL_ 606 PARK_pscLeftCrossObj2Alpha 127 "SNA" 126 "NO_SPACE" ;
VAL_ 606 PARK_pscRightCrossObj2Alpha 127 "SNA" 126 "NO_SPACE" ;
VAL_ 606 PARK_pscRightParallelObj2X 2047 "SNA" 2046 "NO_SPACE" ;
VAL_ 606 PARK_pscLeftParallelObj2X 2047 "SNA" 2046 "NO_SPACE" ;
VAL_ 606 PARK_pscLeftCrossObj2X 2047 "SNA" 2046 "NO_SPACE" ;
VAL_ 606 PARK_pscRightCrossObj2X 2047 "SNA" 2046 "NO_SPACE" ;
VAL_ 606 PARK_pscLeftCrossObj2Y 2047 "SNA" 2046 "NO_SPACE" ;
VAL_ 606 PARK_pscRightParallelObj2Y 2047 "SNA" 2046 "NO_SPACE" ;
VAL_ 606 PARK_pscLeftParallelObj2Y 2047 "SNA" 2046 "NO_SPACE" ;
VAL_ 606 PARK_pscRightCrossObj2Y 2047 "SNA" 2046 "NO_SPACE" ;
VAL_ 606 PARK_pscRightParallelObj1Alpha 127 "SNA" 126 "NO_SPACE" ;
VAL_ 606 PARK_pscRightCrossObj1Alpha 127 "SNA" 126 "NO_SPACE" ;
VAL_ 606 PARK_pscLeftCrossObj1Alpha 127 "SNA" 126 "NO_SPACE" ;
VAL_ 606 PARK_pscLeftParallelObj1Alpha 127 "SNA" 126 "NO_SPACE" ;
VAL_ 606 PARK_pscRightCrossObj1Y 2047 "SNA" 2046 "NO_SPACE" ;
VAL_ 606 PARK_pscRightParallelObj1Y 2047 "SNA" 2046 "NO_SPACE" ;
VAL_ 606 PARK_pscLeftParallelObj1Y 2047 "SNA" 2046 "NO_SPACE" ;
VAL_ 606 PARK_pscLeftCrossObj1Y 2047 "SNA" 2046 "NO_SPACE" ;
VAL_ 606 PARK_pscRightParallelObj1X 2047 "SNA" 2046 "NO_SPACE" ;
VAL_ 606 PARK_pscLeftParallelObj1X 2047 "SNA" 2046 "NO_SPACE" ;
VAL_ 606 PARK_pscRightCrossObj1X 2047 "SNA" 2046 "NO_SPACE" ;
VAL_ 606 PARK_pscLeftCrossObj1X 2047 "SNA" 2046 "NO_SPACE" ;
VAL_ 606 PARK_pscEnvSlotType 1 "LEFT_CROSS" 2 "RIGHT_PARALLEL" 0 "LEFT_PARALLEL" 3 "RIGHT_CROSS" ;
VAL_ 1805 DBG_DCDC_fastCANDebugEn 0 "DBG_PCS_DCDC_FAST_CAN_NONE" 3 "DBG_PCS_DCDC_FAST_CAN_SENSE_AND_STATUS" 1 "DBG_PCS_DCDC_FAST_CAN_SENSE" 2 "DBG_PCS_DCDC_FAST_CAN_STATUS" ;
VAL_ 1805 DBG_pcs_chgDebugAuthentication 60 "DBG_PCS_SYS_OVR_ENABLE" 0 "DBG_PCS_SYS_OVR_NONE" ;
VAL_ 1805 DBG_pcs_PH_daccSelect 8 "DBG_PCS_PH_DAC_SELECT_LLC_CONTROL_VAL" 0 "DBG_PCS_PH_DAC_SELECT_NONE" 2 "DBG_PCS_PH_DAC_SELECT_INDUCTOR_I" 6 "DBG_PCS_PH_DAC_SELECT_PFC_BUS_COMMAND" 4 "DBG_PCS_PH_DAC_SELECT_PFC_DUTY" 10 "DBG_PCS_PH_DAC_SELECT_LINE_V" 9 "DBG_PCS_PH_DAC_SELECT_PFC_PLL" 7 "DBG_PCS_PH_DAC_SELECT_LLC_ENABLE" 1 "DBG_PCS_PH_DAC_SELECT_TOTAL_IREF" 3 "DBG_PCS_PH_DAC_SELECT_CAP_V_EST" 5 "DBG_PCS_PH_DAC_SELECT_PFC_BUS_ERROR" ;
VAL_ 1805 DBG_pcs_dcdcLvGtDrvEnable 1 "DBG_PCS_IO_LEVEL_HI" 0 "DBG_PCS_IO_LEVEL_LO" ;
VAL_ 1805 DBG_DCDC_subStateFaultType 0 "DCDC_CLA_SUBSTATE_FAULT" 1 "DCDC_UNSAFE_DI_VOLTAGE_SUBSTATE_FAULT" 2 "DCDC_LV_OVERVOLTAGE_SUBSTATE_FAULT" 3 "DCDC_SUBSTATE_FAULT_TYPE_MAX" ;
VAL_ 1805 DBG_pcs_PH_dacaSelect 8 "DBG_PCS_PH_DAC_SELECT_LLC_CONTROL_VAL" 0 "DBG_PCS_PH_DAC_SELECT_NONE" 2 "DBG_PCS_PH_DAC_SELECT_INDUCTOR_I" 6 "DBG_PCS_PH_DAC_SELECT_PFC_BUS_COMMAND" 4 "DBG_PCS_PH_DAC_SELECT_PFC_DUTY" 10 "DBG_PCS_PH_DAC_SELECT_LINE_V" 9 "DBG_PCS_PH_DAC_SELECT_PFC_PLL" 7 "DBG_PCS_PH_DAC_SELECT_LLC_ENABLE" 1 "DBG_PCS_PH_DAC_SELECT_TOTAL_IREF" 3 "DBG_PCS_PH_DAC_SELECT_CAP_V_EST" 5 "DBG_PCS_PH_DAC_SELECT_PFC_BUS_ERROR" ;
VAL_ 1805 DBG_pcs_5VL1Enable 1 "DBG_PCS_IO_LEVEL_HI" 0 "DBG_PCS_IO_LEVEL_LO" ;
VAL_ 1805 DBG_pcs_analogMuxInhibitInv 1 "DBG_PCS_IO_LEVEL_HI" 0 "DBG_PCS_IO_LEVEL_LO" ;
VAL_ 1805 DBG_pcs_chgGridConfigToOvr 3 "PHASE_CONFIG_THREE_PHASE_DELTA" 1 "PHASE_CONFIG_SINGLE_PHASE" 4 "PHASE_CONFIG_SINGLE_PHASE_IEC_GB" 5 "PHASE_CONFIG_MFG_TEST_CONFIG_1" 2 "PHASE_CONFIG_THREE_PHASE" 0 "PHASE_CONFIG_SNA" 7 "PHASE_CONFIG_RELIABILITY_SINGLE_PHASE" 6 "PHASE_CONFIG_MFG_TEST_CONFIG_2" 8 "PHASE_CONFIG_TOTAL_NUM" ;
VAL_ 1805 DBG_pcs_analogMuxSelC 1 "DBG_PCS_IO_LEVEL_HI" 0 "DBG_PCS_IO_LEVEL_LO" ;
VAL_ 1805 DBG_pcs_phCLogicPwrEnable 1 "DBG_PCS_IO_LEVEL_HI" 0 "DBG_PCS_IO_LEVEL_LO" ;
VAL_ 1805 DBG_pcs_analogMuxSelB 1 "DBG_PCS_IO_LEVEL_HI" 0 "DBG_PCS_IO_LEVEL_LO" ;
VAL_ 1805 DBG_pcs_PH_daccPhaseSelect 1 "PHB" 2 "PHC" 3 "PH_NUM" 0 "PHA" ;
VAL_ 1805 DBG_pcs_phBLogicPwrEnable 1 "DBG_PCS_IO_LEVEL_HI" 0 "DBG_PCS_IO_LEVEL_LO" ;
VAL_ 1805 DBG_pcs_phALogicPwrEnable 1 "DBG_PCS_IO_LEVEL_HI" 0 "DBG_PCS_IO_LEVEL_LO" ;
VAL_ 1805 DBG_pcs_envOverrideValue 5 "PCS_NUM_ENVIRONMENTS" 3 "ENV_DC_CIRCULATION_ALLOW" 1 "ENV_MFG_EOL" 0 "ENV_VEHICLE" 4 "ENV_HIL_TESTER" 2 "ENV_MFG_BOARD_BRINGUP" ;
VAL_ 1805 DBG_pcs_analogMuxSelA 1 "DBG_PCS_IO_LEVEL_HI" 0 "DBG_PCS_IO_LEVEL_LO" ;
VAL_ 1805 DBG_pcs_DCDC_dcdcMode 1 "SUPPORT" 0 "SHUTDOWN" 3 "DISCHARGE" 2 "PRECHARGE" ;
VAL_ 1805 DBG_DCDC_subStateFaultTarget 13 "DCDC_SUBSTATE_DIS_HVBUS_FAULTED" 4 "DCDC_SUBSTATE_PCHG_FAST_DIS_HVBUS" 15 "DCDC_SUBSTATE_CLEAR_FAULTS" 7 "DCDC_SUBSTATE_PCHG_DWELL_WAIT" 12 "DCDC_SUBSTATE_12V_SUPPORT_FAULTED" 8 "DCDC_SUBSTATE_PCHG_DI_RECOVERY_WAIT" 17 "DCDC_SUBSTATE_NUM" 10 "DCDC_SUBSTATE_PCHG_FLT_FAST_DIS_HVBUS" 2 "DCDC_SUBSTATE_12V_SUPPORT_ACTIVE" 3 "DCDC_SUBSTATE_DIS_HVBUS" 14 "DCDC_SUBSTATE_PCHG_FAULTED" 11 "DCDC_SUBSTATE_SHUTDOWN" 1 "DCDC_SUBSTATE_STANDBY" 9 "DCDC_SUBSTATE_PCHG_ACTIVE" 16 "DCDC_SUBSTATE_FAULTED" 6 "DCDC_SUBSTATE_PCHG_DWELL_CHARGE" 5 "DCDC_SUBSTATE_PCHG_SLOW_DIS_HVBUS" 0 "DCDC_SUBSTATE_PWR_UP_INIT" ;
VAL_ 1805 DBG_pcs_PH_dacaPhaseSelect 1 "PHB" 2 "PHC" 3 "PH_NUM" 0 "PHA" ;
VAL_ 1805 DBG_pcsControlSel 35 "DBG_PCS_CHG_SYSTEM_OVERRIDE" 150 "DBG_PCS_ANALOG_MUX_CONTROL" 114 "DBG_PCS_DCDC_SLOW_DISCHARGE_CTRL" 103 "DCDC_RECTIFY_PARAMETERS" 106 "DCDC_DEBUG_FLOAT_PARAMETERS" 24 "DBG_PCS_PHB_LLC_CONTROL" 6 "DBG_PCS_PH_CONTROL_PARAMS" 37 "DBG_PCS_PHB_SYSTEM_OVERRIDE" 101 "DCDC_COMPARATOR" 104 "DCDC_SNUBBER_PARAMETERS" 33 "DBG_PCS_PHC_PFC_CONTROL" 38 "DBG_PCS_PHC_SYSTEM_OVERRIDE" 102 "DCDC_DRIVE_PARAMETERS" 23 "DBG_PCS_PHB_PFC_CONTROL" 100 "DBG_PCS_DCDC_CONTROL" 113 "DBG_PCS_DCDC_HIL_TEST_OVERRIDE" 14 "DBG_PCS_PHA_LLC_CONTROL" 108 "DCDC_VTANK_CONTROL_PARAMETERS" 32 "DBG_PCS_PHC_CLOSED_LOOP_CONTROL" 5 "DBG_PCS_PH_ALL" 39 "DBG_PCS_ENVIRONMENT_OVERRIDE" 107 "DCDC_DEBUG_INT_PARAMETERS" 13 "DBG_PCS_PHA_PFC_CONTROL" 22 "DBG_PCS_PHB_CLOSED_LOOP_CONTROL" 111 "DBG_PCS_DCDC_SYSTEM_CMD_OVERRIDE" 110 "DBG_PCS_DCDC_SYS_TEST_OVERRIDE" 109 "DCDC_CPU_VREG_CONTROL" 112 "DBG_PCS_DCDC_SUBSTATE_FAULT" 7 "DBG_PCS_PH_CONTROL_PARAMS2" 9 "DBG_PCS_PH_INT_BUS_CONTROL" 105 "DCDC_VLOOP_CONTROL_PARAMETERS_1" 34 "DBG_PCS_PHC_LLC_CONTROL" 12 "DBG_PCS_PHA_CLOSED_LOOP_CONTROL" 8 "DBG_PCS_PH_DC_CIRCULATION_CONTROL" 36 "DBG_PCS_PHA_SYSTEM_OVERRIDE" ;
VAL_ 1365 RADC_a029_rhcFdcErrType 1 "RHC_FDC_RMSE_TOO_LARGE_NS" 0 "RHC_FDC_DRIFT_FREQ_TOO_LARGE_NS" 2 "RHC_FDC_LONG_TERM_ERROR_NS" ;
VAL_ 1365 RADC_a029_rhcSp1ErrType 0 "RHC_CTE_LUT_DUR_STUCK_ERR" ;
VAL_ 1365 RADC_a029_rhcVcoPowerErrType 0 "RHC_VCO_POWER_TOO_HIGH" 1 "RHC_VCO_POWER_TOO_LOW" ;
VAL_ 1365 RADC_a029_rhcRxErrType 5 "RHC_RX_NOISE_POWER_TOO_HIGH" 1 "RHC_RX_STC_FILTER_ERR" 7 "RHC_RX_SPURIOUS_PEAKS_TOO_HIGH" 2 "RHC_RX_CHANNEL_VARIATION_ERR" 3 "RHC_RX_TRANSFER_FUNCTION_ERR" 6 "RHC_LOAD_PULLING_TOO_HIGH_NS" 4 "RHC_RX_SIGNAL_POWER_TOO_LOW" 0 "RHC_RX_NONLINEAR_ERR" ;
VAL_ 1365 RADC_a032_block_SPMSelfTestState 0 "GDB_PD_OFF" 1 "GDB_PD_ON" 3 "GDB_PD_ROADBEAM_TEST" 2 "GDB_PD_STARTUP" ;
VAL_ 1365 RADC_a019_internalSWFaultCoreID 1 "INTERNAL_SOFTWARE_FAULT_CORE_1" 0 "INTERNAL_SOFTWARE_FAULT_CORE_0" 2 "INTERNAL_SOFTWARE_FAULT_CORE_2" ;
VAL_ 1365 RADC_a047_chassisTypeRx 7 "SNA" 2 "MODEL_3_CHASSIS" 0 "MODEL_S_CHASSIS" 1 "MODEL_X_CHASSIS" ;
VAL_ 1365 RADC_a051_epasTypeRx 7 "SNA" 3 "MANDO_VGR66" 4 "MANDO_VGR63_GEN3" 2 "MANDO_FGR64" 1 "BOSCH_L405" 0 "BOSCH_L538" ;
VAL_ 1365 RADC_a032_block_SPMBlockageState 0 "DB_NO_DAMP" 1 "GDB_INC_DAMP" 3 "GDB_RDC_DAMP" 2 "GDB_FULL_DAMP" 4 "GDB_UNKNOWN_DAMP" ;
VAL_ 1365 RADC_a049_fourWheelDriveRx 3 "SNA" 2 "UNUSED" 1 "4WD" 0 "2WD" ;
VAL_ 1365 RADC_a052_radarPositionRx 7 "SNA" 3 "MODEL_3" 1 "MODELS_2" 0 "MODELS" 2 "MODELX" ;
VAL_ 1365 RADC_a048_airSuspensionRx 7 "SNA" 0 "NONE" 5 "TESLA_ADAPTIVE" 1 "STANDARD" 3 "TESLA_STANDARD" 2 "PLUS" 4 "TESLA_PLUS" ;
VAL_ 1365 RADC_a029_rhcRxLongTermErrType 0 "RHC_RX_NONLINEAR_ERR_LT" 4 "RHC_RX_SIGNAL_POWER_TOO_LOW_LT" 1 "RHC_RX_STC_FILTER_ERR_LT" 3 "RHC_RX_TRANSFER_FUNCTION_ERR_LT" 6 "RHC_RX_NOISE_POWER_TOO_HIGH_LT" 2 "RHC_RX_CHANNEL_VARIATION_ERR_LT" 5 "RHC_RX_SPURIOUS_PEAKS_TOO_HIGH_LT" ;
VAL_ 1365 RADC_a029_rhcChirpMonErrType 0 "RHC_CHIRP_MON_FREQ_ERROR_SPEC_TOO_LARGE_NS" 1 "RHC_CHIRP_MON_RMSE_TOO_LARGE_NS" 2 "RHC_CHIRP_MON_RG_LENGTH_ERROR_NS" ;
VAL_ 1365 RADC_a032_blockageType 4 "FCTSEN_OBJ_NOT_MEASURED" 2 "FCTSEN_DEC_BLOCKAGE" 0 "ALN_PATH_COMP_HIGH_NEAR" 3 "FCTSEN_BLOCKAGE" 1 "FCTSEN_INC_BLOCKAGE" ;
VAL_ 1365 RADC_a047_chassisTypeExp 7 "SNA" 2 "MODEL_3_CHASSIS" 0 "MODEL_S_CHASSIS" 1 "MODEL_X_CHASSIS" ;
VAL_ 1365 RADC_a051_epasTypeExp 7 "SNA" 3 "MANDO_VGR66" 4 "MANDO_VGR63_GEN3" 2 "MANDO_FGR64" 1 "BOSCH_L405" 0 "BOSCH_L538" ;
VAL_ 1365 RADC_a046_wheelSpeedsErrType 1 "LENGTH" 0 "NONE" 2 "CHECKSUM" 3 "SEQUENCE" 5 "OVERRUN" 4 "INVALID_DATA" ;
VAL_ 1365 RADC_a052_radarPositionExp 7 "SNA" 3 "MODEL_3" 1 "MODELS_2" 0 "MODELS" 2 "MODELX" ;
VAL_ 1365 RADC_a030_rspErrType 0 "RSP_SPT_SHORT_TERM_ERROR" 1 "RSP_SPT_LONG_TERM_ERROR" ;
VAL_ 1365 RADC_a008_interLockErrType 1 "SW_VERSION_MISMATCH" 0 "HW_SW_PROJECT_ID_INCOMPATIBLE" ;
VAL_ 1365 RADC_a034_vehDynamicsErrorType 7 "VDY_INPUT_SIG_ERROR" 3 "VDY_FS_VEH_CORR_MON" 4 "VDY_INPUT_PARAM_ERROR" 2 "VDY_EXT_VELO_IMPLAUSIBLE" 1 "OUTPUT_YAW_NOT_AVAILABLE" 6 "VDY_INPUT_SIG_PEAK_ERROR" 5 "VDY_LEARND_SWA_OFFSET_OUT_OF_RANGE" 0 "OUTPUT_VELOCITY_NOT_AVAILABLE" ;
VAL_ 1365 RADC_a049_fourWheelDriveExp 3 "SNA" 2 "UNUSED" 1 "4WD" 0 "2WD" ;
VAL_ 1365 RADC_a042_carConfigErrType 1 "LENGTH" 0 "NONE" 2 "CHECKSUM" 3 "SEQUENCE" 5 "OVERRUN" 4 "INVALID_DATA" ;
VAL_ 1365 RADC_a044_stwAngleErrType 1 "LENGTH" 0 "NONE" 2 "CHECKSUM" 3 "SEQUENCE" 5 "OVERRUN" 4 "INVALID_DATA" ;
VAL_ 1365 RADC_a045_vehicleStateErrType 1 "LENGTH" 0 "NONE" 2 "CHECKSUM" 3 "SEQUENCE" 5 "OVERRUN" 4 "INVALID_DATA" ;
VAL_ 1365 RADC_a028_rfComRegCheckFail 2 "RFCOM_REG_CHECK_FAILED_LT" 1 "RFCOM_REG_CHECK_FAILED" 4 "RFCOM_MON_RF_OVERTEMP" 0 "RFCOM_REG_CHECK_CYCLE_FAILED" 3 "RFCOM_MON_RF_CHIP_TEMP_IMPLAUSIBLE" ;
VAL_ 1365 RADC_a048_airSuspensionExp 7 "SNA" 0 "NONE" 5 "TESLA_ADAPTIVE" 1 "STANDARD" 3 "TESLA_STANDARD" 2 "PLUS" 4 "TESLA_PLUS" ;
VAL_ 1365 RADC_a016_adcOverVoltType 7 "ADC_5V_SMPS_OVER_VOLTAGE" 0 "ADC_1V25_SMPS_OVER_VOLTAGE" 6 "ADC_4V5_LIN_VOLTAGECO_OVER_VOLTAGE" 3 "ADC_3V3_LIN_DIGITAL_OVER_VOLTAGE" 5 "ADC_3V8_SMPS_OVER_VOLTAGE" 4 "ADC_3V3_LIN_ANALOG_OVER_VOLTAGE" 1 "ADC_3V3_LIN_VOLTAGECO_OVER_VOLTAGE" 2 "ADC_3V3_LIN_PA_OVER_VOLTAGE" ;
VAL_ 1365 RADC_a027_nvmFailureType 0 "NVM_RECORD_SIZE_MISSMATCH" 1 "NVM_REQ_FAILED" 2 "NVM_INTEGRITY_FAILED" ;
VAL_ 1365 RADC_a011_ecuMcemErrType 2 "MCU_E_MCPCU_PERIODIC_CHECK" 9 "MCEM_E_CORRUPTED_HW_CONFIG" 10 "MCEM__ALARM_ISR" 0 "MCU_E_QUARTZ_FAILURE" 8 "MCEM_E_FAULT" 7 "MCEM_E_FORBIDDEN_INVOCATION" 5 "MCEM_E_OPERATION_FAILED" 6 "MCEM_E_INIT_FAILED" 3 "MCU_E_MCME_PERIODIC_CHECK" 4 "MCU_E_CLOCK_FAILURE" 1 "MCU_E_MCRGM_PERIODIC_CHECK" ;
VAL_ 1365 RADC_a013_ecuWdgErrType 2 "WATCHDOG_DISABLE_REJECTED" 3 "WATCHDOG_CORRUPT_CONFIG" 0 "WATCHDOG_UNLOCKED" 1 "WATCHDOG_INVALID_CALL" ;
VAL_ 1365 RADC_a043_inertialSignalsErrType 1 "LENGTH" 0 "NONE" 2 "CHECKSUM" 3 "SEQUENCE" 5 "OVERRUN" 4 "INVALID_DATA" ;
VAL_ 1365 RADC_a002_ecuAdcErrType 1 "ADC_E_INVALID_CONV_MODE" 0 "ADC_E_LIMIT_RANGE" ;
VAL_ 1365 RADC_a019_internalSWFaultType 102 "FS_RESET_TEMP_CROSS_CHECK" 20 "FS_RESET_EXCEPT_EFP_DATA" 101 "FS_RESET_ECC_INIT_FAILED" 12 "FS_RESET_EXCEPT_PROGRAM" 83 "FS_RESET_ECC_OTHER_2BIT" 13 "FS_RESET_EXCEPT_PERFORMANCEMON" 85 "FS_RESET_SPI_MMIC_MISMATCH" 69 "FS_RESET_CLKMON_CONFIG_CHECK" 45 "FS_RESET_TESTCASE_ABORT" 41 "FS_RESET_UNEXPECTED_RESET" 92 "FS_RESET_EXCEPT_TRAP" 1 "FS_RESET_TEMP_MON" 32 "FS_RESET_SRAM_ADDRESS_BUS0" 29 "FS_RESET_AD_CONVERTER" 25 "FS_RESET_EXCEPT_UNDEFINED" 23 "FS_RESET_EXCEPT_ERROR_SRAM" 74 "FS_RESET_IOHWAB" 63 "FS_RESET_FPU_CHECK" 84 "FS_RESET_SPI_MMIC_FAULT" 0 "FS_RESET_NONE" 103 "FS_RESET_STARTUP_ERROR" 104 "FS_RESET_MBIST_FAILED" 39 "FS_RESET_MISC_CHECK" 37 "FS_RESET_CONFIG_REGISTER_CHECK" 11 "FS_RESET_EXCEPT_ALIGN" 3 "FS_RESET_RAM_ECC_1BIT" 100 "FS_RESET_RADAR_CYCLE_VIOLATION" 106 "FS_RESET_ATIC_RESET" 42 "FS_RESET_BUS_TEST" 16 "FS_RESET_EXCEPT_WATCHDOG_TIMER" 7 "FS_RESET_EXCEPT_CRIT_INPUT" 61 "FS_RESET_ECC_DMA_2BIT" 9 "FS_RESET_EXCEPT_DATA_STORE" 78 "FS_RESET_ECC_EEPROM_2BIT" 53 "FS_RESET_EXCEPT_DECREMENTER" 99 "FS_RESET_FLSP_INIT_FAILED" 55 "FS_RESET_EXCEPT_ECC2BITERROR" 87 "FS_RESET_ECUM_REQUEST" 18 "FS_RESET_EXCEPT_INSTR_TLB_ERROR" 91 "FS_RESET_EXCEPT_CENTRAL" 47 "FS_RESET_CYCLE_MON" 49 "FS_RESET_FCCU" 109 "FS_RESET_PROCESSOR_VERSION" 98 "FS_RESET_POWERUP_SEQ_TIMEOUT" 67 "FS_RESET_FCCU_FAULT_SIGNALED" 89 "FS_RESET_FCCU_CHECKER_MISMATCH" 107 "FS_RESET_INTERNAL_VOLTAGE_FAILED" 43 "FS_RESET_INVALID_SAFESECTION" 97 "FS_RESET_IOHWAB_TIMEOUT" 94 "FS_RESET_EXCEPT_RESERVED_14" 56 "FS_RESET_NVM_TIMEOUT" 36 "FS_RESET_CPU_REGISTER_CHECK" 40 "FS_RESET_ALU_CHECK" 26 "FS_RESET_SYSTEM_CYCLE_MON" 30 "FS_RESET_DCACHE_MARCHC" 52 "FS_RESET_EXCEPT_AP_UNAVAILABLE" 28 "FS_RESET_TASK_STACK" 105 "FS_RESET_LBIST_FAILED" 81 "FS_RESET_ECC_CORE_DCACHE_2BIT" 27 "FS_RESET_TASK_MON_LOGIC" 64 "FS_RESET_SPE_CHECK" 2 "FS_RESET_MCU_SUPPLY" 62 "FS_RESET_ECC_SPT_2BIT" 95 "FS_RESET_EXCEPT_RESERVED_15" 86 "FS_RESET_SPI_ATIC_FAULT" 68 "FS_RESET_CLKMON_INITIALIZATION" 46 "FS_RESET_TESTCASE_CONFIG" 24 "FS_RESET_EXCEPT_ERROR_TPU_RAM" 44 "FS_RESET_EXCEPT_CORE_FREEZE" 34 "FS_RESET_TPU_RAM_ADDRESS_BUS0" 65 "FS_RESET_HW_SW_INCOMPATIBLE" 71 "FS_RESET_WATCHDOG_INITIALIZATION" 17 "FS_RESET_EXCEPT_DATA_TLB_ERROR" 79 "FS_RESET_ECC_CORE_DMEM_2BIT" 15 "FS_RESET_EXCEPT_FIXED_INTER" 70 "FS_RESET_CLKMON_CALIBRATION" 66 "FS_RESET_FCCU_CORRUPTED_CONFIG" 72 "FS_RESET_WATCHDOG" 88 "FS_RESET_PLL_STUCK" 76 "FS_RESET_ECC_SRAM_2BIT" 57 "FS_RESET_CORE1_STACK_OVERFLOW" 90 "FS_RESET_FCCU_HEALED_FAULT" 77 "FS_RESET_ECC_FLASH_2BIT" 6 "FS_RESET_ROM_ECC_2BIT" 80 "FS_RESET_ECC_CORE_IMEM_2BIT" 51 "FS_RESET_EXCEPT_SYSTEM_CALL" 10 "FS_RESET_EXCEPT_INSTRUCT_STORE" 59 "FS_RESET_DRIVERINIT_FAILED" 4 "FS_RESET_ROM_ECC_1BIT" 54 "FS_RESET_EXCEPT_ECC1BITERROR" 22 "FS_RESET_EXCEPT_SHUTDOWN_OS" 35 "FS_RESET_TPU_RAM_ADDRESS_BUS1" 60 "FS_RESET_ECC_HARDWARE_FAILURE" 110 "FS_RESET_ADC_CALIBRATION" 48 "FS_RESET_INTENTIONAL_RESET" 75 "FS_RESET_SMPU" 58 "FS_RESET_CORE2_STACK_OVERFLOW" 33 "FS_RESET_SRAM_ADDRESS_BUS1" 21 "FS_RESET_EXCEPT_EFP_ROUND" 8 "FS_RESET_EXCEPT_MACH_CHECK" 5 "FS_RESET_RAM_ECC_2BIT" 14 "FS_RESET_EXCEPT_DEBUG" 108 "FS_RESET_FLASH_CYCLIC_CHECK" 19 "FS_RESET_EXCEPT_SPE_UNAVAIL" 73 "FS_RESET_ECC_PATTERN_MISSING" 96 "FS_RESET_UBATT_OUT_OF_RANGE" 82 "FS_RESET_ECC_CORE_ICACHE_2BIT" 31 "FS_RESET_ECC_TIMEOUT" 93 "FS_RESET_EXCEPT_RESERVED_13" 38 "FS_RESET_APPL_CRC_CHECK" 50 "FS_RESET_E_FLOATINGPOINT_UNAVAIL" ;
VAL_ 1365 RADC_a041_vinErrType 1 "LENGTH" 0 "NONE" 2 "CHECKSUM" 3 "SEQUENCE" 5 "OVERRUN" 4 "INVALID_DATA" ;
VAL_ 1365 RADC_a017_adcUnderVoltType 2 "ADC_3V3_LIN_PA_UNDER_VOLTAGE" 7 "ADC_5V_SMPS_UNDER_VOLTAGE" 1 "ADC_3V3_LIN_VOLTAGECO_UNDER_VOLTAGE" 0 "ADC_1V25_SMPS_UNDER_VOLTAGE" 6 "ADC_4V5_LIN_VOLTAGECO_UNDER_VOLTAGE" 5 "ADC_3V8_SMPS_UNDER_VOLTAGE" 3 "ADC_3V3_LIN_DIGITAL_UNDER_VOLTAGE" 4 "ADC_3V3_LIN_ANALOG_UNDER_VOLTAGE" ;
VAL_ 1365 RADC_alertState 0 "ALERT_CLEARED" 1 "ALERT_SET" ;
VAL_ 1365 RADC_alertID 42 "RADC_a042_carConfigErr" 50 "RADC_a050_mismatchCountry" 7 "RADC_a007_ecuGptCheckError" 54 "RADC_a054_blockageInfo_Frame_1" 36 "RADC_a036_carConfigMIA" 34 "RADC_a034_vehDynamicsError" 51 "RADC_a051_mismatchEPASType" 2 "RADC_a002_ecuAdcError" 47 "RADC_a047_mismatchChassisType" 31 "RADC_a031_sensorMisaligned" 39 "RADC_a039_vehicleStateMIA" 46 "RADC_a046_wheelSpeedsErr" 5 "RADC_a005_ecuEcuMError" 11 "RADC_a011_ecuMcemError" 21 "RADC_a021_overTempCrit" 23 "RADC_a023_underTemp" 13 "RADC_a013_ecuWdgError" 26 "RADC_a026_underVoltage" 24 "RADC_a024_underTempCrit" 53 "RADC_a053_emError" 14 "RADC_a014_fctSelfTestNotDone" 25 "RADC_a025_overVoltage" 38 "RADC_a038_steeringWheelAngleMIA" 17 "RADC_a017_adcUnderVolt" 22 "RADC_a022_tempImplausible" 9 "RADC_a009_plantModeActive" 41 "RADC_a041_vinErr" 35 "RADC_a035_vinMIA" 12 "RADC_a012_ecuSpiError" 19 "RADC_a019_internalSoftwareFault" 30 "RADC_a030_rspError" 44 "RADC_a044_steeringWheelAngleErr" 18 "RADC_a018_internalHardwareFault" 4 "RADC_a004_ecuCrcHwError" 29 "RADC_a029_rhcError" 6 "RADC_a006_ecuFimError" 48 "RADC_a048_mismatchAirSuspension" 32 "RADC_a032_sensorBlocked" 0 "RADC_ALERT_DO_NOT_USE_ZERO" 43 "RADC_a043_inertialSignalsErr" 8 "RADC_a008_ecuHwSwInterlock" 1 "RADC_a001_can1BusOff" 49 "RADC_a049_mismatchFourWheelDrive" 10 "RADC_a010_ecuIoHwAbError" 33 "RADC_a033_sensorNeverAligned" 27 "RADC_a027_nvmFailure" 52 "RADC_a052_mismatcRadPos" 20 "RADC_a020_overTemp" 15 "RADC_a015_fctSenInterference" 40 "RADC_a040_wheelSpeedsMIA" 16 "RADC_a016_adcOverVolt" 45 "RADC_a045_vehicleStateErr" 55 "RADC_a055_blockageInfo_Frame_2" 28 "RADC_a028_rfChipError" 37 "RADC_a037_inertialSignalsMIA" 3 "RADC_a003_ecuBistDisabled" ;
VAL_ 583 DAS_lastWatchdogCode 39 "TELEMETRY_PACKAGER_FAILED" 51 "AP_STATE_MACHINE_FAILED" 57 "ATLAS_FAILED" 72 "PARKING_BEHAVIOR_FAILED" 0 "NO_TASK_FAILED" 70 "DYNAMICS_FAILED" 61 "IMU_FAILED" 53 "LOCALIZER_FAILED" 56 "ROAD_ESTIMATOR_FAILED" 67 "CAMERA_FAILED" 41 "SNAPSHOT_FAILED" 52 "CONTROLLER_FAILED" 68 "ACTIVE_SAFETY_FAILED" 71 "FIELD_CALIBRATION_FAILED" 48 "INERTIATOR_FAILED" 43 "LEGACY_FAILED" 44 "WATCHDOG_FAILED" 66 "MAP_MANAGER_FAILED" 50 "ARBITER_FAILED" 69 "UI_SERVER_FAILED" 60 "RAIN_LIGHT_SENSING_FAILED" 45 "CAN_RX_FAILED" 54 "MISSION_PLANNER_FAILED" 49 "GPS_FAILED" 63 "LANE_CHANGE_BEHAVIOR_FAILED" 62 "UBX_LOG_FAILED" 42 "VISION_FAILED" 47 "TEMPERATURE_MONITOR_FAILED" 40 "TELEMETRY_FAILED" 46 "CAN_TX_FAILED" 30 "UNKNOWN_TASK_FAILED" 65 "DRIVER_MONITOR_FAILED" 59 "SNAPSHOT_TRIGGER_CLIENT_FAILED" 55 "PERCEPTION_FAILED" 58 "STAY_IN_LANE_BEHAVIOR_FAILED" ;
VAL_ 583 DAS_laneChangeState 29 "LANE_CHANGE_BLOCKED_LEFT" 23 "LANE_CHANGE_ABORTING_BEHAVIOR_CHANGED" 30 "LANE_CHANGE_BLOCKED_RIGHT" 21 "LANE_CHANGE_ABORTING_INVALID_BEHAVIOR" 28 "LANE_CHANGE_IN_PROGRESS_RIGHT" 36 "LANE_CHANGE_UNAVAILABLE_BLINDSPOT_RESTRICTED" 2 "LANE_CHANGE_UNAVAILABLE_SPEED" 14 "LANE_CHANGE_ABORTING_BLIND_SPOT_OCCUPIED" 0 "LANE_CHANGE_UNAVAILABLE_DISABLED" 38 "LANE_CHANGE_UNAVAILABLE_NO_REAR_OBJECT" 7 "LANE_CHANGE_UNAVAILABLE_INVALID_MODE" 12 "LANE_CHANGE_ABORTING_BLINKER" 63 "LANE_CHANGE_UNKNOWN" 25 "LANE_CHANGE_ABORTING_ULC_CONFIRMATION_TIMEOUT" 19 "LANE_CHANGE_ABORTING_ACC_AUTOSTEER_ACTIVATED" 17 "LANE_CHANGE_ABORTING_FORK_AVAILABLE" 39 "LANE_CHANGE_ABORTING_SOURCE_AND_TARGET_LANES_MERGED" 6 "LANE_CHANGE_UNAVAILABLE_ULTRASONICS_NOT_READY" 11 "LANE_CHANGE_ABORTING_INACTIVE" 3 "LANE_CHANGE_UNAVAILABLE_NO_LANES" 34 "LANE_CHANGE_ABORTING_TIGHT_TURN_RADIUS" 13 "LANE_CHANGE_ABORTING_TIMEOUT" 33 "LANE_CHANGE_ABORTING_TOLL_BOOTH_DETECTED" 8 "LANE_CHANGE_AVAILABLE_LEFT_ONLY" 5 "LANE_CHANGE_UNAVAILABLE_FORK_MODE" 31 "LANE_CHANGE_ABORTING_GORE_POINT" 18 "LANE_CHANGE_ABORTING_LOST_VISION_POSE" 16 "LANE_CHANGE_ABORTING_LINE_TYPE" 10 "LANE_CHANGE_AVAILABLE_BOTH" 1 "LANE_CHANGE_UNAVAILABLE_ROAD_NOT_APPROPRIATE" 24 "LANE_CHANGE_ABORTING_HIGH_ALC_PROGRESS_ERROR" 9 "LANE_CHANGE_AVAILABLE_RIGHT_ONLY" 35 "LANE_CHANGE_ABORTING_WEATHER" 37 "LANE_CHANGE_ABORTING_NO_HANDS_ON" 15 "LANE_CHANGE_ABORTING_INVALID_MODE" 26 "LANE_CHANGE_ABORTING_ALC_REQUEST_BEFORE_ULC_CONFIRM" 22 "LANE_CHANGE_ABORTING_BELOW_MIN_SPEED" 4 "LANE_CHANGE_UNAVAILABLE_INACTIVE" 32 "LANE_CHANGE_ABORTING_CONSTRUCTION_DETECTED" 27 "LANE_CHANGE_IN_PROGRESS_LEFT" 20 "LANE_CHANGE_ABORTING_ULC_BLINKER_TIMEOUT" ;
VAL_ 583 DAS_forkState 2 "FORK_UNAVAILABLE_AP_INACTIVE" 3 "FORK_UNAVAILABLE_CONSTRUCTION" 19 "FORK_ABORT_NOT_LEFT_LANE" 24 "FORK_UNAVAILABLE_WEATHER" 4 "FORK_UNAVAILABLE_CONTROLLED_ACCESS_TOO_FAR" 15 "FORK_ACTIVE_RIGHT_USER" 10 "FORK_IDLE_RIGHT_FORK_AVAILABLE" 21 "FORK_ABORT_DISALLOW" 7 "FORK_UNAVAILABLE_OTHER" 18 "FORK_ABORT_BLINKER_CHANGE" 17 "FORK_ABORT_CONTROL_INACTIVE" 20 "FORK_ABORT_NOT_RIGHT_LANE" 13 "FORK_ACTIVE_LEFT_USER" 16 "FORK_FORK_COMPLETE" 23 "FORK_UNAVAILABLE_TIGHT_TURN_RADIUS" 12 "FORK_ACTIVE_LEFT_NAV" 8 "FORK_IDLE_BOTH_FORKS_AVAILABLE" 11 "FORK_IDLE_NO_FORKS_AVAILABLE" 14 "FORK_ACTIVE_RIGHT_NAV" 1 "FORK_UNAVAILABLE_DISABLED" 6 "FORK_UNAVAILABLE_TOLL_BOOTH" 5 "FORK_UNAVAILABLE_DON_INACTIVE" 0 "FORK_INVALID" 22 "FORK_ABORT_OTHER" 9 "FORK_IDLE_LEFT_FORK_AVAILABLE" ;
VAL_ 583 DAS_rqstedBehaviorStatus 21 "RQST_BEHAVIOR_BLOCKED_BY_SLOW_TARGET_R" 1 "RQST_BEHAVIOR_NO_SRC_POLYLANE" 10 "RQST_BEHAVIOR_BLOCKED_BY_ULTRASOUND_AND_CAMERA_L" 4 "RQST_BEHAVIOR_NO_SOURCE_LANE_ON_MAP" 22 "RQST_BEHAVIOR_INVALID_PLAN" 3 "RQST_BEHAVIOR_MAP_NOT_INITIALIZED" 13 "RQST_BEHAVIOR_BLOCKED_BY_BLINDSPOT_CAMERA_R" 7 "RQST_BEHAVIOR_BLOCKED_BY_ULTRASOUND_L" 5 "RQST_BEHAVIOR_NO_TARGET_LANE_ON_MAP" 14 "RQST_BEHAVIOR_BLOCKED_BY_BLINDSPOT_CAMERA_INVALID_R" 2 "RQST_BEHAVIOR_NO_DEST_POLYLANE" 11 "RQST_BEHAVIOR_BLOCKED_BY_LANE_TYPE_L" 16 "RQST_BEHAVIOR_BLOCKED_BY_LANE_TYPE_R" 6 "RQST_BEHAVIOR_BUILD_ARGUMENT_FAIL" 17 "RQST_BEHAVIOR_ROAD_NOT_APPROPRIATE" 19 "RQST_BEHAVIOR_BAD_ORIGIN_UPDATE" 9 "RQST_BEHAVIOR_BLOCKED_BY_BLINDSPOT_CAMERA_INVALID_L" 8 "RQST_BEHAVIOR_BLOCKED_BY_BLINDSPOT_CAMERA_L" 12 "RQST_BEHAVIOR_BLOCKED_BY_ULTRASOUND_R" 18 "RQST_BEHAVIOR_OUT_OF_DATE" 0 "RQST_BEHAVIOR_VALID" 15 "RQST_BEHAVIOR_BLOCKED_BY_ULTRASOUND_AND_CAMERA_R" 20 "RQST_BEHAVIOR_BLOCKED_BY_SLOW_TARGET_L" ;
VAL_ 583 DAS_autopilotAbortReason 20 "ABORT_RADAR_FAULT" 27 "ABORT_CONTROLLER_NOT_ALLOWED" 11 "ABORT_CRUISE_NOT_ACTIVE" 24 "ABORT_ROAD_ESTIMATOR_HEALTH" 13 "ABORT_TRAILER_MODE_ACTIVE" 63 "ABORT_REASON_MAX" 29 "ABORT_MAP_HEALTH" 16 "ABORT_EPAS_EAC_ERROR" 30 "ABORT_CONTROLLER_STALE_REFERENCE" 28 "ABORT_THERMAL_ISSUE" 12 "ABORT_USER_DISABLED" 8 "ABORT_VCFRONT_MIA" 22 "ABORT_ACC_CANCEL_SILENT" 15 "ABORT_EPAS_EAC_NOT_ACTIVE" 1 "ABORT_WATCHDOG_HEALTH" 37 "ABORT_REACHED_END_OF_NAV_STOP" 14 "ABORT_VEHICLE_SPEED_ABOVE_MAX" 6 "ABORT_SCCM_MIA" 32 "ABORT_CONTROLLER_BAD_REF_UPDATE" 23 "ABORT_ACC_FAULT" 0 "ABORT_NONE" 26 "ABORT_CONTROLLER_SOLVER" 2 "ABORT_DI_MIA" 35 "ABORT_MISSION_PLANNER_NO_VISION_LANES_FOUND" 9 "ABORT_VCRIGHT_MIA" 36 "ABORT_GORE_INCURSION" 25 "ABORT_CONTROLLER_REFERENCE" 31 "ABORT_CONTROLLER_STALE_LOCALIZATION" 38 "ABORT_STEERING_SATURATED_LANE_DEPARTURE" 4 "ABORT_EPAS_MIA" 10 "ABORT_CRUISE_FAULT" 17 "ABORT_CAMERA_FAILSAFES" 21 "ABORT_ACC_CANCEL_GENERIC" 5 "ABORT_GTW_MIA" 33 "ABORT_AEB" 7 "ABORT_RADAR_MIA" 19 "ABORT_RADAR_BLIND" 3 "ABORT_ESP_MIA" 18 "ABORT_CAMERA_CALIBRATION" 34 "ABORT_CONTROLLER_REF_TOO_SHORT" ;
VAL_ 583 DAS_controllerHealth 3 "CONTROLLER_SOLVER_FAILURE" 1 "CONTROLLER_DEGRADED" 2 "CONTROLLER_CRITICAL" 0 "CONTROLLER_HEALTHY" ;
VAL_ 583 DAS_behaviorReport 29 "BEHAVIOR_MP_AP_INACTIVE" 25 "BEHAVIOR_MP_DRIVER_MONITOR" 16 "BEHAVIOR_VISION_SPEEDS" 15 "BEHAVIOR_SLOWING_FOR_TARGET_LANE" 27 "BEHAVIOR_MP_DI_CRUISE" 6 "BEHAVIOR_TRAFFIC_CONTROL_STOPPED_STATE" 17 "BEHAVIOR_NAV_FLEET_SPEEDS" 19 "BEHAVIOR_MERGE_VEHICLE_LEFT" 13 "BEHAVIOR_MAP_LANE_GEOMETRY" 20 "BEHAVIOR_MERGE_VEHICLE_RIGHT" 18 "BEHAVIOR_NAV_PATH_CSA" 2 "BEHAVIOR_CURVE_SPEED_ADAPTATION" 9 "BEHAVIOR_TARGET_LANE_VEHICLE" 4 "BEHAVIOR_KEEP_CALM" 10 "BEHAVIOR_UNDERTAKE_VEHICLE" 26 "BEHAVIOR_MP_AP_STATE_MACHINE" 8 "BEHAVIOR_IN_LANE_VEHICLE" 21 "BEHAVIOR_CUTIN_VEHICLE_LEFT" 14 "BEHAVIOR_DRIVABLE_SPACE_VIOLATION" 7 "BEHAVIOR_UNDERTAKE_ASSIST_KEEP_CALM" 12 "BEHAVIOR_VISION_LANE_GEOMETRY" 23 "BEHAVIOR_MP_AP_RESTRICTION" 28 "BEHAVIOR_MP_ULC" 11 "BEHAVIOR_TRAFFIC_CONTROL" 1 "BEHAVIOR_VIEW_RANGE" 5 "BEHAVIOR_FLEET_SPEEDS" 22 "BEHAVIOR_CUTIN_VEHICLE_RIGHT" 24 "BEHAVIOR_MP_NOT_BUCKLED" 3 "BEHAVIOR_RADAR_ONLY_BRAKING" ;
VAL_ 583 DAS_alcInternalState 3 "ALC_BEHAVIOR_CHECK" 8 "ALC_ACTIVE_ACC_LEFT" 7 "ALC_ACTIVE_RIGHT" 5 "ALC_PRE_ACTIVE_RIGHT" 1 "ALC_IDLE" 2 "ALC_ABORTING" 10 "ALC_SOFT_ABORTING_LEFT" 0 "ALC_DISABLED" 9 "ALC_ACTIVE_ACC_RIGHT" 11 "ALC_SOFT_ABORTING_RIGHT" 4 "ALC_PRE_ACTIVE_LEFT" 6 "ALC_ACTIVE_LEFT" ;
VAL_ 583 DAS_controllerRef 0 "CONTROLLER_REFERENCE_HEALTHY" 5 "CONTROLLER_REFERENCE_REF_TOO_SHORT" 6 "CONTROLLER_REFERENCE_INDETERMINATE" 4 "CONTROLLER_REFERENCE_BAD_REF_UPDATE" 1 "CONTROLLER_REFERENCE_UNHEALTHY" 3 "CONTROLLER_REFERENCE_STALE_LOCALIZATION" 2 "CONTROLLER_REFERENCE_STALE_REFERENCE" ;
VAL_ 583 DAS_mapAvailability 0 "APM_MAP_NOT_AVAILABLE" 1 "APM_MAP_AVAILABLE" ;
VAL_ 583 DAS_localizerHealth 2 "LOCALIZER_RECOVERING" 4 "LOCALIZER_SHADOW" 6 "LOCALIZER_LANE_LOCALIZED" 5 "LOCALIZER_NEAR_LANE_LOCALIZED" 0 "LOCALIZER_CRITICAL" 7 "LOCALIZER_FINE_LOCALIZED_STICKING" 1 "LOCALIZER_DEGRADED" 3 "LOCALIZER_NO_LANE_LOCALIZED" 8 "LOCALIZER_FINE_LOCALIZED_CONFIRMED" ;
VAL_ 583 DAS_roadEstimator 1 "ROAD_ESTIMATOR_UNSTABLE_MEASUREMENTS" 3 "ROAD_ESTIMATOR_CRITICAL" 0 "ROAD_ESTIMATOR_HEALTHY" 2 "ROAD_ESTIMATOR_DEGRADED" ;
VAL_ 583 DAS_missionPlan 2 "MISSION_PLAN_MAP_AND_VISION" 1 "MISSION_PLAN_VISION_ONLY" 0 "MISSION_PLAN_MAP_ONLY" 3 "MISSION_PLAN_INVALID" ;
VAL_ 273 RCM_verticalAccelQF 0 "FAULTED" 1 "NOT_FAULTED" ;
VAL_ 273 RCM_lateralAccelQF 0 "FAULTED" 1 "NOT_FAULTED" ;
VAL_ 273 RCM_longitudinalAccelQF 0 "FAULTED" 1 "NOT_FAULTED" ;
VAL_ 273 RCM_verticalAccel -32768 "SNA" ;
VAL_ 273 RCM_lateralAccel -32768 "SNA" ;
VAL_ 273 RCM_longitudinalAccel -32768 "SNA" ;
VAL_ 1096 UI_anonDebugFlag4 0 "OFF" 1 "ON" ;
VAL_ 1096 UI_anonDebugFlag3 0 "OFF" 1 "ON" ;
VAL_ 1096 UI_anonDebugFlag2 0 "OFF" 1 "ON" ;
VAL_ 1096 UI_anonDebugFlag1 0 "OFF" 1 "ON" ;
VAL_ 1297 RCM_a011_eventAccelPedalPos 255 "SNA" ;
VAL_ 1297 RCM_a077_eventAccelPedalPos 255 "SNA" ;
VAL_ 1297 RCM_a008_eventAccelPedalPos 255 "SNA" ;
VAL_ 1297 RCM_a109_eventAccelPedalPos 255 "SNA" ;
VAL_ 1297 RCM_a033_eventAccelPedalPos 255 "SNA" ;
VAL_ 1297 RCM_a080_eventAccelPedalPos 255 "SNA" ;
VAL_ 1297 RCM_a099_eventAccelPedalPos 255 "SNA" ;
VAL_ 1297 RCM_a055_eventAccelPedalPos 255 "SNA" ;
VAL_ 1297 RCM_a110_eventAccelPedalPos 255 "SNA" ;
VAL_ 1297 RCM_a070_eventAccelPedalPos 255 "SNA" ;
VAL_ 1297 RCM_a034_eventAccelPedalPos 255 "SNA" ;
VAL_ 1297 RCM_a117_eventAccelPedalPos 255 "SNA" ;
VAL_ 1297 RCM_a052_eventAccelPedalPos 255 "SNA" ;
VAL_ 1297 RCM_a087_eventAccelPedalPos 255 "SNA" ;
VAL_ 1297 RCM_a069_eventAccelPedalPos 255 "SNA" ;
VAL_ 1297 RCM_a016_eventAccelPedalPos 255 "SNA" ;
VAL_ 1297 RCM_a020_eventAccelPedalPos 255 "SNA" ;
VAL_ 1297 RCM_a103_eventAccelPedalPos 255 "SNA" ;
VAL_ 1297 RCM_a093_eventAccelPedalPos 255 "SNA" ;
VAL_ 1297 RCM_a002_eventAccelPedalPos 255 "SNA" ;
VAL_ 1297 RCM_a039_eventAccelPedalPos 255 "SNA" ;
VAL_ 1297 RCM_a046_eventAccelPedalPos 255 "SNA" ;
VAL_ 1297 RCM_a064_eventAccelPedalPos 255 "SNA" ;
VAL_ 1297 RCM_a018_eventAccelPedalPos 255 "SNA" ;
VAL_ 1297 RCM_a100_eventAccelPedalPos 255 "SNA" ;
VAL_ 1297 RCM_a023_eventAccelPedalPos 255 "SNA" ;
VAL_ 1297 RCM_a045_eventAccelPedalPos 255 "SNA" ;
VAL_ 1297 RCM_a001_eventAccelPedalPos 255 "SNA" ;
VAL_ 1297 RCM_a090_eventAccelPedalPos 255 "SNA" ;
VAL_ 1297 RCM_a067_eventAccelPedalPos 255 "SNA" ;
VAL_ 1297 RCM_a089_eventAccelPedalPos 255 "SNA" ;
VAL_ 1297 RCM_a105_eventAccelPedalPos 255 "SNA" ;
VAL_ 1297 RCM_a026_eventAccelPedalPos 255 "SNA" ;
VAL_ 1297 RCM_a059_eventAccelPedalPos 255 "SNA" ;
VAL_ 1297 RCM_a004_eventAccelPedalPos 255 "SNA" ;
VAL_ 1297 RCM_a062_eventAccelPedalPos 255 "SNA" ;
VAL_ 1297 RCM_a040_eventAccelPedalPos 255 "SNA" ;
VAL_ 1297 RCM_a095_eventAccelPedalPos 255 "SNA" ;
VAL_ 1297 RCM_a012_eventAccelPedalPos 255 "SNA" ;
VAL_ 1297 RCM_a074_eventAccelPedalPos 255 "SNA" ;
VAL_ 1297 RCM_a029_eventAccelPedalPos 255 "SNA" ;
VAL_ 1297 RCM_a083_eventAccelPedalPos 255 "SNA" ;
VAL_ 1297 RCM_a030_eventAccelPedalPos 255 "SNA" ;
VAL_ 1297 RCM_a113_eventAccelPedalPos 255 "SNA" ;
VAL_ 1297 RCM_a056_eventAccelPedalPos 255 "SNA" ;
VAL_ 1297 RCM_a116_eventAccelPedalPos 255 "SNA" ;
VAL_ 1297 RCM_a053_eventAccelPedalPos 255 "SNA" ;
VAL_ 1297 RCM_a071_eventAccelPedalPos 255 "SNA" ;
VAL_ 1297 RCM_a035_eventAccelPedalPos 255 "SNA" ;
VAL_ 1297 RCM_a068_eventAccelPedalPos 255 "SNA" ;
VAL_ 1297 RCM_a086_eventAccelPedalPos 255 "SNA" ;
VAL_ 1297 RCM_a017_eventAccelPedalPos 255 "SNA" ;
VAL_ 1297 RCM_a085_eventAccelPedalPos 255 "SNA" ;
VAL_ 1297 RCM_a014_eventAccelPedalPos 255 "SNA" ;
VAL_ 1297 RCM_a036_eventAccelPedalPos 255 "SNA" ;
VAL_ 1297 RCM_a049_eventAccelPedalPos 255 "SNA" ;
VAL_ 1297 RCM_a050_eventAccelPedalPos 255 "SNA" ;
VAL_ 1297 RCM_a115_eventAccelPedalPos 255 "SNA" ;
VAL_ 1297 RCM_a072_eventAccelPedalPos 255 "SNA" ;
VAL_ 1297 RCM_a066_eventAccelPedalPos 255 "SNA" ;
VAL_ 1297 RCM_a088_eventAccelPedalPos 255 "SNA" ;
VAL_ 1297 RCM_a022_eventAccelPedalPos 255 "SNA" ;
VAL_ 1297 RCM_a101_eventAccelPedalPos 255 "SNA" ;
VAL_ 1297 RCM_a044_eventAccelPedalPos 255 "SNA" ;
VAL_ 1297 RCM_a118_eventAccelPedalPos 255 "SNA" ;
VAL_ 1297 RCM_a000_eventAccelPedalPos 255 "SNA" ;
VAL_ 1297 RCM_a019_eventAccelPedalPos 255 "SNA" ;
VAL_ 1297 RCM_a091_eventAccelPedalPos 255 "SNA" ;
VAL_ 1297 RCM_a061_eventAccelPedalPos 255 "SNA" ;
VAL_ 1297 RCM_a007_eventAccelPedalPos 255 "SNA" ;
VAL_ 1297 RCM_a078_eventAccelPedalPos 255 "SNA" ;
VAL_ 1297 RCM_a043_eventAccelPedalPos 255 "SNA" ;
VAL_ 1297 RCM_a106_eventAccelPedalPos 255 "SNA" ;
VAL_ 1297 RCM_a025_eventAccelPedalPos 255 "SNA" ;
VAL_ 1297 RCM_a096_eventAccelPedalPos 255 "SNA" ;
VAL_ 1297 RCM_a075_eventAccelPedalPos 255 "SNA" ;
VAL_ 1297 RCM_a082_eventAccelPedalPos 255 "SNA" ;
VAL_ 1297 RCM_a112_eventAccelPedalPos 255 "SNA" ;
VAL_ 1297 RCM_a057_eventAccelPedalPos 255 "SNA" ;
VAL_ 1297 RCM_a013_eventAccelPedalPos 255 "SNA" ;
VAL_ 1297 RCM_a031_eventAccelPedalPos 255 "SNA" ;
VAL_ 1297 RCM_a028_eventAccelPedalPos 255 "SNA" ;
VAL_ 1297 RCM_a098_eventAccelPedalPos 255 "SNA" ;
VAL_ 1297 RCM_a111_eventAccelPedalPos 255 "SNA" ;
VAL_ 1297 RCM_a054_eventAccelPedalPos 255 "SNA" ;
VAL_ 1297 RCM_a076_eventAccelPedalPos 255 "SNA" ;
VAL_ 1297 RCM_a009_eventAccelPedalPos 255 "SNA" ;
VAL_ 1297 RCM_a010_eventAccelPedalPos 255 "SNA" ;
VAL_ 1297 RCM_a032_eventAccelPedalPos 255 "SNA" ;
VAL_ 1297 RCM_a081_eventAccelPedalPos 255 "SNA" ;
VAL_ 1297 RCM_a108_eventAccelPedalPos 255 "SNA" ;
VAL_ 1297 RCM_a037_eventAccelPedalPos 255 "SNA" ;
VAL_ 1297 RCM_a051_eventAccelPedalPos 255 "SNA" ;
VAL_ 1297 RCM_a114_eventAccelPedalPos 255 "SNA" ;
VAL_ 1297 RCM_a048_eventAccelPedalPos 255 "SNA" ;
VAL_ 1297 RCM_a073_eventAccelPedalPos 255 "SNA" ;
VAL_ 1297 RCM_a084_eventAccelPedalPos 255 "SNA" ;
VAL_ 1297 RCM_a015_eventAccelPedalPos 255 "SNA" ;
VAL_ 1297 RCM_a047_eventAccelPedalPos 255 "SNA" ;
VAL_ 1297 RCM_a065_eventAccelPedalPos 255 "SNA" ;
VAL_ 1297 RCM_a003_eventAccelPedalPos 255 "SNA" ;
VAL_ 1297 RCM_a021_eventAccelPedalPos 255 "SNA" ;
VAL_ 1297 RCM_a102_eventAccelPedalPos 255 "SNA" ;
VAL_ 1297 RCM_a092_eventAccelPedalPos 255 "SNA" ;
VAL_ 1297 RCM_a038_eventAccelPedalPos 255 "SNA" ;
VAL_ 1297 RCM_a042_eventAccelPedalPos 255 "SNA" ;
VAL_ 1297 RCM_a060_eventAccelPedalPos 255 "SNA" ;
VAL_ 1297 RCM_a079_eventAccelPedalPos 255 "SNA" ;
VAL_ 1297 RCM_a006_eventAccelPedalPos 255 "SNA" ;
VAL_ 1297 RCM_a097_eventAccelPedalPos 255 "SNA" ;
VAL_ 1297 RCM_a024_eventAccelPedalPos 255 "SNA" ;
VAL_ 1297 RCM_a107_eventAccelPedalPos 255 "SNA" ;
VAL_ 1297 RCM_a094_eventAccelPedalPos 255 "SNA" ;
VAL_ 1297 RCM_a063_eventAccelPedalPos 255 "SNA" ;
VAL_ 1297 RCM_a027_eventAccelPedalPos 255 "SNA" ;
VAL_ 1297 RCM_a104_eventAccelPedalPos 255 "SNA" ;
VAL_ 1297 RCM_a005_eventAccelPedalPos 255 "SNA" ;
VAL_ 1297 RCM_a041_eventAccelPedalPos 255 "SNA" ;
VAL_ 1297 RCM_a058_eventAccelPedalPos 255 "SNA" ;
VAL_ 1297 RCM_a094_eventDriverBrakeApply 1 "Not_Applied" 3 "Faulty_SNA" 2 "Driver_applying_brakes" 0 "NotInit_orOff" ;
VAL_ 1297 RCM_a058_eventDriverBrakeApply 1 "Not_Applied" 3 "Faulty_SNA" 2 "Driver_applying_brakes" 0 "NotInit_orOff" ;
VAL_ 1297 RCM_a104_eventDriverBrakeApply 1 "Not_Applied" 3 "Faulty_SNA" 2 "Driver_applying_brakes" 0 "NotInit_orOff" ;
VAL_ 1297 RCM_a027_eventDriverBrakeApply 1 "Not_Applied" 3 "Faulty_SNA" 2 "Driver_applying_brakes" 0 "NotInit_orOff" ;
VAL_ 1297 RCM_a041_eventDriverBrakeApply 1 "Not_Applied" 3 "Faulty_SNA" 2 "Driver_applying_brakes" 0 "NotInit_orOff" ;
VAL_ 1297 RCM_a005_eventDriverBrakeApply 1 "Not_Applied" 3 "Faulty_SNA" 2 "Driver_applying_brakes" 0 "NotInit_orOff" ;
VAL_ 1297 RCM_a063_eventDriverBrakeApply 1 "Not_Applied" 3 "Faulty_SNA" 2 "Driver_applying_brakes" 0 "NotInit_orOff" ;
VAL_ 1297 RCM_a013_eventDriverBrakeApply 1 "Not_Applied" 3 "Faulty_SNA" 2 "Driver_applying_brakes" 0 "NotInit_orOff" ;
VAL_ 1297 RCM_a031_eventDriverBrakeApply 1 "Not_Applied" 3 "Faulty_SNA" 2 "Driver_applying_brakes" 0 "NotInit_orOff" ;
VAL_ 1297 RCM_a057_eventDriverBrakeApply 1 "Not_Applied" 3 "Faulty_SNA" 2 "Driver_applying_brakes" 0 "NotInit_orOff" ;
VAL_ 1297 RCM_a112_eventDriverBrakeApply 1 "Not_Applied" 3 "Faulty_SNA" 2 "Driver_applying_brakes" 0 "NotInit_orOff" ;
VAL_ 1297 RCM_a082_eventDriverBrakeApply 1 "Not_Applied" 3 "Faulty_SNA" 2 "Driver_applying_brakes" 0 "NotInit_orOff" ;
VAL_ 1297 RCM_a028_eventDriverBrakeApply 1 "Not_Applied" 3 "Faulty_SNA" 2 "Driver_applying_brakes" 0 "NotInit_orOff" ;
VAL_ 1297 RCM_a075_eventDriverBrakeApply 1 "Not_Applied" 3 "Faulty_SNA" 2 "Driver_applying_brakes" 0 "NotInit_orOff" ;
VAL_ 1297 RCM_a117_eventDriverBrakeApply 1 "Not_Applied" 3 "Faulty_SNA" 2 "Driver_applying_brakes" 0 "NotInit_orOff" ;
VAL_ 1297 RCM_a052_eventDriverBrakeApply 1 "Not_Applied" 3 "Faulty_SNA" 2 "Driver_applying_brakes" 0 "NotInit_orOff" ;
VAL_ 1297 RCM_a087_eventDriverBrakeApply 1 "Not_Applied" 3 "Faulty_SNA" 2 "Driver_applying_brakes" 0 "NotInit_orOff" ;
VAL_ 1297 RCM_a034_eventDriverBrakeApply 1 "Not_Applied" 3 "Faulty_SNA" 2 "Driver_applying_brakes" 0 "NotInit_orOff" ;
VAL_ 1297 RCM_a070_eventDriverBrakeApply 1 "Not_Applied" 3 "Faulty_SNA" 2 "Driver_applying_brakes" 0 "NotInit_orOff" ;
VAL_ 1297 RCM_a069_eventDriverBrakeApply 1 "Not_Applied" 3 "Faulty_SNA" 2 "Driver_applying_brakes" 0 "NotInit_orOff" ;
VAL_ 1297 RCM_a016_eventDriverBrakeApply 1 "Not_Applied" 3 "Faulty_SNA" 2 "Driver_applying_brakes" 0 "NotInit_orOff" ;
VAL_ 1297 RCM_a040_eventDriverBrakeApply 1 "Not_Applied" 3 "Faulty_SNA" 2 "Driver_applying_brakes" 0 "NotInit_orOff" ;
VAL_ 1297 RCM_a105_eventDriverBrakeApply 1 "Not_Applied" 3 "Faulty_SNA" 2 "Driver_applying_brakes" 0 "NotInit_orOff" ;
VAL_ 1297 RCM_a026_eventDriverBrakeApply 1 "Not_Applied" 3 "Faulty_SNA" 2 "Driver_applying_brakes" 0 "NotInit_orOff" ;
VAL_ 1297 RCM_a062_eventDriverBrakeApply 1 "Not_Applied" 3 "Faulty_SNA" 2 "Driver_applying_brakes" 0 "NotInit_orOff" ;
VAL_ 1297 RCM_a004_eventDriverBrakeApply 1 "Not_Applied" 3 "Faulty_SNA" 2 "Driver_applying_brakes" 0 "NotInit_orOff" ;
VAL_ 1297 RCM_a059_eventDriverBrakeApply 1 "Not_Applied" 3 "Faulty_SNA" 2 "Driver_applying_brakes" 0 "NotInit_orOff" ;
VAL_ 1297 RCM_a095_eventDriverBrakeApply 1 "Not_Applied" 3 "Faulty_SNA" 2 "Driver_applying_brakes" 0 "NotInit_orOff" ;
VAL_ 1297 RCM_a081_eventDriverBrakeApply 1 "Not_Applied" 3 "Faulty_SNA" 2 "Driver_applying_brakes" 0 "NotInit_orOff" ;
VAL_ 1297 RCM_a032_eventDriverBrakeApply 1 "Not_Applied" 3 "Faulty_SNA" 2 "Driver_applying_brakes" 0 "NotInit_orOff" ;
VAL_ 1297 RCM_a054_eventDriverBrakeApply 1 "Not_Applied" 3 "Faulty_SNA" 2 "Driver_applying_brakes" 0 "NotInit_orOff" ;
VAL_ 1297 RCM_a111_eventDriverBrakeApply 1 "Not_Applied" 3 "Faulty_SNA" 2 "Driver_applying_brakes" 0 "NotInit_orOff" ;
VAL_ 1297 RCM_a076_eventDriverBrakeApply 1 "Not_Applied" 3 "Faulty_SNA" 2 "Driver_applying_brakes" 0 "NotInit_orOff" ;
VAL_ 1297 RCM_a009_eventDriverBrakeApply 1 "Not_Applied" 3 "Faulty_SNA" 2 "Driver_applying_brakes" 0 "NotInit_orOff" ;
VAL_ 1297 RCM_a108_eventDriverBrakeApply 1 "Not_Applied" 3 "Faulty_SNA" 2 "Driver_applying_brakes" 0 "NotInit_orOff" ;
VAL_ 1297 RCM_a010_eventDriverBrakeApply 1 "Not_Applied" 3 "Faulty_SNA" 2 "Driver_applying_brakes" 0 "NotInit_orOff" ;
VAL_ 1297 RCM_a098_eventDriverBrakeApply 1 "Not_Applied" 3 "Faulty_SNA" 2 "Driver_applying_brakes" 0 "NotInit_orOff" ;
VAL_ 1297 RCM_a035_eventDriverBrakeApply 1 "Not_Applied" 3 "Faulty_SNA" 2 "Driver_applying_brakes" 0 "NotInit_orOff" ;
VAL_ 1297 RCM_a068_eventDriverBrakeApply 1 "Not_Applied" 3 "Faulty_SNA" 2 "Driver_applying_brakes" 0 "NotInit_orOff" ;
VAL_ 1297 RCM_a071_eventDriverBrakeApply 1 "Not_Applied" 3 "Faulty_SNA" 2 "Driver_applying_brakes" 0 "NotInit_orOff" ;
VAL_ 1297 RCM_a017_eventDriverBrakeApply 1 "Not_Applied" 3 "Faulty_SNA" 2 "Driver_applying_brakes" 0 "NotInit_orOff" ;
VAL_ 1297 RCM_a116_eventDriverBrakeApply 1 "Not_Applied" 3 "Faulty_SNA" 2 "Driver_applying_brakes" 0 "NotInit_orOff" ;
VAL_ 1297 RCM_a053_eventDriverBrakeApply 1 "Not_Applied" 3 "Faulty_SNA" 2 "Driver_applying_brakes" 0 "NotInit_orOff" ;
VAL_ 1297 RCM_a086_eventDriverBrakeApply 1 "Not_Applied" 3 "Faulty_SNA" 2 "Driver_applying_brakes" 0 "NotInit_orOff" ;
VAL_ 1297 RCM_a102_eventDriverBrakeApply 1 "Not_Applied" 3 "Faulty_SNA" 2 "Driver_applying_brakes" 0 "NotInit_orOff" ;
VAL_ 1297 RCM_a021_eventDriverBrakeApply 1 "Not_Applied" 3 "Faulty_SNA" 2 "Driver_applying_brakes" 0 "NotInit_orOff" ;
VAL_ 1297 RCM_a092_eventDriverBrakeApply 1 "Not_Applied" 3 "Faulty_SNA" 2 "Driver_applying_brakes" 0 "NotInit_orOff" ;
VAL_ 1297 RCM_a003_eventDriverBrakeApply 1 "Not_Applied" 3 "Faulty_SNA" 2 "Driver_applying_brakes" 0 "NotInit_orOff" ;
VAL_ 1297 RCM_a047_eventDriverBrakeApply 1 "Not_Applied" 3 "Faulty_SNA" 2 "Driver_applying_brakes" 0 "NotInit_orOff" ;
VAL_ 1297 RCM_a038_eventDriverBrakeApply 1 "Not_Applied" 3 "Faulty_SNA" 2 "Driver_applying_brakes" 0 "NotInit_orOff" ;
VAL_ 1297 RCM_a065_eventDriverBrakeApply 1 "Not_Applied" 3 "Faulty_SNA" 2 "Driver_applying_brakes" 0 "NotInit_orOff" ;
VAL_ 1297 RCM_a110_eventDriverBrakeApply 1 "Not_Applied" 3 "Faulty_SNA" 2 "Driver_applying_brakes" 0 "NotInit_orOff" ;
VAL_ 1297 RCM_a055_eventDriverBrakeApply 1 "Not_Applied" 3 "Faulty_SNA" 2 "Driver_applying_brakes" 0 "NotInit_orOff" ;
VAL_ 1297 RCM_a077_eventDriverBrakeApply 1 "Not_Applied" 3 "Faulty_SNA" 2 "Driver_applying_brakes" 0 "NotInit_orOff" ;
VAL_ 1297 RCM_a008_eventDriverBrakeApply 1 "Not_Applied" 3 "Faulty_SNA" 2 "Driver_applying_brakes" 0 "NotInit_orOff" ;
VAL_ 1297 RCM_a033_eventDriverBrakeApply 1 "Not_Applied" 3 "Faulty_SNA" 2 "Driver_applying_brakes" 0 "NotInit_orOff" ;
VAL_ 1297 RCM_a109_eventDriverBrakeApply 1 "Not_Applied" 3 "Faulty_SNA" 2 "Driver_applying_brakes" 0 "NotInit_orOff" ;
VAL_ 1297 RCM_a080_eventDriverBrakeApply 1 "Not_Applied" 3 "Faulty_SNA" 2 "Driver_applying_brakes" 0 "NotInit_orOff" ;
VAL_ 1297 RCM_a011_eventDriverBrakeApply 1 "Not_Applied" 3 "Faulty_SNA" 2 "Driver_applying_brakes" 0 "NotInit_orOff" ;
VAL_ 1297 RCM_a099_eventDriverBrakeApply 1 "Not_Applied" 3 "Faulty_SNA" 2 "Driver_applying_brakes" 0 "NotInit_orOff" ;
VAL_ 1297 RCM_a085_eventDriverBrakeApply 1 "Not_Applied" 3 "Faulty_SNA" 2 "Driver_applying_brakes" 0 "NotInit_orOff" ;
VAL_ 1297 RCM_a072_eventDriverBrakeApply 1 "Not_Applied" 3 "Faulty_SNA" 2 "Driver_applying_brakes" 0 "NotInit_orOff" ;
VAL_ 1297 RCM_a049_eventDriverBrakeApply 1 "Not_Applied" 3 "Faulty_SNA" 2 "Driver_applying_brakes" 0 "NotInit_orOff" ;
VAL_ 1297 RCM_a014_eventDriverBrakeApply 1 "Not_Applied" 3 "Faulty_SNA" 2 "Driver_applying_brakes" 0 "NotInit_orOff" ;
VAL_ 1297 RCM_a036_eventDriverBrakeApply 1 "Not_Applied" 3 "Faulty_SNA" 2 "Driver_applying_brakes" 0 "NotInit_orOff" ;
VAL_ 1297 RCM_a115_eventDriverBrakeApply 1 "Not_Applied" 3 "Faulty_SNA" 2 "Driver_applying_brakes" 0 "NotInit_orOff" ;
VAL_ 1297 RCM_a050_eventDriverBrakeApply 1 "Not_Applied" 3 "Faulty_SNA" 2 "Driver_applying_brakes" 0 "NotInit_orOff" ;
VAL_ 1297 RCM_a064_eventDriverBrakeApply 1 "Not_Applied" 3 "Faulty_SNA" 2 "Driver_applying_brakes" 0 "NotInit_orOff" ;
VAL_ 1297 RCM_a093_eventDriverBrakeApply 1 "Not_Applied" 3 "Faulty_SNA" 2 "Driver_applying_brakes" 0 "NotInit_orOff" ;
VAL_ 1297 RCM_a002_eventDriverBrakeApply 1 "Not_Applied" 3 "Faulty_SNA" 2 "Driver_applying_brakes" 0 "NotInit_orOff" ;
VAL_ 1297 RCM_a046_eventDriverBrakeApply 1 "Not_Applied" 3 "Faulty_SNA" 2 "Driver_applying_brakes" 0 "NotInit_orOff" ;
VAL_ 1297 RCM_a039_eventDriverBrakeApply 1 "Not_Applied" 3 "Faulty_SNA" 2 "Driver_applying_brakes" 0 "NotInit_orOff" ;
VAL_ 1297 RCM_a103_eventDriverBrakeApply 1 "Not_Applied" 3 "Faulty_SNA" 2 "Driver_applying_brakes" 0 "NotInit_orOff" ;
VAL_ 1297 RCM_a020_eventDriverBrakeApply 1 "Not_Applied" 3 "Faulty_SNA" 2 "Driver_applying_brakes" 0 "NotInit_orOff" ;
VAL_ 1297 RCM_a043_eventDriverBrakeApply 1 "Not_Applied" 3 "Faulty_SNA" 2 "Driver_applying_brakes" 0 "NotInit_orOff" ;
VAL_ 1297 RCM_a106_eventDriverBrakeApply 1 "Not_Applied" 3 "Faulty_SNA" 2 "Driver_applying_brakes" 0 "NotInit_orOff" ;
VAL_ 1297 RCM_a025_eventDriverBrakeApply 1 "Not_Applied" 3 "Faulty_SNA" 2 "Driver_applying_brakes" 0 "NotInit_orOff" ;
VAL_ 1297 RCM_a061_eventDriverBrakeApply 1 "Not_Applied" 3 "Faulty_SNA" 2 "Driver_applying_brakes" 0 "NotInit_orOff" ;
VAL_ 1297 RCM_a007_eventDriverBrakeApply 1 "Not_Applied" 3 "Faulty_SNA" 2 "Driver_applying_brakes" 0 "NotInit_orOff" ;
VAL_ 1297 RCM_a078_eventDriverBrakeApply 1 "Not_Applied" 3 "Faulty_SNA" 2 "Driver_applying_brakes" 0 "NotInit_orOff" ;
VAL_ 1297 RCM_a096_eventDriverBrakeApply 1 "Not_Applied" 3 "Faulty_SNA" 2 "Driver_applying_brakes" 0 "NotInit_orOff" ;
VAL_ 1297 RCM_a015_eventDriverBrakeApply 1 "Not_Applied" 3 "Faulty_SNA" 2 "Driver_applying_brakes" 0 "NotInit_orOff" ;
VAL_ 1297 RCM_a048_eventDriverBrakeApply 1 "Not_Applied" 3 "Faulty_SNA" 2 "Driver_applying_brakes" 0 "NotInit_orOff" ;
VAL_ 1297 RCM_a084_eventDriverBrakeApply 1 "Not_Applied" 3 "Faulty_SNA" 2 "Driver_applying_brakes" 0 "NotInit_orOff" ;
VAL_ 1297 RCM_a037_eventDriverBrakeApply 1 "Not_Applied" 3 "Faulty_SNA" 2 "Driver_applying_brakes" 0 "NotInit_orOff" ;
VAL_ 1297 RCM_a114_eventDriverBrakeApply 1 "Not_Applied" 3 "Faulty_SNA" 2 "Driver_applying_brakes" 0 "NotInit_orOff" ;
VAL_ 1297 RCM_a051_eventDriverBrakeApply 1 "Not_Applied" 3 "Faulty_SNA" 2 "Driver_applying_brakes" 0 "NotInit_orOff" ;
VAL_ 1297 RCM_a073_eventDriverBrakeApply 1 "Not_Applied" 3 "Faulty_SNA" 2 "Driver_applying_brakes" 0 "NotInit_orOff" ;
VAL_ 1297 RCM_a001_eventDriverBrakeApply 1 "Not_Applied" 3 "Faulty_SNA" 2 "Driver_applying_brakes" 0 "NotInit_orOff" ;
VAL_ 1297 RCM_a100_eventDriverBrakeApply 1 "Not_Applied" 3 "Faulty_SNA" 2 "Driver_applying_brakes" 0 "NotInit_orOff" ;
VAL_ 1297 RCM_a023_eventDriverBrakeApply 1 "Not_Applied" 3 "Faulty_SNA" 2 "Driver_applying_brakes" 0 "NotInit_orOff" ;
VAL_ 1297 RCM_a045_eventDriverBrakeApply 1 "Not_Applied" 3 "Faulty_SNA" 2 "Driver_applying_brakes" 0 "NotInit_orOff" ;
VAL_ 1297 RCM_a067_eventDriverBrakeApply 1 "Not_Applied" 3 "Faulty_SNA" 2 "Driver_applying_brakes" 0 "NotInit_orOff" ;
VAL_ 1297 RCM_a018_eventDriverBrakeApply 1 "Not_Applied" 3 "Faulty_SNA" 2 "Driver_applying_brakes" 0 "NotInit_orOff" ;
VAL_ 1297 RCM_a089_eventDriverBrakeApply 1 "Not_Applied" 3 "Faulty_SNA" 2 "Driver_applying_brakes" 0 "NotInit_orOff" ;
VAL_ 1297 RCM_a090_eventDriverBrakeApply 1 "Not_Applied" 3 "Faulty_SNA" 2 "Driver_applying_brakes" 0 "NotInit_orOff" ;
VAL_ 1297 RCM_a107_eventDriverBrakeApply 1 "Not_Applied" 3 "Faulty_SNA" 2 "Driver_applying_brakes" 0 "NotInit_orOff" ;
VAL_ 1297 RCM_a024_eventDriverBrakeApply 1 "Not_Applied" 3 "Faulty_SNA" 2 "Driver_applying_brakes" 0 "NotInit_orOff" ;
VAL_ 1297 RCM_a042_eventDriverBrakeApply 1 "Not_Applied" 3 "Faulty_SNA" 2 "Driver_applying_brakes" 0 "NotInit_orOff" ;
VAL_ 1297 RCM_a006_eventDriverBrakeApply 1 "Not_Applied" 3 "Faulty_SNA" 2 "Driver_applying_brakes" 0 "NotInit_orOff" ;
VAL_ 1297 RCM_a079_eventDriverBrakeApply 1 "Not_Applied" 3 "Faulty_SNA" 2 "Driver_applying_brakes" 0 "NotInit_orOff" ;
VAL_ 1297 RCM_a060_eventDriverBrakeApply 1 "Not_Applied" 3 "Faulty_SNA" 2 "Driver_applying_brakes" 0 "NotInit_orOff" ;
VAL_ 1297 RCM_a097_eventDriverBrakeApply 1 "Not_Applied" 3 "Faulty_SNA" 2 "Driver_applying_brakes" 0 "NotInit_orOff" ;
VAL_ 1297 RCM_a074_eventDriverBrakeApply 1 "Not_Applied" 3 "Faulty_SNA" 2 "Driver_applying_brakes" 0 "NotInit_orOff" ;
VAL_ 1297 RCM_a012_eventDriverBrakeApply 1 "Not_Applied" 3 "Faulty_SNA" 2 "Driver_applying_brakes" 0 "NotInit_orOff" ;
VAL_ 1297 RCM_a030_eventDriverBrakeApply 1 "Not_Applied" 3 "Faulty_SNA" 2 "Driver_applying_brakes" 0 "NotInit_orOff" ;
VAL_ 1297 RCM_a056_eventDriverBrakeApply 1 "Not_Applied" 3 "Faulty_SNA" 2 "Driver_applying_brakes" 0 "NotInit_orOff" ;
VAL_ 1297 RCM_a113_eventDriverBrakeApply 1 "Not_Applied" 3 "Faulty_SNA" 2 "Driver_applying_brakes" 0 "NotInit_orOff" ;
VAL_ 1297 RCM_a083_eventDriverBrakeApply 1 "Not_Applied" 3 "Faulty_SNA" 2 "Driver_applying_brakes" 0 "NotInit_orOff" ;
VAL_ 1297 RCM_a029_eventDriverBrakeApply 1 "Not_Applied" 3 "Faulty_SNA" 2 "Driver_applying_brakes" 0 "NotInit_orOff" ;
VAL_ 1297 RCM_a101_eventDriverBrakeApply 1 "Not_Applied" 3 "Faulty_SNA" 2 "Driver_applying_brakes" 0 "NotInit_orOff" ;
VAL_ 1297 RCM_a022_eventDriverBrakeApply 1 "Not_Applied" 3 "Faulty_SNA" 2 "Driver_applying_brakes" 0 "NotInit_orOff" ;
VAL_ 1297 RCM_a019_eventDriverBrakeApply 1 "Not_Applied" 3 "Faulty_SNA" 2 "Driver_applying_brakes" 0 "NotInit_orOff" ;
VAL_ 1297 RCM_a088_eventDriverBrakeApply 1 "Not_Applied" 3 "Faulty_SNA" 2 "Driver_applying_brakes" 0 "NotInit_orOff" ;
VAL_ 1297 RCM_a091_eventDriverBrakeApply 1 "Not_Applied" 3 "Faulty_SNA" 2 "Driver_applying_brakes" 0 "NotInit_orOff" ;
VAL_ 1297 RCM_a066_eventDriverBrakeApply 1 "Not_Applied" 3 "Faulty_SNA" 2 "Driver_applying_brakes" 0 "NotInit_orOff" ;
VAL_ 1297 RCM_a000_eventDriverBrakeApply 1 "Not_Applied" 3 "Faulty_SNA" 2 "Driver_applying_brakes" 0 "NotInit_orOff" ;
VAL_ 1297 RCM_a044_eventDriverBrakeApply 1 "Not_Applied" 3 "Faulty_SNA" 2 "Driver_applying_brakes" 0 "NotInit_orOff" ;
VAL_ 1297 RCM_a118_eventDriverBrakeApply 1 "Not_Applied" 3 "Faulty_SNA" 2 "Driver_applying_brakes" 0 "NotInit_orOff" ;
VAL_ 1297 RCM_a072_eventFrontRightSeatbelt 1 "SEAT_BELT_BUCKLE_STATUS_LATCHED" 0 "SEAT_BELT_BUCKLE_STATUS_UNLATCHED" ;
VAL_ 1297 RCM_a014_eventFrontRightSeatbelt 1 "SEAT_BELT_BUCKLE_STATUS_LATCHED" 0 "SEAT_BELT_BUCKLE_STATUS_UNLATCHED" ;
VAL_ 1297 RCM_a049_eventFrontRightSeatbelt 1 "SEAT_BELT_BUCKLE_STATUS_LATCHED" 0 "SEAT_BELT_BUCKLE_STATUS_UNLATCHED" ;
VAL_ 1297 RCM_a115_eventFrontRightSeatbelt 1 "SEAT_BELT_BUCKLE_STATUS_LATCHED" 0 "SEAT_BELT_BUCKLE_STATUS_UNLATCHED" ;
VAL_ 1297 RCM_a050_eventFrontRightSeatbelt 1 "SEAT_BELT_BUCKLE_STATUS_LATCHED" 0 "SEAT_BELT_BUCKLE_STATUS_UNLATCHED" ;
VAL_ 1297 RCM_a085_eventFrontRightSeatbelt 1 "SEAT_BELT_BUCKLE_STATUS_LATCHED" 0 "SEAT_BELT_BUCKLE_STATUS_UNLATCHED" ;
VAL_ 1297 RCM_a036_eventFrontRightSeatbelt 1 "SEAT_BELT_BUCKLE_STATUS_LATCHED" 0 "SEAT_BELT_BUCKLE_STATUS_UNLATCHED" ;
VAL_ 1297 RCM_a064_eventFrontRightSeatbelt 1 "SEAT_BELT_BUCKLE_STATUS_LATCHED" 0 "SEAT_BELT_BUCKLE_STATUS_UNLATCHED" ;
VAL_ 1297 RCM_a046_eventFrontRightSeatbelt 1 "SEAT_BELT_BUCKLE_STATUS_LATCHED" 0 "SEAT_BELT_BUCKLE_STATUS_UNLATCHED" ;
VAL_ 1297 RCM_a103_eventFrontRightSeatbelt 1 "SEAT_BELT_BUCKLE_STATUS_LATCHED" 0 "SEAT_BELT_BUCKLE_STATUS_UNLATCHED" ;
VAL_ 1297 RCM_a020_eventFrontRightSeatbelt 1 "SEAT_BELT_BUCKLE_STATUS_LATCHED" 0 "SEAT_BELT_BUCKLE_STATUS_UNLATCHED" ;
VAL_ 1297 RCM_a039_eventFrontRightSeatbelt 1 "SEAT_BELT_BUCKLE_STATUS_LATCHED" 0 "SEAT_BELT_BUCKLE_STATUS_UNLATCHED" ;
VAL_ 1297 RCM_a002_eventFrontRightSeatbelt 1 "SEAT_BELT_BUCKLE_STATUS_LATCHED" 0 "SEAT_BELT_BUCKLE_STATUS_UNLATCHED" ;
VAL_ 1297 RCM_a093_eventFrontRightSeatbelt 1 "SEAT_BELT_BUCKLE_STATUS_LATCHED" 0 "SEAT_BELT_BUCKLE_STATUS_UNLATCHED" ;
VAL_ 1297 RCM_a106_eventFrontRightSeatbelt 1 "SEAT_BELT_BUCKLE_STATUS_LATCHED" 0 "SEAT_BELT_BUCKLE_STATUS_UNLATCHED" ;
VAL_ 1297 RCM_a025_eventFrontRightSeatbelt 1 "SEAT_BELT_BUCKLE_STATUS_LATCHED" 0 "SEAT_BELT_BUCKLE_STATUS_UNLATCHED" ;
VAL_ 1297 RCM_a061_eventFrontRightSeatbelt 1 "SEAT_BELT_BUCKLE_STATUS_LATCHED" 0 "SEAT_BELT_BUCKLE_STATUS_UNLATCHED" ;
VAL_ 1297 RCM_a096_eventFrontRightSeatbelt 1 "SEAT_BELT_BUCKLE_STATUS_LATCHED" 0 "SEAT_BELT_BUCKLE_STATUS_UNLATCHED" ;
VAL_ 1297 RCM_a078_eventFrontRightSeatbelt 1 "SEAT_BELT_BUCKLE_STATUS_LATCHED" 0 "SEAT_BELT_BUCKLE_STATUS_UNLATCHED" ;
VAL_ 1297 RCM_a007_eventFrontRightSeatbelt 1 "SEAT_BELT_BUCKLE_STATUS_LATCHED" 0 "SEAT_BELT_BUCKLE_STATUS_UNLATCHED" ;
VAL_ 1297 RCM_a043_eventFrontRightSeatbelt 1 "SEAT_BELT_BUCKLE_STATUS_LATCHED" 0 "SEAT_BELT_BUCKLE_STATUS_UNLATCHED" ;
VAL_ 1297 RCM_a073_eventFrontRightSeatbelt 1 "SEAT_BELT_BUCKLE_STATUS_LATCHED" 0 "SEAT_BELT_BUCKLE_STATUS_UNLATCHED" ;
VAL_ 1297 RCM_a015_eventFrontRightSeatbelt 1 "SEAT_BELT_BUCKLE_STATUS_LATCHED" 0 "SEAT_BELT_BUCKLE_STATUS_UNLATCHED" ;
VAL_ 1297 RCM_a048_eventFrontRightSeatbelt 1 "SEAT_BELT_BUCKLE_STATUS_LATCHED" 0 "SEAT_BELT_BUCKLE_STATUS_UNLATCHED" ;
VAL_ 1297 RCM_a114_eventFrontRightSeatbelt 1 "SEAT_BELT_BUCKLE_STATUS_LATCHED" 0 "SEAT_BELT_BUCKLE_STATUS_UNLATCHED" ;
VAL_ 1297 RCM_a051_eventFrontRightSeatbelt 1 "SEAT_BELT_BUCKLE_STATUS_LATCHED" 0 "SEAT_BELT_BUCKLE_STATUS_UNLATCHED" ;
VAL_ 1297 RCM_a084_eventFrontRightSeatbelt 1 "SEAT_BELT_BUCKLE_STATUS_LATCHED" 0 "SEAT_BELT_BUCKLE_STATUS_UNLATCHED" ;
VAL_ 1297 RCM_a037_eventFrontRightSeatbelt 1 "SEAT_BELT_BUCKLE_STATUS_LATCHED" 0 "SEAT_BELT_BUCKLE_STATUS_UNLATCHED" ;
VAL_ 1297 RCM_a067_eventFrontRightSeatbelt 1 "SEAT_BELT_BUCKLE_STATUS_LATCHED" 0 "SEAT_BELT_BUCKLE_STATUS_UNLATCHED" ;
VAL_ 1297 RCM_a089_eventFrontRightSeatbelt 1 "SEAT_BELT_BUCKLE_STATUS_LATCHED" 0 "SEAT_BELT_BUCKLE_STATUS_UNLATCHED" ;
VAL_ 1297 RCM_a100_eventFrontRightSeatbelt 1 "SEAT_BELT_BUCKLE_STATUS_LATCHED" 0 "SEAT_BELT_BUCKLE_STATUS_UNLATCHED" ;
VAL_ 1297 RCM_a023_eventFrontRightSeatbelt 1 "SEAT_BELT_BUCKLE_STATUS_LATCHED" 0 "SEAT_BELT_BUCKLE_STATUS_UNLATCHED" ;
VAL_ 1297 RCM_a090_eventFrontRightSeatbelt 1 "SEAT_BELT_BUCKLE_STATUS_LATCHED" 0 "SEAT_BELT_BUCKLE_STATUS_UNLATCHED" ;
VAL_ 1297 RCM_a001_eventFrontRightSeatbelt 1 "SEAT_BELT_BUCKLE_STATUS_LATCHED" 0 "SEAT_BELT_BUCKLE_STATUS_UNLATCHED" ;
VAL_ 1297 RCM_a018_eventFrontRightSeatbelt 1 "SEAT_BELT_BUCKLE_STATUS_LATCHED" 0 "SEAT_BELT_BUCKLE_STATUS_UNLATCHED" ;
VAL_ 1297 RCM_a045_eventFrontRightSeatbelt 1 "SEAT_BELT_BUCKLE_STATUS_LATCHED" 0 "SEAT_BELT_BUCKLE_STATUS_UNLATCHED" ;
VAL_ 1297 RCM_a107_eventFrontRightSeatbelt 1 "SEAT_BELT_BUCKLE_STATUS_LATCHED" 0 "SEAT_BELT_BUCKLE_STATUS_UNLATCHED" ;
VAL_ 1297 RCM_a024_eventFrontRightSeatbelt 1 "SEAT_BELT_BUCKLE_STATUS_LATCHED" 0 "SEAT_BELT_BUCKLE_STATUS_UNLATCHED" ;
VAL_ 1297 RCM_a097_eventFrontRightSeatbelt 1 "SEAT_BELT_BUCKLE_STATUS_LATCHED" 0 "SEAT_BELT_BUCKLE_STATUS_UNLATCHED" ;
VAL_ 1297 RCM_a060_eventFrontRightSeatbelt 1 "SEAT_BELT_BUCKLE_STATUS_LATCHED" 0 "SEAT_BELT_BUCKLE_STATUS_UNLATCHED" ;
VAL_ 1297 RCM_a006_eventFrontRightSeatbelt 1 "SEAT_BELT_BUCKLE_STATUS_LATCHED" 0 "SEAT_BELT_BUCKLE_STATUS_UNLATCHED" ;
VAL_ 1297 RCM_a079_eventFrontRightSeatbelt 1 "SEAT_BELT_BUCKLE_STATUS_LATCHED" 0 "SEAT_BELT_BUCKLE_STATUS_UNLATCHED" ;
VAL_ 1297 RCM_a042_eventFrontRightSeatbelt 1 "SEAT_BELT_BUCKLE_STATUS_LATCHED" 0 "SEAT_BELT_BUCKLE_STATUS_UNLATCHED" ;
VAL_ 1297 RCM_a113_eventFrontRightSeatbelt 1 "SEAT_BELT_BUCKLE_STATUS_LATCHED" 0 "SEAT_BELT_BUCKLE_STATUS_UNLATCHED" ;
VAL_ 1297 RCM_a056_eventFrontRightSeatbelt 1 "SEAT_BELT_BUCKLE_STATUS_LATCHED" 0 "SEAT_BELT_BUCKLE_STATUS_UNLATCHED" ;
VAL_ 1297 RCM_a074_eventFrontRightSeatbelt 1 "SEAT_BELT_BUCKLE_STATUS_LATCHED" 0 "SEAT_BELT_BUCKLE_STATUS_UNLATCHED" ;
VAL_ 1297 RCM_a029_eventFrontRightSeatbelt 1 "SEAT_BELT_BUCKLE_STATUS_LATCHED" 0 "SEAT_BELT_BUCKLE_STATUS_UNLATCHED" ;
VAL_ 1297 RCM_a012_eventFrontRightSeatbelt 1 "SEAT_BELT_BUCKLE_STATUS_LATCHED" 0 "SEAT_BELT_BUCKLE_STATUS_UNLATCHED" ;
VAL_ 1297 RCM_a083_eventFrontRightSeatbelt 1 "SEAT_BELT_BUCKLE_STATUS_LATCHED" 0 "SEAT_BELT_BUCKLE_STATUS_UNLATCHED" ;
VAL_ 1297 RCM_a030_eventFrontRightSeatbelt 1 "SEAT_BELT_BUCKLE_STATUS_LATCHED" 0 "SEAT_BELT_BUCKLE_STATUS_UNLATCHED" ;
VAL_ 1297 RCM_a066_eventFrontRightSeatbelt 1 "SEAT_BELT_BUCKLE_STATUS_LATCHED" 0 "SEAT_BELT_BUCKLE_STATUS_UNLATCHED" ;
VAL_ 1297 RCM_a019_eventFrontRightSeatbelt 1 "SEAT_BELT_BUCKLE_STATUS_LATCHED" 0 "SEAT_BELT_BUCKLE_STATUS_UNLATCHED" ;
VAL_ 1297 RCM_a091_eventFrontRightSeatbelt 1 "SEAT_BELT_BUCKLE_STATUS_LATCHED" 0 "SEAT_BELT_BUCKLE_STATUS_UNLATCHED" ;
VAL_ 1297 RCM_a118_eventFrontRightSeatbelt 1 "SEAT_BELT_BUCKLE_STATUS_LATCHED" 0 "SEAT_BELT_BUCKLE_STATUS_UNLATCHED" ;
VAL_ 1297 RCM_a044_eventFrontRightSeatbelt 1 "SEAT_BELT_BUCKLE_STATUS_LATCHED" 0 "SEAT_BELT_BUCKLE_STATUS_UNLATCHED" ;
VAL_ 1297 RCM_a088_eventFrontRightSeatbelt 1 "SEAT_BELT_BUCKLE_STATUS_LATCHED" 0 "SEAT_BELT_BUCKLE_STATUS_UNLATCHED" ;
VAL_ 1297 RCM_a000_eventFrontRightSeatbelt 1 "SEAT_BELT_BUCKLE_STATUS_LATCHED" 0 "SEAT_BELT_BUCKLE_STATUS_UNLATCHED" ;
VAL_ 1297 RCM_a101_eventFrontRightSeatbelt 1 "SEAT_BELT_BUCKLE_STATUS_LATCHED" 0 "SEAT_BELT_BUCKLE_STATUS_UNLATCHED" ;
VAL_ 1297 RCM_a022_eventFrontRightSeatbelt 1 "SEAT_BELT_BUCKLE_STATUS_LATCHED" 0 "SEAT_BELT_BUCKLE_STATUS_UNLATCHED" ;
VAL_ 1297 RCM_a094_eventFrontRightSeatbelt 1 "SEAT_BELT_BUCKLE_STATUS_LATCHED" 0 "SEAT_BELT_BUCKLE_STATUS_UNLATCHED" ;
VAL_ 1297 RCM_a041_eventFrontRightSeatbelt 1 "SEAT_BELT_BUCKLE_STATUS_LATCHED" 0 "SEAT_BELT_BUCKLE_STATUS_UNLATCHED" ;
VAL_ 1297 RCM_a027_eventFrontRightSeatbelt 1 "SEAT_BELT_BUCKLE_STATUS_LATCHED" 0 "SEAT_BELT_BUCKLE_STATUS_UNLATCHED" ;
VAL_ 1297 RCM_a104_eventFrontRightSeatbelt 1 "SEAT_BELT_BUCKLE_STATUS_LATCHED" 0 "SEAT_BELT_BUCKLE_STATUS_UNLATCHED" ;
VAL_ 1297 RCM_a063_eventFrontRightSeatbelt 1 "SEAT_BELT_BUCKLE_STATUS_LATCHED" 0 "SEAT_BELT_BUCKLE_STATUS_UNLATCHED" ;
VAL_ 1297 RCM_a005_eventFrontRightSeatbelt 1 "SEAT_BELT_BUCKLE_STATUS_LATCHED" 0 "SEAT_BELT_BUCKLE_STATUS_UNLATCHED" ;
VAL_ 1297 RCM_a058_eventFrontRightSeatbelt 1 "SEAT_BELT_BUCKLE_STATUS_LATCHED" 0 "SEAT_BELT_BUCKLE_STATUS_UNLATCHED" ;
VAL_ 1297 RCM_a028_eventFrontRightSeatbelt 1 "SEAT_BELT_BUCKLE_STATUS_LATCHED" 0 "SEAT_BELT_BUCKLE_STATUS_UNLATCHED" ;
VAL_ 1297 RCM_a082_eventFrontRightSeatbelt 1 "SEAT_BELT_BUCKLE_STATUS_LATCHED" 0 "SEAT_BELT_BUCKLE_STATUS_UNLATCHED" ;
VAL_ 1297 RCM_a013_eventFrontRightSeatbelt 1 "SEAT_BELT_BUCKLE_STATUS_LATCHED" 0 "SEAT_BELT_BUCKLE_STATUS_UNLATCHED" ;
VAL_ 1297 RCM_a031_eventFrontRightSeatbelt 1 "SEAT_BELT_BUCKLE_STATUS_LATCHED" 0 "SEAT_BELT_BUCKLE_STATUS_UNLATCHED" ;
VAL_ 1297 RCM_a112_eventFrontRightSeatbelt 1 "SEAT_BELT_BUCKLE_STATUS_LATCHED" 0 "SEAT_BELT_BUCKLE_STATUS_UNLATCHED" ;
VAL_ 1297 RCM_a057_eventFrontRightSeatbelt 1 "SEAT_BELT_BUCKLE_STATUS_LATCHED" 0 "SEAT_BELT_BUCKLE_STATUS_UNLATCHED" ;
VAL_ 1297 RCM_a075_eventFrontRightSeatbelt 1 "SEAT_BELT_BUCKLE_STATUS_LATCHED" 0 "SEAT_BELT_BUCKLE_STATUS_UNLATCHED" ;
VAL_ 1297 RCM_a087_eventFrontRightSeatbelt 1 "SEAT_BELT_BUCKLE_STATUS_LATCHED" 0 "SEAT_BELT_BUCKLE_STATUS_UNLATCHED" ;
VAL_ 1297 RCM_a016_eventFrontRightSeatbelt 1 "SEAT_BELT_BUCKLE_STATUS_LATCHED" 0 "SEAT_BELT_BUCKLE_STATUS_UNLATCHED" ;
VAL_ 1297 RCM_a117_eventFrontRightSeatbelt 1 "SEAT_BELT_BUCKLE_STATUS_LATCHED" 0 "SEAT_BELT_BUCKLE_STATUS_UNLATCHED" ;
VAL_ 1297 RCM_a052_eventFrontRightSeatbelt 1 "SEAT_BELT_BUCKLE_STATUS_LATCHED" 0 "SEAT_BELT_BUCKLE_STATUS_UNLATCHED" ;
VAL_ 1297 RCM_a070_eventFrontRightSeatbelt 1 "SEAT_BELT_BUCKLE_STATUS_LATCHED" 0 "SEAT_BELT_BUCKLE_STATUS_UNLATCHED" ;
VAL_ 1297 RCM_a034_eventFrontRightSeatbelt 1 "SEAT_BELT_BUCKLE_STATUS_LATCHED" 0 "SEAT_BELT_BUCKLE_STATUS_UNLATCHED" ;
VAL_ 1297 RCM_a069_eventFrontRightSeatbelt 1 "SEAT_BELT_BUCKLE_STATUS_LATCHED" 0 "SEAT_BELT_BUCKLE_STATUS_UNLATCHED" ;
VAL_ 1297 RCM_a004_eventFrontRightSeatbelt 1 "SEAT_BELT_BUCKLE_STATUS_LATCHED" 0 "SEAT_BELT_BUCKLE_STATUS_UNLATCHED" ;
VAL_ 1297 RCM_a040_eventFrontRightSeatbelt 1 "SEAT_BELT_BUCKLE_STATUS_LATCHED" 0 "SEAT_BELT_BUCKLE_STATUS_UNLATCHED" ;
VAL_ 1297 RCM_a062_eventFrontRightSeatbelt 1 "SEAT_BELT_BUCKLE_STATUS_LATCHED" 0 "SEAT_BELT_BUCKLE_STATUS_UNLATCHED" ;
VAL_ 1297 RCM_a059_eventFrontRightSeatbelt 1 "SEAT_BELT_BUCKLE_STATUS_LATCHED" 0 "SEAT_BELT_BUCKLE_STATUS_UNLATCHED" ;
VAL_ 1297 RCM_a105_eventFrontRightSeatbelt 1 "SEAT_BELT_BUCKLE_STATUS_LATCHED" 0 "SEAT_BELT_BUCKLE_STATUS_UNLATCHED" ;
VAL_ 1297 RCM_a026_eventFrontRightSeatbelt 1 "SEAT_BELT_BUCKLE_STATUS_LATCHED" 0 "SEAT_BELT_BUCKLE_STATUS_UNLATCHED" ;
VAL_ 1297 RCM_a095_eventFrontRightSeatbelt 1 "SEAT_BELT_BUCKLE_STATUS_LATCHED" 0 "SEAT_BELT_BUCKLE_STATUS_UNLATCHED" ;
VAL_ 1297 RCM_a081_eventFrontRightSeatbelt 1 "SEAT_BELT_BUCKLE_STATUS_LATCHED" 0 "SEAT_BELT_BUCKLE_STATUS_UNLATCHED" ;
VAL_ 1297 RCM_a098_eventFrontRightSeatbelt 1 "SEAT_BELT_BUCKLE_STATUS_LATCHED" 0 "SEAT_BELT_BUCKLE_STATUS_UNLATCHED" ;
VAL_ 1297 RCM_a076_eventFrontRightSeatbelt 1 "SEAT_BELT_BUCKLE_STATUS_LATCHED" 0 "SEAT_BELT_BUCKLE_STATUS_UNLATCHED" ;
VAL_ 1297 RCM_a009_eventFrontRightSeatbelt 1 "SEAT_BELT_BUCKLE_STATUS_LATCHED" 0 "SEAT_BELT_BUCKLE_STATUS_UNLATCHED" ;
VAL_ 1297 RCM_a111_eventFrontRightSeatbelt 1 "SEAT_BELT_BUCKLE_STATUS_LATCHED" 0 "SEAT_BELT_BUCKLE_STATUS_UNLATCHED" ;
VAL_ 1297 RCM_a054_eventFrontRightSeatbelt 1 "SEAT_BELT_BUCKLE_STATUS_LATCHED" 0 "SEAT_BELT_BUCKLE_STATUS_UNLATCHED" ;
VAL_ 1297 RCM_a108_eventFrontRightSeatbelt 1 "SEAT_BELT_BUCKLE_STATUS_LATCHED" 0 "SEAT_BELT_BUCKLE_STATUS_UNLATCHED" ;
VAL_ 1297 RCM_a032_eventFrontRightSeatbelt 1 "SEAT_BELT_BUCKLE_STATUS_LATCHED" 0 "SEAT_BELT_BUCKLE_STATUS_UNLATCHED" ;
VAL_ 1297 RCM_a010_eventFrontRightSeatbelt 1 "SEAT_BELT_BUCKLE_STATUS_LATCHED" 0 "SEAT_BELT_BUCKLE_STATUS_UNLATCHED" ;
VAL_ 1297 RCM_a068_eventFrontRightSeatbelt 1 "SEAT_BELT_BUCKLE_STATUS_LATCHED" 0 "SEAT_BELT_BUCKLE_STATUS_UNLATCHED" ;
VAL_ 1297 RCM_a086_eventFrontRightSeatbelt 1 "SEAT_BELT_BUCKLE_STATUS_LATCHED" 0 "SEAT_BELT_BUCKLE_STATUS_UNLATCHED" ;
VAL_ 1297 RCM_a116_eventFrontRightSeatbelt 1 "SEAT_BELT_BUCKLE_STATUS_LATCHED" 0 "SEAT_BELT_BUCKLE_STATUS_UNLATCHED" ;
VAL_ 1297 RCM_a053_eventFrontRightSeatbelt 1 "SEAT_BELT_BUCKLE_STATUS_LATCHED" 0 "SEAT_BELT_BUCKLE_STATUS_UNLATCHED" ;
VAL_ 1297 RCM_a071_eventFrontRightSeatbelt 1 "SEAT_BELT_BUCKLE_STATUS_LATCHED" 0 "SEAT_BELT_BUCKLE_STATUS_UNLATCHED" ;
VAL_ 1297 RCM_a017_eventFrontRightSeatbelt 1 "SEAT_BELT_BUCKLE_STATUS_LATCHED" 0 "SEAT_BELT_BUCKLE_STATUS_UNLATCHED" ;
VAL_ 1297 RCM_a035_eventFrontRightSeatbelt 1 "SEAT_BELT_BUCKLE_STATUS_LATCHED" 0 "SEAT_BELT_BUCKLE_STATUS_UNLATCHED" ;
VAL_ 1297 RCM_a092_eventFrontRightSeatbelt 1 "SEAT_BELT_BUCKLE_STATUS_LATCHED" 0 "SEAT_BELT_BUCKLE_STATUS_UNLATCHED" ;
VAL_ 1297 RCM_a047_eventFrontRightSeatbelt 1 "SEAT_BELT_BUCKLE_STATUS_LATCHED" 0 "SEAT_BELT_BUCKLE_STATUS_UNLATCHED" ;
VAL_ 1297 RCM_a065_eventFrontRightSeatbelt 1 "SEAT_BELT_BUCKLE_STATUS_LATCHED" 0 "SEAT_BELT_BUCKLE_STATUS_UNLATCHED" ;
VAL_ 1297 RCM_a038_eventFrontRightSeatbelt 1 "SEAT_BELT_BUCKLE_STATUS_LATCHED" 0 "SEAT_BELT_BUCKLE_STATUS_UNLATCHED" ;
VAL_ 1297 RCM_a003_eventFrontRightSeatbelt 1 "SEAT_BELT_BUCKLE_STATUS_LATCHED" 0 "SEAT_BELT_BUCKLE_STATUS_UNLATCHED" ;
VAL_ 1297 RCM_a102_eventFrontRightSeatbelt 1 "SEAT_BELT_BUCKLE_STATUS_LATCHED" 0 "SEAT_BELT_BUCKLE_STATUS_UNLATCHED" ;
VAL_ 1297 RCM_a021_eventFrontRightSeatbelt 1 "SEAT_BELT_BUCKLE_STATUS_LATCHED" 0 "SEAT_BELT_BUCKLE_STATUS_UNLATCHED" ;
VAL_ 1297 RCM_a110_eventFrontRightSeatbelt 1 "SEAT_BELT_BUCKLE_STATUS_LATCHED" 0 "SEAT_BELT_BUCKLE_STATUS_UNLATCHED" ;
VAL_ 1297 RCM_a055_eventFrontRightSeatbelt 1 "SEAT_BELT_BUCKLE_STATUS_LATCHED" 0 "SEAT_BELT_BUCKLE_STATUS_UNLATCHED" ;
VAL_ 1297 RCM_a033_eventFrontRightSeatbelt 1 "SEAT_BELT_BUCKLE_STATUS_LATCHED" 0 "SEAT_BELT_BUCKLE_STATUS_UNLATCHED" ;
VAL_ 1297 RCM_a080_eventFrontRightSeatbelt 1 "SEAT_BELT_BUCKLE_STATUS_LATCHED" 0 "SEAT_BELT_BUCKLE_STATUS_UNLATCHED" ;
VAL_ 1297 RCM_a109_eventFrontRightSeatbelt 1 "SEAT_BELT_BUCKLE_STATUS_LATCHED" 0 "SEAT_BELT_BUCKLE_STATUS_UNLATCHED" ;
VAL_ 1297 RCM_a099_eventFrontRightSeatbelt 1 "SEAT_BELT_BUCKLE_STATUS_LATCHED" 0 "SEAT_BELT_BUCKLE_STATUS_UNLATCHED" ;
VAL_ 1297 RCM_a008_eventFrontRightSeatbelt 1 "SEAT_BELT_BUCKLE_STATUS_LATCHED" 0 "SEAT_BELT_BUCKLE_STATUS_UNLATCHED" ;
VAL_ 1297 RCM_a077_eventFrontRightSeatbelt 1 "SEAT_BELT_BUCKLE_STATUS_LATCHED" 0 "SEAT_BELT_BUCKLE_STATUS_UNLATCHED" ;
VAL_ 1297 RCM_a011_eventFrontRightSeatbelt 1 "SEAT_BELT_BUCKLE_STATUS_LATCHED" 0 "SEAT_BELT_BUCKLE_STATUS_UNLATCHED" ;
VAL_ 1297 RCM_a071_eventFrontLeftSeatbelt 1 "SEAT_BELT_BUCKLE_STATUS_LATCHED" 0 "SEAT_BELT_BUCKLE_STATUS_UNLATCHED" ;
VAL_ 1297 RCM_a053_eventFrontLeftSeatbelt 1 "SEAT_BELT_BUCKLE_STATUS_LATCHED" 0 "SEAT_BELT_BUCKLE_STATUS_UNLATCHED" ;
VAL_ 1297 RCM_a116_eventFrontLeftSeatbelt 1 "SEAT_BELT_BUCKLE_STATUS_LATCHED" 0 "SEAT_BELT_BUCKLE_STATUS_UNLATCHED" ;
VAL_ 1297 RCM_a086_eventFrontLeftSeatbelt 1 "SEAT_BELT_BUCKLE_STATUS_LATCHED" 0 "SEAT_BELT_BUCKLE_STATUS_UNLATCHED" ;
VAL_ 1297 RCM_a068_eventFrontLeftSeatbelt 1 "SEAT_BELT_BUCKLE_STATUS_LATCHED" 0 "SEAT_BELT_BUCKLE_STATUS_UNLATCHED" ;
VAL_ 1297 RCM_a035_eventFrontLeftSeatbelt 1 "SEAT_BELT_BUCKLE_STATUS_LATCHED" 0 "SEAT_BELT_BUCKLE_STATUS_UNLATCHED" ;
VAL_ 1297 RCM_a017_eventFrontLeftSeatbelt 1 "SEAT_BELT_BUCKLE_STATUS_LATCHED" 0 "SEAT_BELT_BUCKLE_STATUS_UNLATCHED" ;
VAL_ 1297 RCM_a010_eventFrontLeftSeatbelt 1 "SEAT_BELT_BUCKLE_STATUS_LATCHED" 0 "SEAT_BELT_BUCKLE_STATUS_UNLATCHED" ;
VAL_ 1297 RCM_a081_eventFrontLeftSeatbelt 1 "SEAT_BELT_BUCKLE_STATUS_LATCHED" 0 "SEAT_BELT_BUCKLE_STATUS_UNLATCHED" ;
VAL_ 1297 RCM_a108_eventFrontLeftSeatbelt 1 "SEAT_BELT_BUCKLE_STATUS_LATCHED" 0 "SEAT_BELT_BUCKLE_STATUS_UNLATCHED" ;
VAL_ 1297 RCM_a098_eventFrontLeftSeatbelt 1 "SEAT_BELT_BUCKLE_STATUS_LATCHED" 0 "SEAT_BELT_BUCKLE_STATUS_UNLATCHED" ;
VAL_ 1297 RCM_a076_eventFrontLeftSeatbelt 1 "SEAT_BELT_BUCKLE_STATUS_LATCHED" 0 "SEAT_BELT_BUCKLE_STATUS_UNLATCHED" ;
VAL_ 1297 RCM_a009_eventFrontLeftSeatbelt 1 "SEAT_BELT_BUCKLE_STATUS_LATCHED" 0 "SEAT_BELT_BUCKLE_STATUS_UNLATCHED" ;
VAL_ 1297 RCM_a111_eventFrontLeftSeatbelt 1 "SEAT_BELT_BUCKLE_STATUS_LATCHED" 0 "SEAT_BELT_BUCKLE_STATUS_UNLATCHED" ;
VAL_ 1297 RCM_a054_eventFrontLeftSeatbelt 1 "SEAT_BELT_BUCKLE_STATUS_LATCHED" 0 "SEAT_BELT_BUCKLE_STATUS_UNLATCHED" ;
VAL_ 1297 RCM_a032_eventFrontLeftSeatbelt 1 "SEAT_BELT_BUCKLE_STATUS_LATCHED" 0 "SEAT_BELT_BUCKLE_STATUS_UNLATCHED" ;
VAL_ 1297 RCM_a095_eventFrontLeftSeatbelt 1 "SEAT_BELT_BUCKLE_STATUS_LATCHED" 0 "SEAT_BELT_BUCKLE_STATUS_UNLATCHED" ;
VAL_ 1297 RCM_a026_eventFrontLeftSeatbelt 1 "SEAT_BELT_BUCKLE_STATUS_LATCHED" 0 "SEAT_BELT_BUCKLE_STATUS_UNLATCHED" ;
VAL_ 1297 RCM_a105_eventFrontLeftSeatbelt 1 "SEAT_BELT_BUCKLE_STATUS_LATCHED" 0 "SEAT_BELT_BUCKLE_STATUS_UNLATCHED" ;
VAL_ 1297 RCM_a004_eventFrontLeftSeatbelt 1 "SEAT_BELT_BUCKLE_STATUS_LATCHED" 0 "SEAT_BELT_BUCKLE_STATUS_UNLATCHED" ;
VAL_ 1297 RCM_a059_eventFrontLeftSeatbelt 1 "SEAT_BELT_BUCKLE_STATUS_LATCHED" 0 "SEAT_BELT_BUCKLE_STATUS_UNLATCHED" ;
VAL_ 1297 RCM_a062_eventFrontLeftSeatbelt 1 "SEAT_BELT_BUCKLE_STATUS_LATCHED" 0 "SEAT_BELT_BUCKLE_STATUS_UNLATCHED" ;
VAL_ 1297 RCM_a040_eventFrontLeftSeatbelt 1 "SEAT_BELT_BUCKLE_STATUS_LATCHED" 0 "SEAT_BELT_BUCKLE_STATUS_UNLATCHED" ;
VAL_ 1297 RCM_a096_eventFrontLeftSeatbelt 1 "SEAT_BELT_BUCKLE_STATUS_LATCHED" 0 "SEAT_BELT_BUCKLE_STATUS_UNLATCHED" ;
VAL_ 1297 RCM_a061_eventFrontLeftSeatbelt 1 "SEAT_BELT_BUCKLE_STATUS_LATCHED" 0 "SEAT_BELT_BUCKLE_STATUS_UNLATCHED" ;
VAL_ 1297 RCM_a043_eventFrontLeftSeatbelt 1 "SEAT_BELT_BUCKLE_STATUS_LATCHED" 0 "SEAT_BELT_BUCKLE_STATUS_UNLATCHED" ;
VAL_ 1297 RCM_a106_eventFrontLeftSeatbelt 1 "SEAT_BELT_BUCKLE_STATUS_LATCHED" 0 "SEAT_BELT_BUCKLE_STATUS_UNLATCHED" ;
VAL_ 1297 RCM_a025_eventFrontLeftSeatbelt 1 "SEAT_BELT_BUCKLE_STATUS_LATCHED" 0 "SEAT_BELT_BUCKLE_STATUS_UNLATCHED" ;
VAL_ 1297 RCM_a007_eventFrontLeftSeatbelt 1 "SEAT_BELT_BUCKLE_STATUS_LATCHED" 0 "SEAT_BELT_BUCKLE_STATUS_UNLATCHED" ;
VAL_ 1297 RCM_a078_eventFrontLeftSeatbelt 1 "SEAT_BELT_BUCKLE_STATUS_LATCHED" 0 "SEAT_BELT_BUCKLE_STATUS_UNLATCHED" ;
VAL_ 1297 RCM_a046_eventFrontLeftSeatbelt 1 "SEAT_BELT_BUCKLE_STATUS_LATCHED" 0 "SEAT_BELT_BUCKLE_STATUS_UNLATCHED" ;
VAL_ 1297 RCM_a002_eventFrontLeftSeatbelt 1 "SEAT_BELT_BUCKLE_STATUS_LATCHED" 0 "SEAT_BELT_BUCKLE_STATUS_UNLATCHED" ;
VAL_ 1297 RCM_a093_eventFrontLeftSeatbelt 1 "SEAT_BELT_BUCKLE_STATUS_LATCHED" 0 "SEAT_BELT_BUCKLE_STATUS_UNLATCHED" ;
VAL_ 1297 RCM_a064_eventFrontLeftSeatbelt 1 "SEAT_BELT_BUCKLE_STATUS_LATCHED" 0 "SEAT_BELT_BUCKLE_STATUS_UNLATCHED" ;
VAL_ 1297 RCM_a020_eventFrontLeftSeatbelt 1 "SEAT_BELT_BUCKLE_STATUS_LATCHED" 0 "SEAT_BELT_BUCKLE_STATUS_UNLATCHED" ;
VAL_ 1297 RCM_a103_eventFrontLeftSeatbelt 1 "SEAT_BELT_BUCKLE_STATUS_LATCHED" 0 "SEAT_BELT_BUCKLE_STATUS_UNLATCHED" ;
VAL_ 1297 RCM_a039_eventFrontLeftSeatbelt 1 "SEAT_BELT_BUCKLE_STATUS_LATCHED" 0 "SEAT_BELT_BUCKLE_STATUS_UNLATCHED" ;
VAL_ 1297 RCM_a036_eventFrontLeftSeatbelt 1 "SEAT_BELT_BUCKLE_STATUS_LATCHED" 0 "SEAT_BELT_BUCKLE_STATUS_UNLATCHED" ;
VAL_ 1297 RCM_a085_eventFrontLeftSeatbelt 1 "SEAT_BELT_BUCKLE_STATUS_LATCHED" 0 "SEAT_BELT_BUCKLE_STATUS_UNLATCHED" ;
VAL_ 1297 RCM_a049_eventFrontLeftSeatbelt 1 "SEAT_BELT_BUCKLE_STATUS_LATCHED" 0 "SEAT_BELT_BUCKLE_STATUS_UNLATCHED" ;
VAL_ 1297 RCM_a050_eventFrontLeftSeatbelt 1 "SEAT_BELT_BUCKLE_STATUS_LATCHED" 0 "SEAT_BELT_BUCKLE_STATUS_UNLATCHED" ;
VAL_ 1297 RCM_a115_eventFrontLeftSeatbelt 1 "SEAT_BELT_BUCKLE_STATUS_LATCHED" 0 "SEAT_BELT_BUCKLE_STATUS_UNLATCHED" ;
VAL_ 1297 RCM_a014_eventFrontLeftSeatbelt 1 "SEAT_BELT_BUCKLE_STATUS_LATCHED" 0 "SEAT_BELT_BUCKLE_STATUS_UNLATCHED" ;
VAL_ 1297 RCM_a072_eventFrontLeftSeatbelt 1 "SEAT_BELT_BUCKLE_STATUS_LATCHED" 0 "SEAT_BELT_BUCKLE_STATUS_UNLATCHED" ;
VAL_ 1297 RCM_a077_eventFrontLeftSeatbelt 1 "SEAT_BELT_BUCKLE_STATUS_LATCHED" 0 "SEAT_BELT_BUCKLE_STATUS_UNLATCHED" ;
VAL_ 1297 RCM_a008_eventFrontLeftSeatbelt 1 "SEAT_BELT_BUCKLE_STATUS_LATCHED" 0 "SEAT_BELT_BUCKLE_STATUS_UNLATCHED" ;
VAL_ 1297 RCM_a110_eventFrontLeftSeatbelt 1 "SEAT_BELT_BUCKLE_STATUS_LATCHED" 0 "SEAT_BELT_BUCKLE_STATUS_UNLATCHED" ;
VAL_ 1297 RCM_a055_eventFrontLeftSeatbelt 1 "SEAT_BELT_BUCKLE_STATUS_LATCHED" 0 "SEAT_BELT_BUCKLE_STATUS_UNLATCHED" ;
VAL_ 1297 RCM_a033_eventFrontLeftSeatbelt 1 "SEAT_BELT_BUCKLE_STATUS_LATCHED" 0 "SEAT_BELT_BUCKLE_STATUS_UNLATCHED" ;
VAL_ 1297 RCM_a011_eventFrontLeftSeatbelt 1 "SEAT_BELT_BUCKLE_STATUS_LATCHED" 0 "SEAT_BELT_BUCKLE_STATUS_UNLATCHED" ;
VAL_ 1297 RCM_a080_eventFrontLeftSeatbelt 1 "SEAT_BELT_BUCKLE_STATUS_LATCHED" 0 "SEAT_BELT_BUCKLE_STATUS_UNLATCHED" ;
VAL_ 1297 RCM_a109_eventFrontLeftSeatbelt 1 "SEAT_BELT_BUCKLE_STATUS_LATCHED" 0 "SEAT_BELT_BUCKLE_STATUS_UNLATCHED" ;
VAL_ 1297 RCM_a099_eventFrontLeftSeatbelt 1 "SEAT_BELT_BUCKLE_STATUS_LATCHED" 0 "SEAT_BELT_BUCKLE_STATUS_UNLATCHED" ;
VAL_ 1297 RCM_a030_eventFrontLeftSeatbelt 1 "SEAT_BELT_BUCKLE_STATUS_LATCHED" 0 "SEAT_BELT_BUCKLE_STATUS_UNLATCHED" ;
VAL_ 1297 RCM_a083_eventFrontLeftSeatbelt 1 "SEAT_BELT_BUCKLE_STATUS_LATCHED" 0 "SEAT_BELT_BUCKLE_STATUS_UNLATCHED" ;
VAL_ 1297 RCM_a056_eventFrontLeftSeatbelt 1 "SEAT_BELT_BUCKLE_STATUS_LATCHED" 0 "SEAT_BELT_BUCKLE_STATUS_UNLATCHED" ;
VAL_ 1297 RCM_a113_eventFrontLeftSeatbelt 1 "SEAT_BELT_BUCKLE_STATUS_LATCHED" 0 "SEAT_BELT_BUCKLE_STATUS_UNLATCHED" ;
VAL_ 1297 RCM_a012_eventFrontLeftSeatbelt 1 "SEAT_BELT_BUCKLE_STATUS_LATCHED" 0 "SEAT_BELT_BUCKLE_STATUS_UNLATCHED" ;
VAL_ 1297 RCM_a029_eventFrontLeftSeatbelt 1 "SEAT_BELT_BUCKLE_STATUS_LATCHED" 0 "SEAT_BELT_BUCKLE_STATUS_UNLATCHED" ;
VAL_ 1297 RCM_a074_eventFrontLeftSeatbelt 1 "SEAT_BELT_BUCKLE_STATUS_LATCHED" 0 "SEAT_BELT_BUCKLE_STATUS_UNLATCHED" ;
VAL_ 1297 RCM_a060_eventFrontLeftSeatbelt 1 "SEAT_BELT_BUCKLE_STATUS_LATCHED" 0 "SEAT_BELT_BUCKLE_STATUS_UNLATCHED" ;
VAL_ 1297 RCM_a024_eventFrontLeftSeatbelt 1 "SEAT_BELT_BUCKLE_STATUS_LATCHED" 0 "SEAT_BELT_BUCKLE_STATUS_UNLATCHED" ;
VAL_ 1297 RCM_a107_eventFrontLeftSeatbelt 1 "SEAT_BELT_BUCKLE_STATUS_LATCHED" 0 "SEAT_BELT_BUCKLE_STATUS_UNLATCHED" ;
VAL_ 1297 RCM_a042_eventFrontLeftSeatbelt 1 "SEAT_BELT_BUCKLE_STATUS_LATCHED" 0 "SEAT_BELT_BUCKLE_STATUS_UNLATCHED" ;
VAL_ 1297 RCM_a006_eventFrontLeftSeatbelt 1 "SEAT_BELT_BUCKLE_STATUS_LATCHED" 0 "SEAT_BELT_BUCKLE_STATUS_UNLATCHED" ;
VAL_ 1297 RCM_a079_eventFrontLeftSeatbelt 1 "SEAT_BELT_BUCKLE_STATUS_LATCHED" 0 "SEAT_BELT_BUCKLE_STATUS_UNLATCHED" ;
VAL_ 1297 RCM_a097_eventFrontLeftSeatbelt 1 "SEAT_BELT_BUCKLE_STATUS_LATCHED" 0 "SEAT_BELT_BUCKLE_STATUS_UNLATCHED" ;
VAL_ 1297 RCM_a018_eventFrontLeftSeatbelt 1 "SEAT_BELT_BUCKLE_STATUS_LATCHED" 0 "SEAT_BELT_BUCKLE_STATUS_UNLATCHED" ;
VAL_ 1297 RCM_a067_eventFrontLeftSeatbelt 1 "SEAT_BELT_BUCKLE_STATUS_LATCHED" 0 "SEAT_BELT_BUCKLE_STATUS_UNLATCHED" ;
VAL_ 1297 RCM_a045_eventFrontLeftSeatbelt 1 "SEAT_BELT_BUCKLE_STATUS_LATCHED" 0 "SEAT_BELT_BUCKLE_STATUS_UNLATCHED" ;
VAL_ 1297 RCM_a023_eventFrontLeftSeatbelt 1 "SEAT_BELT_BUCKLE_STATUS_LATCHED" 0 "SEAT_BELT_BUCKLE_STATUS_UNLATCHED" ;
VAL_ 1297 RCM_a100_eventFrontLeftSeatbelt 1 "SEAT_BELT_BUCKLE_STATUS_LATCHED" 0 "SEAT_BELT_BUCKLE_STATUS_UNLATCHED" ;
VAL_ 1297 RCM_a001_eventFrontLeftSeatbelt 1 "SEAT_BELT_BUCKLE_STATUS_LATCHED" 0 "SEAT_BELT_BUCKLE_STATUS_UNLATCHED" ;
VAL_ 1297 RCM_a090_eventFrontLeftSeatbelt 1 "SEAT_BELT_BUCKLE_STATUS_LATCHED" 0 "SEAT_BELT_BUCKLE_STATUS_UNLATCHED" ;
VAL_ 1297 RCM_a089_eventFrontLeftSeatbelt 1 "SEAT_BELT_BUCKLE_STATUS_LATCHED" 0 "SEAT_BELT_BUCKLE_STATUS_UNLATCHED" ;
VAL_ 1297 RCM_a037_eventFrontLeftSeatbelt 1 "SEAT_BELT_BUCKLE_STATUS_LATCHED" 0 "SEAT_BELT_BUCKLE_STATUS_UNLATCHED" ;
VAL_ 1297 RCM_a015_eventFrontLeftSeatbelt 1 "SEAT_BELT_BUCKLE_STATUS_LATCHED" 0 "SEAT_BELT_BUCKLE_STATUS_UNLATCHED" ;
VAL_ 1297 RCM_a084_eventFrontLeftSeatbelt 1 "SEAT_BELT_BUCKLE_STATUS_LATCHED" 0 "SEAT_BELT_BUCKLE_STATUS_UNLATCHED" ;
VAL_ 1297 RCM_a048_eventFrontLeftSeatbelt 1 "SEAT_BELT_BUCKLE_STATUS_LATCHED" 0 "SEAT_BELT_BUCKLE_STATUS_UNLATCHED" ;
VAL_ 1297 RCM_a073_eventFrontLeftSeatbelt 1 "SEAT_BELT_BUCKLE_STATUS_LATCHED" 0 "SEAT_BELT_BUCKLE_STATUS_UNLATCHED" ;
VAL_ 1297 RCM_a051_eventFrontLeftSeatbelt 1 "SEAT_BELT_BUCKLE_STATUS_LATCHED" 0 "SEAT_BELT_BUCKLE_STATUS_UNLATCHED" ;
VAL_ 1297 RCM_a114_eventFrontLeftSeatbelt 1 "SEAT_BELT_BUCKLE_STATUS_LATCHED" 0 "SEAT_BELT_BUCKLE_STATUS_UNLATCHED" ;
VAL_ 1297 RCM_a070_eventFrontLeftSeatbelt 1 "SEAT_BELT_BUCKLE_STATUS_LATCHED" 0 "SEAT_BELT_BUCKLE_STATUS_UNLATCHED" ;
VAL_ 1297 RCM_a052_eventFrontLeftSeatbelt 1 "SEAT_BELT_BUCKLE_STATUS_LATCHED" 0 "SEAT_BELT_BUCKLE_STATUS_UNLATCHED" ;
VAL_ 1297 RCM_a117_eventFrontLeftSeatbelt 1 "SEAT_BELT_BUCKLE_STATUS_LATCHED" 0 "SEAT_BELT_BUCKLE_STATUS_UNLATCHED" ;
VAL_ 1297 RCM_a034_eventFrontLeftSeatbelt 1 "SEAT_BELT_BUCKLE_STATUS_LATCHED" 0 "SEAT_BELT_BUCKLE_STATUS_UNLATCHED" ;
VAL_ 1297 RCM_a016_eventFrontLeftSeatbelt 1 "SEAT_BELT_BUCKLE_STATUS_LATCHED" 0 "SEAT_BELT_BUCKLE_STATUS_UNLATCHED" ;
VAL_ 1297 RCM_a087_eventFrontLeftSeatbelt 1 "SEAT_BELT_BUCKLE_STATUS_LATCHED" 0 "SEAT_BELT_BUCKLE_STATUS_UNLATCHED" ;
VAL_ 1297 RCM_a069_eventFrontLeftSeatbelt 1 "SEAT_BELT_BUCKLE_STATUS_LATCHED" 0 "SEAT_BELT_BUCKLE_STATUS_UNLATCHED" ;
VAL_ 1297 RCM_a031_eventFrontLeftSeatbelt 1 "SEAT_BELT_BUCKLE_STATUS_LATCHED" 0 "SEAT_BELT_BUCKLE_STATUS_UNLATCHED" ;
VAL_ 1297 RCM_a013_eventFrontLeftSeatbelt 1 "SEAT_BELT_BUCKLE_STATUS_LATCHED" 0 "SEAT_BELT_BUCKLE_STATUS_UNLATCHED" ;
VAL_ 1297 RCM_a028_eventFrontLeftSeatbelt 1 "SEAT_BELT_BUCKLE_STATUS_LATCHED" 0 "SEAT_BELT_BUCKLE_STATUS_UNLATCHED" ;
VAL_ 1297 RCM_a075_eventFrontLeftSeatbelt 1 "SEAT_BELT_BUCKLE_STATUS_LATCHED" 0 "SEAT_BELT_BUCKLE_STATUS_UNLATCHED" ;
VAL_ 1297 RCM_a057_eventFrontLeftSeatbelt 1 "SEAT_BELT_BUCKLE_STATUS_LATCHED" 0 "SEAT_BELT_BUCKLE_STATUS_UNLATCHED" ;
VAL_ 1297 RCM_a112_eventFrontLeftSeatbelt 1 "SEAT_BELT_BUCKLE_STATUS_LATCHED" 0 "SEAT_BELT_BUCKLE_STATUS_UNLATCHED" ;
VAL_ 1297 RCM_a082_eventFrontLeftSeatbelt 1 "SEAT_BELT_BUCKLE_STATUS_LATCHED" 0 "SEAT_BELT_BUCKLE_STATUS_UNLATCHED" ;
VAL_ 1297 RCM_a041_eventFrontLeftSeatbelt 1 "SEAT_BELT_BUCKLE_STATUS_LATCHED" 0 "SEAT_BELT_BUCKLE_STATUS_UNLATCHED" ;
VAL_ 1297 RCM_a005_eventFrontLeftSeatbelt 1 "SEAT_BELT_BUCKLE_STATUS_LATCHED" 0 "SEAT_BELT_BUCKLE_STATUS_UNLATCHED" ;
VAL_ 1297 RCM_a058_eventFrontLeftSeatbelt 1 "SEAT_BELT_BUCKLE_STATUS_LATCHED" 0 "SEAT_BELT_BUCKLE_STATUS_UNLATCHED" ;
VAL_ 1297 RCM_a094_eventFrontLeftSeatbelt 1 "SEAT_BELT_BUCKLE_STATUS_LATCHED" 0 "SEAT_BELT_BUCKLE_STATUS_UNLATCHED" ;
VAL_ 1297 RCM_a063_eventFrontLeftSeatbelt 1 "SEAT_BELT_BUCKLE_STATUS_LATCHED" 0 "SEAT_BELT_BUCKLE_STATUS_UNLATCHED" ;
VAL_ 1297 RCM_a027_eventFrontLeftSeatbelt 1 "SEAT_BELT_BUCKLE_STATUS_LATCHED" 0 "SEAT_BELT_BUCKLE_STATUS_UNLATCHED" ;
VAL_ 1297 RCM_a104_eventFrontLeftSeatbelt 1 "SEAT_BELT_BUCKLE_STATUS_LATCHED" 0 "SEAT_BELT_BUCKLE_STATUS_UNLATCHED" ;
VAL_ 1297 RCM_a088_eventFrontLeftSeatbelt 1 "SEAT_BELT_BUCKLE_STATUS_LATCHED" 0 "SEAT_BELT_BUCKLE_STATUS_UNLATCHED" ;
VAL_ 1297 RCM_a066_eventFrontLeftSeatbelt 1 "SEAT_BELT_BUCKLE_STATUS_LATCHED" 0 "SEAT_BELT_BUCKLE_STATUS_UNLATCHED" ;
VAL_ 1297 RCM_a044_eventFrontLeftSeatbelt 1 "SEAT_BELT_BUCKLE_STATUS_LATCHED" 0 "SEAT_BELT_BUCKLE_STATUS_UNLATCHED" ;
VAL_ 1297 RCM_a091_eventFrontLeftSeatbelt 1 "SEAT_BELT_BUCKLE_STATUS_LATCHED" 0 "SEAT_BELT_BUCKLE_STATUS_UNLATCHED" ;
VAL_ 1297 RCM_a019_eventFrontLeftSeatbelt 1 "SEAT_BELT_BUCKLE_STATUS_LATCHED" 0 "SEAT_BELT_BUCKLE_STATUS_UNLATCHED" ;
VAL_ 1297 RCM_a022_eventFrontLeftSeatbelt 1 "SEAT_BELT_BUCKLE_STATUS_LATCHED" 0 "SEAT_BELT_BUCKLE_STATUS_UNLATCHED" ;
VAL_ 1297 RCM_a101_eventFrontLeftSeatbelt 1 "SEAT_BELT_BUCKLE_STATUS_LATCHED" 0 "SEAT_BELT_BUCKLE_STATUS_UNLATCHED" ;
VAL_ 1297 RCM_a000_eventFrontLeftSeatbelt 1 "SEAT_BELT_BUCKLE_STATUS_LATCHED" 0 "SEAT_BELT_BUCKLE_STATUS_UNLATCHED" ;
VAL_ 1297 RCM_a118_eventFrontLeftSeatbelt 1 "SEAT_BELT_BUCKLE_STATUS_LATCHED" 0 "SEAT_BELT_BUCKLE_STATUS_UNLATCHED" ;
VAL_ 1297 RCM_a047_eventFrontLeftSeatbelt 1 "SEAT_BELT_BUCKLE_STATUS_LATCHED" 0 "SEAT_BELT_BUCKLE_STATUS_UNLATCHED" ;
VAL_ 1297 RCM_a003_eventFrontLeftSeatbelt 1 "SEAT_BELT_BUCKLE_STATUS_LATCHED" 0 "SEAT_BELT_BUCKLE_STATUS_UNLATCHED" ;
VAL_ 1297 RCM_a092_eventFrontLeftSeatbelt 1 "SEAT_BELT_BUCKLE_STATUS_LATCHED" 0 "SEAT_BELT_BUCKLE_STATUS_UNLATCHED" ;
VAL_ 1297 RCM_a065_eventFrontLeftSeatbelt 1 "SEAT_BELT_BUCKLE_STATUS_LATCHED" 0 "SEAT_BELT_BUCKLE_STATUS_UNLATCHED" ;
VAL_ 1297 RCM_a021_eventFrontLeftSeatbelt 1 "SEAT_BELT_BUCKLE_STATUS_LATCHED" 0 "SEAT_BELT_BUCKLE_STATUS_UNLATCHED" ;
VAL_ 1297 RCM_a102_eventFrontLeftSeatbelt 1 "SEAT_BELT_BUCKLE_STATUS_LATCHED" 0 "SEAT_BELT_BUCKLE_STATUS_UNLATCHED" ;
VAL_ 1297 RCM_a038_eventFrontLeftSeatbelt 1 "SEAT_BELT_BUCKLE_STATUS_LATCHED" 0 "SEAT_BELT_BUCKLE_STATUS_UNLATCHED" ;
VAL_ 1297 RCM_a072_eventIDFsignal 1 "RCM_DAS_IDF_ACTIVE" 0 "RCM_DAS_IDF_NOT_ACTIVE" ;
VAL_ 1297 RCM_a036_eventIDFsignal 1 "RCM_DAS_IDF_ACTIVE" 0 "RCM_DAS_IDF_NOT_ACTIVE" ;
VAL_ 1297 RCM_a085_eventIDFsignal 1 "RCM_DAS_IDF_ACTIVE" 0 "RCM_DAS_IDF_NOT_ACTIVE" ;
VAL_ 1297 RCM_a049_eventIDFsignal 1 "RCM_DAS_IDF_ACTIVE" 0 "RCM_DAS_IDF_NOT_ACTIVE" ;
VAL_ 1297 RCM_a050_eventIDFsignal 1 "RCM_DAS_IDF_ACTIVE" 0 "RCM_DAS_IDF_NOT_ACTIVE" ;
VAL_ 1297 RCM_a115_eventIDFsignal 1 "RCM_DAS_IDF_ACTIVE" 0 "RCM_DAS_IDF_NOT_ACTIVE" ;
VAL_ 1297 RCM_a014_eventIDFsignal 1 "RCM_DAS_IDF_ACTIVE" 0 "RCM_DAS_IDF_NOT_ACTIVE" ;
VAL_ 1297 RCM_a075_eventIDFsignal 1 "RCM_DAS_IDF_ACTIVE" 0 "RCM_DAS_IDF_NOT_ACTIVE" ;
VAL_ 1297 RCM_a013_eventIDFsignal 1 "RCM_DAS_IDF_ACTIVE" 0 "RCM_DAS_IDF_NOT_ACTIVE" ;
VAL_ 1297 RCM_a031_eventIDFsignal 1 "RCM_DAS_IDF_ACTIVE" 0 "RCM_DAS_IDF_NOT_ACTIVE" ;
VAL_ 1297 RCM_a082_eventIDFsignal 1 "RCM_DAS_IDF_ACTIVE" 0 "RCM_DAS_IDF_NOT_ACTIVE" ;
VAL_ 1297 RCM_a028_eventIDFsignal 1 "RCM_DAS_IDF_ACTIVE" 0 "RCM_DAS_IDF_NOT_ACTIVE" ;
VAL_ 1297 RCM_a057_eventIDFsignal 1 "RCM_DAS_IDF_ACTIVE" 0 "RCM_DAS_IDF_NOT_ACTIVE" ;
VAL_ 1297 RCM_a112_eventIDFsignal 1 "RCM_DAS_IDF_ACTIVE" 0 "RCM_DAS_IDF_NOT_ACTIVE" ;
VAL_ 1297 RCM_a061_eventIDFsignal 1 "RCM_DAS_IDF_ACTIVE" 0 "RCM_DAS_IDF_NOT_ACTIVE" ;
VAL_ 1297 RCM_a043_eventIDFsignal 1 "RCM_DAS_IDF_ACTIVE" 0 "RCM_DAS_IDF_NOT_ACTIVE" ;
VAL_ 1297 RCM_a078_eventIDFsignal 1 "RCM_DAS_IDF_ACTIVE" 0 "RCM_DAS_IDF_NOT_ACTIVE" ;
VAL_ 1297 RCM_a007_eventIDFsignal 1 "RCM_DAS_IDF_ACTIVE" 0 "RCM_DAS_IDF_NOT_ACTIVE" ;
VAL_ 1297 RCM_a096_eventIDFsignal 1 "RCM_DAS_IDF_ACTIVE" 0 "RCM_DAS_IDF_NOT_ACTIVE" ;
VAL_ 1297 RCM_a025_eventIDFsignal 1 "RCM_DAS_IDF_ACTIVE" 0 "RCM_DAS_IDF_NOT_ACTIVE" ;
VAL_ 1297 RCM_a106_eventIDFsignal 1 "RCM_DAS_IDF_ACTIVE" 0 "RCM_DAS_IDF_NOT_ACTIVE" ;
VAL_ 1297 RCM_a004_eventIDFsignal 1 "RCM_DAS_IDF_ACTIVE" 0 "RCM_DAS_IDF_NOT_ACTIVE" ;
VAL_ 1297 RCM_a059_eventIDFsignal 1 "RCM_DAS_IDF_ACTIVE" 0 "RCM_DAS_IDF_NOT_ACTIVE" ;
VAL_ 1297 RCM_a040_eventIDFsignal 1 "RCM_DAS_IDF_ACTIVE" 0 "RCM_DAS_IDF_NOT_ACTIVE" ;
VAL_ 1297 RCM_a062_eventIDFsignal 1 "RCM_DAS_IDF_ACTIVE" 0 "RCM_DAS_IDF_NOT_ACTIVE" ;
VAL_ 1297 RCM_a105_eventIDFsignal 1 "RCM_DAS_IDF_ACTIVE" 0 "RCM_DAS_IDF_NOT_ACTIVE" ;
VAL_ 1297 RCM_a026_eventIDFsignal 1 "RCM_DAS_IDF_ACTIVE" 0 "RCM_DAS_IDF_NOT_ACTIVE" ;
VAL_ 1297 RCM_a095_eventIDFsignal 1 "RCM_DAS_IDF_ACTIVE" 0 "RCM_DAS_IDF_NOT_ACTIVE" ;
VAL_ 1297 RCM_a018_eventIDFsignal 1 "RCM_DAS_IDF_ACTIVE" 0 "RCM_DAS_IDF_NOT_ACTIVE" ;
VAL_ 1297 RCM_a045_eventIDFsignal 1 "RCM_DAS_IDF_ACTIVE" 0 "RCM_DAS_IDF_NOT_ACTIVE" ;
VAL_ 1297 RCM_a067_eventIDFsignal 1 "RCM_DAS_IDF_ACTIVE" 0 "RCM_DAS_IDF_NOT_ACTIVE" ;
